VERSION ""

NS_ :

BS_:

BU_: ESM HIB HIP HIS SaGE CBC DASM DIAGNOST EBCM ECM EPS ESC ESL ETM HALF HCP IC OCM ORC PTS RF_HUB SCCM SGW

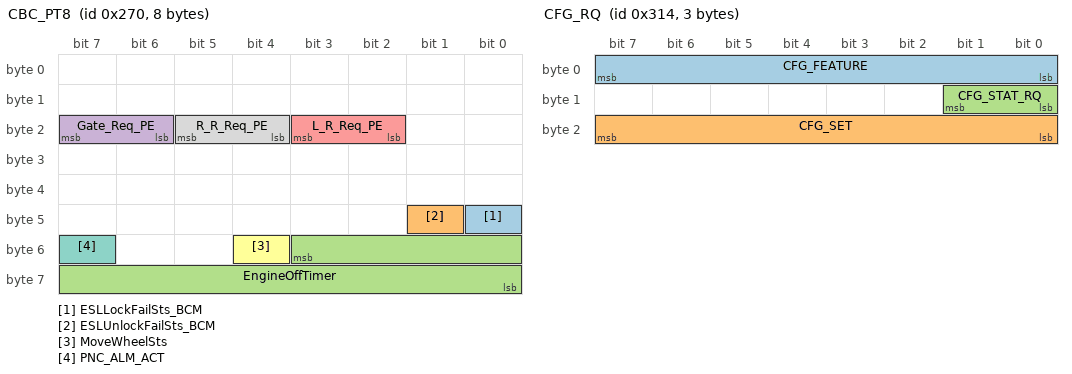
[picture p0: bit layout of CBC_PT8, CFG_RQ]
BO_ 624 CBC_PT8: 8 CBC
 SG_ ESLLockFailSts_BCM : 40|1@1+ (1,0) [0|0] ""  IC,SGW
 SG_ ESLUnlockFailSts_BCM : 41|1@1+ (1,0) [0|0] ""  IC,SGW
 SG_ EngineOffTimer : 51|12@0+ (1,0) [0|4080] "min"  ECM,ETM,SGW
 SG_ Gate_Req_PE : 22|2@1+ (1,0) [0|0] ""  RF_HUB,SGW
 SG_ L_R_Req_PE : 18|2@1+ (1,0) [0|0] ""  RF_HUB,SGW
 SG_ MoveWheelSts : 52|1@1+ (1,0) [0|0] ""  IC,SGW
 SG_ PNC_ALM_ACT : 55|1@1+ (1,0) [0|0] ""  SGW
 SG_ R_R_Req_PE : 20|2@1+ (1,0) [0|0] ""  RF_HUB,SGW

BO_ 456 CBC_VTA: 4 CBC
 SG_ VTA_STAT : 0|3@1+ (1,0) [0|0] ""  ETM,RF_HUB,SGW

BO_ 788 CFG_RQ: 3 CBC
 SG_ CFG_FEATURE : 0|8@1+ (1,0) [0|0] ""  DASM,ECM,ESC,HALF,IC,PTS,RF_HUB,SGW
 SG_ CFG_SET : 16|8@1+ (1,0) [0|255] ""  DASM,ECM,ESC,HALF,IC,PTS,RF_HUB,SGW
 SG_ CFG_STAT_RQ : 8|2@1+ (1,0) [0|0] ""  DASM,ECM,ESC,HALF,IC,PTS,RF_HUB,SGW

BO_ 856 COMPASS_A1: 4 CBC
 SG_ CMP_DIR : 0|4@1+ (1,0) [0|0] ""  IC,SGW

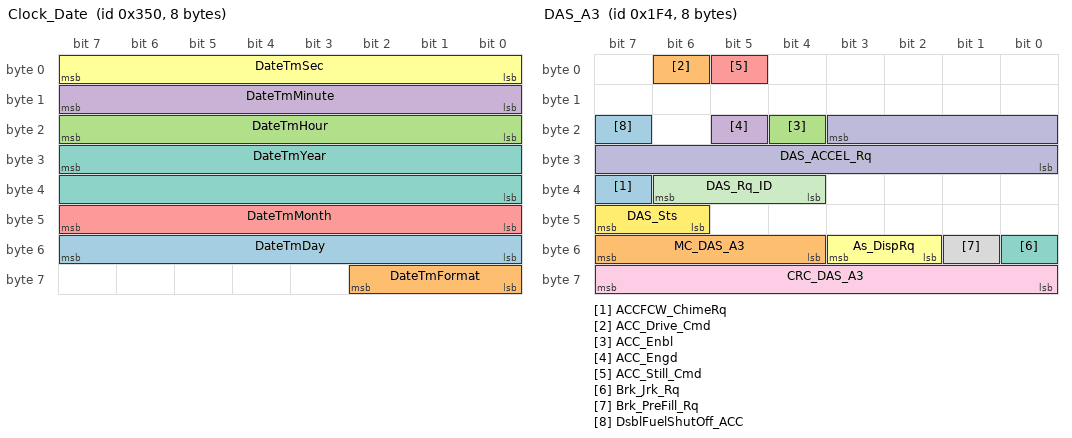
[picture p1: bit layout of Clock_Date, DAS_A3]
BO_ 848 Clock_Date: 8 CBC
 SG_ DateTmDay : 48|8@1+ (1,0) [1|31] "Days"  IC,RF_HUB,SGW
 SG_ DateTmFormat : 56|3@1+ (1,0) [0|0] ""  IC,SGW
 SG_ DateTmHour : 16|8@1+ (1,0) [0|23] "Hours"  IC,RF_HUB,SGW
 SG_ DateTmMinute : 8|8@1+ (1,0) [0|59] "min"  IC,RF_HUB,SGW
 SG_ DateTmMonth : 40|8@1+ (1,0) [1|12] "Months"  IC,RF_HUB,SGW
 SG_ DateTmSec : 0|8@1+ (1,0) [0|59] "sec"  IC,SGW
 SG_ DateTmYear : 31|16@0+ (1,0) [0|65534] "Years"  IC,RF_HUB,SGW

BO_ 500 DAS_A3: 8 DASM
 SG_ ACCFCW_ChimeRq : 39|1@1+ (1,0) [0|0] ""  IC,SGW
 SG_ ACC_Drive_Cmd : 6|1@1+ (1,0) [0|0] ""  SGW
 SG_ ACC_Enbl : 20|1@1+ (1,0) [0|0] ""  IC,SGW
 SG_ ACC_Engd : 21|1@1+ (1,0) [0|0] ""  IC,SGW
 SG_ ACC_Still_Cmd : 5|1@1+ (1,0) [0|0] ""  ORC,SGW
 SG_ As_DispRq : 50|2@1+ (1,0) [0|0] ""  HALF,IC,ORC,SGW
 SG_ Brk_Jrk_Rq : 48|1@1+ (1,0) [0|0] ""  SGW
 SG_ Brk_PreFill_Rq : 49|1@1+ (1,0) [0|0] ""  SGW
 SG_ CRC_DAS_A3 : 56|8@1+ (1,0) [0|0] ""  SGW
 SG_ DAS_ACCEL_Rq : 19|12@0+ (0.004885,-16) [-16|4] "m/s²"  ORC,SGW
 SG_ DAS_Rq_ID : 36|3@1+ (1,0) [0|0] ""  SGW
 SG_ DAS_Sts : 46|2@1+ (1,0) [0|0] ""  SGW
 SG_ DsblFuelShutOff_ACC : 23|1@1+ (1,0) [0|0] ""  SGW
 SG_ MC_DAS_A3 : 52|4@1+ (1,0) [0|15] ""  HIB,ECM,SGW

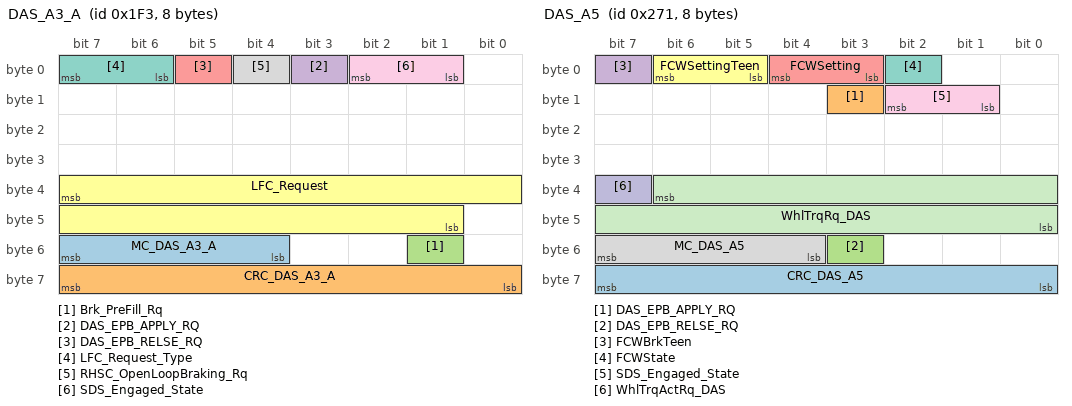
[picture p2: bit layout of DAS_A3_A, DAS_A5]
BO_ 499 DAS_A3_A: 8 HIB
 SG_ MC_DAS_A3_A : 52|4@1+ (1,0) [0|15] ""  EBCM,ESC
 SG_ CRC_DAS_A3_A : 56|8@1+ (1,0) [0|255] ""  EBCM,ESC
 SG_ Brk_PreFill_Rq : 49|1@1+ (1,0) [0|0] ""  SGW
 SG_ DAS_EPB_APPLY_RQ : 3|1@1+ (1,0) [0|0] "" Vector__XXX
 SG_ DAS_EPB_RELSE_RQ : 5|1@1+ (1,0) [0|0] "" Vector__XXX
 SG_ LFC_Request : 39|15@0+ (2,-65534) [-65534|0] ""  EBCM,ESC,SGW
 SG_ LFC_Request_Type : 6|2@1+ (1,0) [0|0] ""  EBCM,ESC,SGW
 SG_ RHSC_OpenLoopBraking_Rq : 4|1@1+ (1,0) [0|0] ""  EBCM,ESC,SGW
 SG_ SDS_Engaged_State : 1|2@1+ (1,0) [0|0] ""  EBCM,ESC

BO_ 501 DAS_A4: 8 DASM
 SG_ ACCFaulted : 50|1@1+ (1,0) [0|0] ""  ETM,IC,ORC,SGW
 SG_ ACCNA_DASMSts : 52|1@1+ (1,0) [0|0] ""  IC,SGW
 SG_ ACCOnOff : 36|3@1+ (1,0) [0|0] ""  IC,ORC,SGW
 SG_ ACC_HMI_SCRN_REQ : 31|1@1+ (1,0) [0|0] ""  IC,SGW
 SG_ ACConlyNA_DASMSts : 48|1@1+ (1,0) [0|0] ""  ETM,IC,SGW
 SG_ CIPV_Fused : 30|1@1+ (1,0) [0|0] ""  ORC,SGW
 SG_ CameraBlocked : 54|1@1+ (1,0) [0|0] ""  IC,SGW
 SG_ CameraFailure : 55|1@1+ (1,0) [0|0] ""  IC,SGW
 SG_ FCWBrakingOff : 47|1@1+ (1,0) [0|0] ""  IC,SGW
 SG_ FCW_BrkOn : 29|1@1+ (1,0) [0|0] ""  CBC,ORC,SGW
 SG_ FCW_Error : 26|2@1+ (1,0) [0|0] ""  ETM,IC,ORC,SGW
 SG_ FCWonlyNA_DASMSts : 51|1@1+ (1,0) [0|0] ""  IC,SGW
 SG_ HMI_Screens : 0|8@1+ (1,0) [0|254] "Text"  IC,SGW
 SG_ NCCNA_DASMSts : 53|1@1+ (1,0) [0|0] ""  IC,SGW
 SG_ NCConlyNA_DASMSts : 49|1@1+ (1,0) [0|0] ""  IC,SGW
 SG_ ObjIntrstDist : 56|8@1+ (1,0) [0|253] "m"  ORC,SGW
 SG_ RadarBlocked : 46|1@1+ (1,0) [0|0] ""  IC,ORC,SGW
 SG_ SetSpeed_KPH : 8|8@1+ (1,0) [0|250] "km/h"  ECM,IC,SGW
 SG_ SetSpeed_MPH : 16|8@1+ (1,0) [0|250] "mph"  IC,ORC,SGW
 SG_ Sm_ICON_Dspl : 40|6@1+ (1,0) [0|0] ""  IC,SGW

BO_ 625 DAS_A5: 8 DASM
 SG_ CRC_DAS_A5 : 56|8@1+ (1,0) [0|255] ""  SGW
 SG_ DAS_EPB_APPLY_RQ : 11|1@1+ (1,0) [0|0] ""  SGW
 SG_ DAS_EPB_RELSE_RQ : 51|1@1+ (1,0) [0|0] ""  HCP,SGW
 SG_ FCWBrkTeen : 7|1@1+ (1,0) [0|0] ""  CBC,ORC,SGW
 SG_ FCWSetting : 3|2@1+ (1,0) [0|0] ""  CBC,ORC,SGW
 SG_ FCWSettingTeen : 5|2@1+ (1,0) [0|0] ""  CBC,ORC,SGW
 SG_ FCWState : 2|1@1+ (1,0) [0|0] ""  CBC,IC,ORC,SGW
 SG_ MC_DAS_A5 : 52|4@1+ (1,0) [0|15] ""  SGW
 SG_ SDS_Engaged_State : 9|2@1+ (1,0) [0|0] ""  HCP,SGW
 SG_ WhlTrqActRq_DAS : 39|1@1+ (1,0) [0|0] ""  SGW
 SG_ WhlTrqRq_DAS : 38|15@0+ (1,-7767) [-7767|24999] "Nm"  SGW

BO_ 2015 DG_RQ_GLOBAL: 8 DIAGNOST
 SG_ DG_RQ_GLOBAL : 7|64@0+ (1,0) [0|0] ""  EBCM,ECM,ESC,ETM,HCP

BO_ 1089 DG_RQ_GLOBAL_UDS: 8 DIAGNOST
 SG_ DG_RQ_GLOBAL_UDS : 7|64@0+ (1,0) [0|0] ""  HIB,CBC,DASM,EBCM,ECM,EPS,ESC,ESL,ETM,HALF,HCP,IC,OCM,ORC,PTS,RF_HUB,SCCM

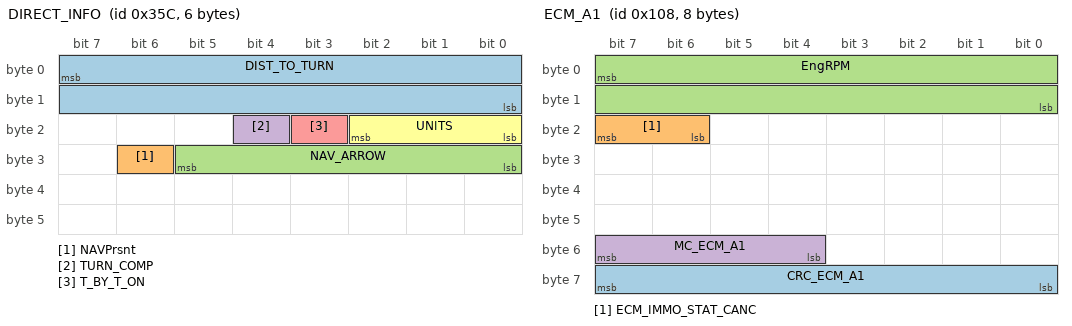
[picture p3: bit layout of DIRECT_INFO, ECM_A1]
BO_ 860 DIRECT_INFO: 6 CBC
 SG_ DIST_TO_TURN : 7|16@0+ (1,0) [0|65534] ""  IC,SGW
 SG_ NAVPrsnt : 30|1@1+ (1,0) [0|0] ""  IC,SGW
 SG_ NAV_ARROW : 24|6@1+ (1,0) [1|63] "Arrow"  IC,SGW
 SG_ TURN_COMP : 20|1@1+ (1,0) [0|0] ""  IC,SGW
 SG_ T_BY_T_ON : 19|1@1+ (1,0) [0|0] ""  IC,SGW
 SG_ UNITS : 16|3@1+ (1,0) [0|0] ""  IC,SGW

BO_ 1900 D_RQ_AHCP: 8 DIAGNOST
 SG_ D_RQ_AHCP : 7|64@0+ (1,0) [0|0] ""  HCP

BO_ 1898 D_RQ_APM: 8 DIAGNOST
 SG_ D_RQ_APM : 7|64@0+ (1,0) [0|0] ""  HCP

BO_ 2023 D_RQ_BPCM: 8 DIAGNOST
 SG_ D_RQ_BPCM : 7|64@0+ (1,0) [0|0] ""  HCP

BO_ 2020 D_RQ_BSMO: 8 DIAGNOST
 SG_ D_RQ_BSMO : 7|64@0+ (1,0) [0|0] ""  ESC

BO_ 1568 D_RQ_CBC: 8 DIAGNOST
 SG_ D_RQ_CBC : 7|64@0+ (1,0) [0|0] ""  CBC

BO_ 1875 D_RQ_DASM: 8 DIAGNOST
 SG_ D_RQ_DASM : 7|64@0+ (1,0) [0|0] ""  HIB,DASM

BO_ 1899 D_RQ_EAC: 8 DIAGNOST
 SG_ D_RQ_EAC : 7|64@0+ (1,0) [0|0] ""  HCP

BO_ 2019 D_RQ_EBCM: 8 DIAGNOST
 SG_ D_RQ_EBCM : 7|64@0+ (1,0) [0|0] ""  EBCM

BO_ 2016 D_RQ_ECM: 8 DIAGNOST
 SG_ D_RQ_ECM : 7|64@0+ (1,0) [0|0] ""  ECM

BO_ 1882 D_RQ_EPS: 8 DIAGNOST
 SG_ D_RQ_EPS : 7|64@0+ (1,0) [0|0] ""  EPS

BO_ 1864 D_RQ_ESL: 8 DIAGNOST
 SG_ D_RQ_ESL : 7|64@0+ (1,0) [0|0] ""  ESL

BO_ 1865 D_RQ_ESM: 8 DIAGNOST
 SG_ D_RQ_ESM : 7|64@0+ (1,0) [0|0] "" Vector__XXX

BO_ 2018 D_RQ_HCP: 8 DIAGNOST
 SG_ D_RQ_HCP : 7|64@0+ (1,0) [0|0] ""  HCP

BO_ 1892 D_RQ_HaLF: 8 DIAGNOST
 SG_ D_RQ_HaLF : 7|64@0+ (1,0) [0|0] ""  HALF

BO_ 1858 D_RQ_IC: 8 DIAGNOST
 SG_ D_RQ_IC : 7|64@0+ (1,0) [0|0] ""  IC

BO_ 1902 D_RQ_OBCM: 8 DIAGNOST
 SG_ D_RQ_OBCM : 7|64@0+ (1,0) [0|0] ""  HCP

BO_ 1886 D_RQ_OCM: 8 DIAGNOST
 SG_ D_RQ_OCM : 7|64@0+ (1,0) [0|0] ""  OCM

BO_ 1860 D_RQ_ORC: 8 DIAGNOST
 SG_ D_RQ_ORC : 7|64@0+ (1,0) [0|0] ""  ORC

BO_ 1890 D_RQ_PTS: 8 DIAGNOST
 SG_ D_RQ_PTS : 7|64@0+ (1,0) [0|0] ""  PTS

BO_ 1856 D_RQ_RF_HUB: 8 DIAGNOST
 SG_ D_RQ_RF_HUB : 7|64@0+ (1,0) [0|0] ""  RF_HUB

BO_ 1891 D_RQ_SCCM: 8 DIAGNOST
 SG_ D_RQ_SCCM : 7|64@0+ (1,0) [0|0] ""  SCCM

BO_ 1150 D_RQ_SGW: 8 DIAGNOST
 SG_ D_RQ_SGW : 7|64@0+ (1,0) [0|0] ""  SGW

BO_ 1260 D_RS_AHCP: 8 HCP
 SG_ D_RS_AHCP : 7|64@0+ (1,0) [0|0] ""  DIAGNOST,ETM,SGW

BO_ 1258 D_RS_APM: 8 HCP
 SG_ D_RS_APM : 7|64@0+ (1,0) [0|0] ""  DIAGNOST,ETM,SGW

BO_ 2031 D_RS_BPCM: 8 HCP
 SG_ D_RS_BPCM : 7|64@0+ (1,0) [0|0] ""  DIAGNOST,ETM,SGW

BO_ 2028 D_RS_BSMO: 8 ESC
 SG_ D_RS_BSMO : 7|64@0+ (1,0) [0|0] ""  DIAGNOST,ETM,SGW

BO_ 1284 D_RS_CBC: 8 CBC
 SG_ D_RS_CBC : 7|64@0+ (1,0) [0|0] ""  DIAGNOST,ETM,SGW

BO_ 1235 D_RS_DASM: 8 DASM
 SG_ D_RS_DASM : 7|64@0+ (1,0) [0|0] ""  DIAGNOST,ETM,SGW

BO_ 1259 D_RS_EAC: 8 HCP
 SG_ D_RS_EAC : 7|64@0+ (1,0) [0|0] ""  DIAGNOST,ETM,SGW

BO_ 2027 D_RS_EBCM: 8 EBCM
 SG_ D_RS_EBCM : 7|64@0+ (1,0) [0|0] ""  DIAGNOST,ETM,SGW

BO_ 2024 D_RS_ECM: 8 ECM
 SG_ D_RS_ECM : 7|64@0+ (1,0) [0|0] ""  DIAGNOST,ETM,SGW

BO_ 1242 D_RS_EPS: 8 EPS
 SG_ D_RS_EPS : 7|64@0+ (1,0) [0|0] ""  DIAGNOST,ETM,SGW

BO_ 1224 D_RS_ESL: 8 ESL
 SG_ D_RS_ESL : 7|64@0+ (1,0) [0|0] ""  DIAGNOST,SGW

BO_ 1225 D_RS_ESM: 8 ESM
 SG_ D_RS_ESM : 7|64@0+ (1,0) [0|0] ""  DIAGNOST,ETM,SGW

BO_ 2026 D_RS_HCP: 8 HCP
 SG_ D_RS_HCP : 7|64@0+ (1,0) [0|0] ""  DIAGNOST,ETM,SGW

BO_ 1252 D_RS_HaLF: 8 HALF
 SG_ D_RS_HaLF : 7|64@0+ (1,0) [0|0] ""  DIAGNOST,ETM,SGW

BO_ 1218 D_RS_IC: 8 IC
 SG_ D_RS_IC : 7|64@0+ (1,0) [0|0] ""  DIAGNOST,ETM,SGW

BO_ 1262 D_RS_OBCM: 8 HCP
 SG_ D_RS_OBCM : 7|64@0+ (1,0) [0|0] ""  DIAGNOST,ETM,SGW

BO_ 1246 D_RS_OCM: 8 OCM
 SG_ D_RS_OCM : 7|64@0+ (1,0) [0|0] ""  DIAGNOST,ETM,SGW

BO_ 1220 D_RS_ORC: 8 ORC
 SG_ D_RS_ORC : 7|64@0+ (1,0) [0|0] ""  DIAGNOST,ETM,SGW

BO_ 1250 D_RS_PTS: 8 PTS
 SG_ D_RS_PTS : 7|64@0+ (1,0) [0|0] ""  DIAGNOST,ETM,SGW

BO_ 1216 D_RS_RF_HUB: 8 RF_HUB
 SG_ D_RS_RF_HUB : 7|64@0+ (1,0) [0|0] ""  DIAGNOST,ETM,SGW

BO_ 1251 D_RS_SCCM: 8 SCCM
 SG_ D_RS_SCCM : 7|64@0+ (1,0) [0|0] ""  DIAGNOST,ETM,SGW

BO_ 1151 D_RS_SGW: 8 SGW
 SG_ D_RS_SGW : 7|64@0+ (1,0) [0|0] ""  DIAGNOST,ETM

BO_ 653 EBCM_C1: 8 EBCM
 SG_ BrakePedalApplied : 4|1@1+ (1,0) [0|0] ""  ECM,ESC,SGW
 SG_ BrakePedalAppliedV : 5|1@1+ (1,0) [0|0] ""  ECM,ESC,SGW
 SG_ BrakePedalTravelSensor : 8|8@1+ (0.4,0) [0|100] "%"  ECM,ESC,SGW
 SG_ BrakePedalTravelSensorV : 46|1@1+ (1,0) [0|0] ""  ECM,ESC,SGW
 SG_ BrakeSysStateSec : 19|3@1+ (1,0) [0|0] ""  ESC,SGW
 SG_ BrkPdl_Flt_2 : 31|1@1+ (1,0) [0|0] ""  SGW
 SG_ BrkPdl_Stat_2 : 22|2@1+ (1,0) [0|0] ""  SGW
 SG_ Brk_Stat_2 : 48|2@1+ (1,0) [0|0] ""  CBC,SGW
 SG_ CRC_EBCM_C1 : 56|8@1+ (1,0) [0|0] ""  ESC,SGW
 SG_ DAS_RqActv : 1|3@1+ (1,0) [0|0] ""  SGW
 SG_ DriverBrakingTrue_EBCM : 0|1@1+ (1,0) [0|0] ""  ESC,SGW
 SG_ EBCMSysEmsMlfAtv : 7|1@1+ (1,0) [0|0] ""  SGW
 SG_ EBCM_BrakeState : 16|3@1+ (1,0) [0|0] ""  ESC,SGW
 SG_ EstBrakeTorqueAppliedSec : 30|15@0+ (2,-65534) [-65534|0] "Nm"  SGW
 SG_ MC_EBCM_C1 : 52|4@1+ (1,0) [0|15] ""  ESC,SGW
 SG_ MIL_OnRq_EBCM : 6|1@1+ (1,0) [0|0] ""  ECM,SGW
 SG_ SDS_Engaged_State_EBCM : 50|2@1+ (1,0) [0|0] ""  SGW
 SG_ ThermalCapacitySec : 40|6@1+ (1.5873,0) [0|100] "%"  SGW

BO_ 264 ECM_A1: 8 ECM
 SG_ CRC_ECM_A1 : 56|8@1+ (1,0) [0|0] ""  HIB,DASM,ESC,HALF,SGW
 SG_ ECM_IMMO_STAT_CANC : 22|2@1+ (1,0) [0|0] ""  CBC,HCP,SGW
 SG_ EngRPM : 7|16@0+ (1,0) [0|65534] "rpm"  HIB,CBC,DASM,EBCM,EPS,ESC,ETM,HALF,IC,ORC,RF_HUB,SGW
 SG_ MC_ECM_A1 : 52|4@1+ (1,0) [0|15] ""  HIB,DASM,ESC,HALF,SGW

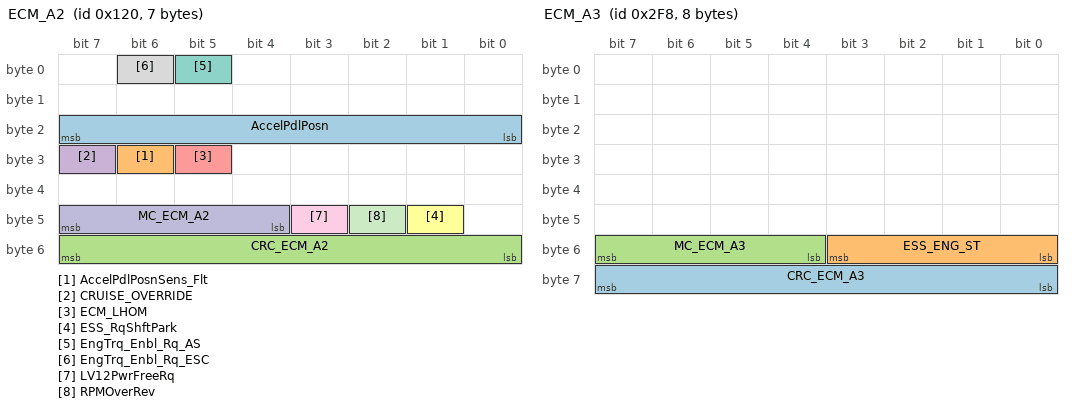
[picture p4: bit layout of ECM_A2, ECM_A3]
BO_ 288 ECM_A2: 7 ECM
 SG_ AccelPdlPosn : 16|8@1+ (0.4,0) [0|100] "%"  HIB,CBC,ESC,ETM,HALF,SGW
 SG_ AccelPdlPosnSens_Flt : 30|1@1+ (1,0) [0|0] ""  HIB,CBC,DASM,ESC,HALF,SGW
 SG_ CRC_ECM_A2 : 48|8@1+ (1,0) [0|0] ""  HIB,DASM,ESC,HALF,SGW
 SG_ CRUISE_OVERRIDE : 31|1@1+ (1,0) [0|0] ""  HIB,DASM,ESC,HCP,ORC,SGW
 SG_ ECM_LHOM : 29|1@1+ (1,0) [0|0] ""  HIB,DASM,SGW
 SG_ ESS_RqShftPark : 41|1@1+ (1,0) [0|0] ""  ORC,SGW
 SG_ EngTrq_Enbl_Rq_AS : 5|1@1+ (1,0) [0|0] ""  HIB,DASM,ESC,SGW
 SG_ EngTrq_Enbl_Rq_ESC : 6|1@1+ (1,0) [0|0] ""  HIB,DASM,ESC,SGW
 SG_ LV12PwrFreeRq : 43|1@1+ (1,0) [0|0] ""  HIB,DASM,ESC,SGW
 SG_ MC_ECM_A2 : 44|4@1+ (1,0) [0|15] ""  HIB,DASM,ESC,HALF,SGW
 SG_ RPMOverRev : 42|1@1+ (1,0) [0|0] ""  SGW

BO_ 760 ECM_A3: 8 ECM
 SG_ CRC_ECM_A3 : 56|8@1+ (1,0) [0|0] ""  ESC,PTS,SGW
 SG_ ESS_ENG_ST : 48|4@1+ (1,0) [0|0] ""  HIB,CBC,EPS,ESC,HALF,IC,ORC,PTS,SGW
 SG_ MC_ECM_A3 : 52|4@1+ (1,0) [0|15] ""  EPS,ESC,PTS,SGW

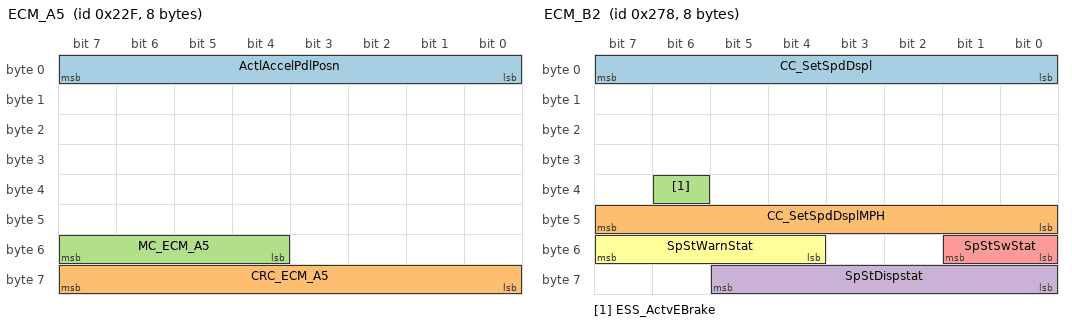
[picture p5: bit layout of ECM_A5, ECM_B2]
BO_ 559 ECM_A5: 8 ECM
 SG_ ActlAccelPdlPosn : 0|8@1+ (0.4,0) [0|100] "%"  HIB,DASM,ESC,ETM,HALF,ORC,SGW
 SG_ CRC_ECM_A5 : 56|8@1+ (1,0) [0|0] ""  HIB,DASM,ESC,SGW
 SG_ MC_ECM_A5 : 52|4@1+ (1,0) [0|15] ""  HIB,DASM,ESC,SGW

BO_ 864 ECM_APPL1: 8 ECM
 SG_ ECM_APPL1 : 7|64@0+ (1,0) [0|0] ""  DIAGNOST,SGW

BO_ 850 ECM_APPL2: 8 DIAGNOST
 SG_ ECM_APPL2 : 7|64@0+ (1,0) [0|0] ""  ECM

BO_ 880 ECM_APPL3: 8 ECM
 SG_ ECM_APPL3 : 7|64@0+ (1,0) [0|0] ""  DIAGNOST,SGW

BO_ 896 ECM_APPL4: 8 ECM
 SG_ ECM_APPL4 : 7|64@0+ (1,0) [0|0] ""  DIAGNOST,SGW

BO_ 912 ECM_APPL5: 8 ECM
 SG_ ECM_APPL5 : 7|64@0+ (1,0) [0|0] ""  DIAGNOST,SGW

BO_ 928 ECM_APPL6: 8 ECM
 SG_ ECM_APPL6 : 7|64@0+ (1,0) [0|0] ""  DIAGNOST,SGW

BO_ 936 ECM_APPL7: 8 ECM
 SG_ ECM_APPL7 : 7|64@0+ (1,0) [0|0] ""  DIAGNOST,SGW

BO_ 632 ECM_B2: 8 ECM
 SG_ CC_SetSpdDspl : 0|8@1+ (1,0) [0|250] "km/h"  IC,SGW
 SG_ CC_SetSpdDsplMPH : 40|8@1+ (1,0) [0|254] "mph"  IC,SGW
 SG_ ESS_ActvEBrake : 38|1@1+ (1,0) [0|0] ""  ESC,ORC,SGW
 SG_ SpStDispstat : 56|6@1+ (1,0) [0|0] ""  ETM,ORC,SGW
 SG_ SpStSwStat : 48|2@1+ (1,0) [0|0] ""  CBC,ETM,ORC,SGW
 SG_ SpStWarnStat : 52|4@1+ (1,0) [0|0] ""  ETM,ORC,SGW

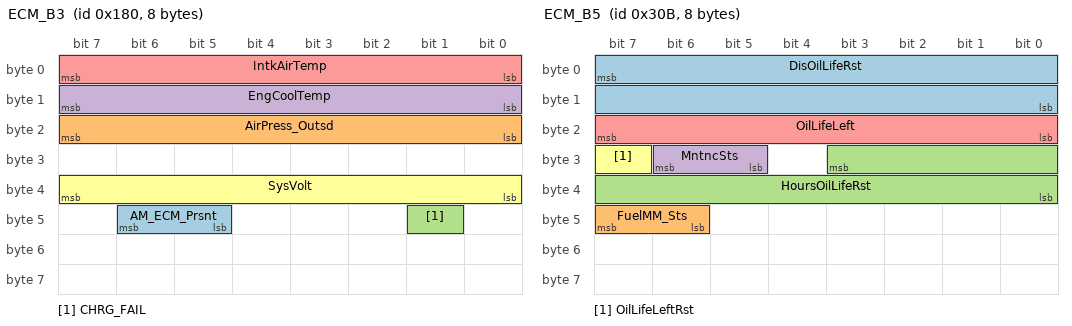
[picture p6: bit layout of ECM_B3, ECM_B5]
BO_ 384 ECM_B3: 8 ECM
 SG_ AM_ECM_Prsnt : 45|2@1+ (1,0) [0|0] ""  CBC,SGW
 SG_ AirPress_Outsd : 16|8@1+ (1,0) [0|254] "kPaA"  HIB,DASM,RF_HUB,SGW
 SG_ CHRG_FAIL : 41|1@1+ (1,0) [0|0] ""  ETM,IC,SGW
 SG_ EngCoolTemp : 8|8@1+ (1,-40) [-40|214] "°C"  CBC,ESC,ETM,IC,SGW
 SG_ IntkAirTemp : 0|8@1+ (1,-40) [-40|214] "°C"  ECM,SGW
 SG_ SysVolt : 32|8@1+ (0.0618,0) [0|15.6972] "Volts"  HCP,SGW

BO_ 779 ECM_B5: 8 ECM
 SG_ DisOilLifeRst : 7|16@0+ (1,0) [0|65534] "km"  CBC,IC,SGW
 SG_ FuelMM_Sts : 46|2@1+ (1,0) [0|0] ""  IC,SGW
 SG_ HoursOilLifeRst : 27|12@0+ (1,0) [0|4000] "Hours"  CBC,SGW
 SG_ MntncSts : 29|2@1+ (1,0) [0|0] ""  ETM,IC,SGW
 SG_ OilLifeLeft : 16|8@1+ (1,0) [0|100] "%"  ETM,IC,SGW
 SG_ OilLifeLeftRst : 31|1@1+ (1,0) [0|0] ""  ETM,IC,SGW

BO_ 703 ECM_B7: 8 ECM
 SG_ DrvAway_Alert : 7|1@1+ (1,0) [0|0] ""  IC,ORC,SGW
 SG_ DrvAway_Inhibit : 15|1@1+ (1,0) [0|0] ""  IC,SGW

BO_ 863 ECM_B8: 8 ECM
 SG_ RevOilLifeRst : 55|16@0+ (1000,0) [0|65534000] "Rev's"  CBC,SGW

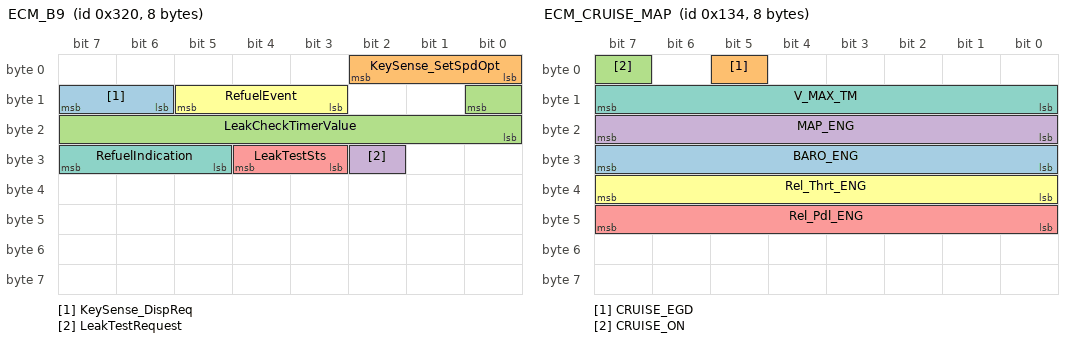
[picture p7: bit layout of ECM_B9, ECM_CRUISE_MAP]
BO_ 800 ECM_B9: 8 ECM
 SG_ KeySense_DispReq : 14|2@1+ (1,0) [0|0] ""  IC,SGW
 SG_ KeySense_SetSpdOpt : 0|3@1+ (1,0) [0|0] ""  HIB,CBC,DASM,IC,ORC,SGW
 SG_ LeakCheckTimerValue : 8|9@0+ (1,0) [0|510] "min"  CBC,SGW
 SG_ LeakTestRequest : 26|1@1+ (1,0) [0|0] ""  CBC,SGW
 SG_ LeakTestSts : 27|2@1+ (1,0) [0|0] ""  CBC,SGW
 SG_ RefuelEvent : 11|3@1+ (1,0) [0|0] ""  CBC,SGW
 SG_ RefuelIndication : 29|3@1+ (1,0) [0|0] ""  IC,SGW

BO_ 308 ECM_CRUISE_MAP: 8 ECM
 SG_ BARO_ENG : 24|8@1+ (1,0) [0|254] "kPaA"  ESC,ETM,SGW
 SG_ CRUISE_EGD : 5|1@1+ (1,0) [0|0] ""  CBC,ESC,HCP,IC,ORC,SGW
 SG_ CRUISE_ON : 7|1@1+ (1,0) [0|0] ""  ESC,IC,ORC,SGW
 SG_ MAP_ENG : 16|8@1+ (0.8,0) [0|203.2] "kPa"  ESC,ETM,SGW
 SG_ Rel_Pdl_ENG : 40|8@1+ (0.019607843,0) [0|4.98] "Volts"  ESC,ETM,SGW
 SG_ Rel_Thrt_ENG : 32|8@1+ (0.019607843,0) [0|4.98] "Volts"  ESC,ETM,SGW
 SG_ V_MAX_TM : 8|8@1+ (1,0) [0|250] "km/h(mph)"  HCP,SGW

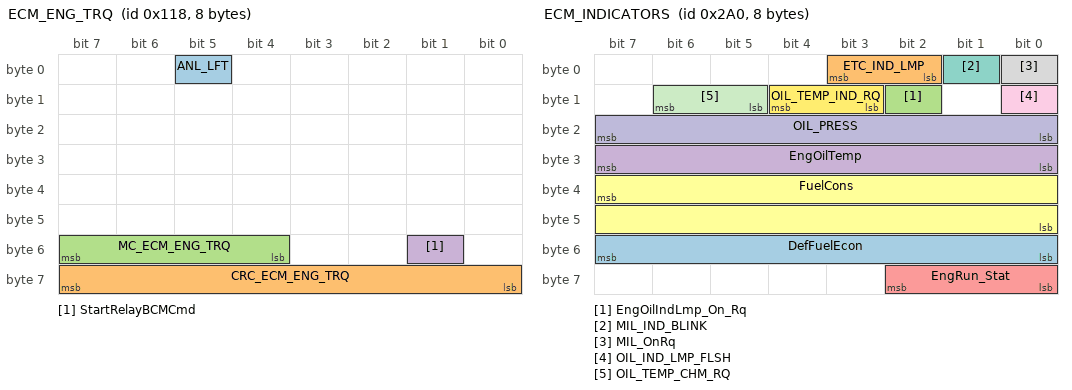
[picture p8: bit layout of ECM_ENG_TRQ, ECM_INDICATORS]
BO_ 280 ECM_ENG_TRQ: 8 ECM
 SG_ ANL_LFT : 5|1@1+ (1,0) [0|0] ""  CBC,SGW
 SG_ CRC_ECM_ENG_TRQ : 56|8@1+ (1,0) [0|0] ""  HIB,DASM,ESC,SGW
 SG_ MC_ECM_ENG_TRQ : 52|4@1+ (1,0) [0|15] ""  ESC,SGW
 SG_ StartRelayBCMCmd : 49|1@1+ (1,0) [0|0] ""  CBC,SGW

BO_ 290 ECM_GEAR: 6 ECM
 SG_ GrMax_Rq_ECM : 19|3@1+ (1,0) [0|0] ""  SGW
 SG_ NMOTS : 39|16@0+ (1,0) [0|65534] "rpm"  ESC,SGW

BO_ 672 ECM_INDICATORS: 8 ECM
 SG_ DefFuelEcon : 48|8@1+ (0.2,0) [0|50] "kmpl"  IC,SGW
 SG_ ETC_IND_LMP : 2|2@1+ (1,0) [0|0] ""  CBC,ETM,IC,SGW
 SG_ EngOilIndLmp_On_Rq : 10|1@1+ (1,0) [0|0] ""  CBC,ETM,IC,SGW
 SG_ EngOilTemp : 24|8@1+ (1,-40) [-40|160] "°C"  EPS,ETM,IC,SGW
 SG_ EngRun_Stat : 56|3@1+ (1,0) [0|0] ""  CBC,ESC,IC,PTS,RF_HUB,SGW
 SG_ FuelCons : 39|16@0+ (0.21668,0) [0|14200] "µl/100ms"  ETM,IC,SGW
 SG_ MIL_IND_BLINK : 1|1@1+ (1,0) [0|0] ""  CBC,IC,ORC,SGW
 SG_ MIL_OnRq : 0|1@1+ (1,0) [0|0] ""  CBC,ETM,IC,ORC,SGW
 SG_ OIL_IND_LMP_FLSH : 8|1@1+ (1,0) [0|0] ""  ETM,IC,SGW
 SG_ OIL_PRESS : 16|8@1+ (4,0) [0|1016] "kPaG"  ETM,IC,SGW
 SG_ OIL_TEMP_CHM_RQ : 13|2@1+ (1,0) [0|0] ""  IC,SGW
 SG_ OIL_TEMP_IND_RQ : 11|2@1+ (1,0) [0|0] ""  ETM,IC,SGW

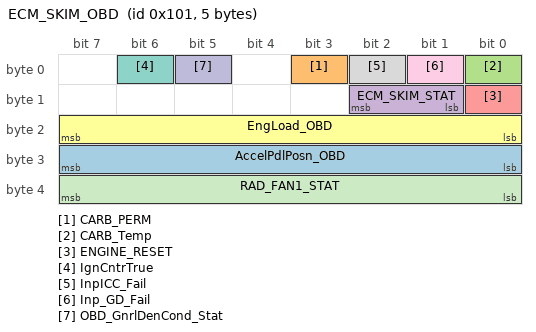
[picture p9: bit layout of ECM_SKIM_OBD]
BO_ 257 ECM_SKIM_OBD: 5 ECM
 SG_ AccelPdlPosn_OBD : 24|8@1+ (0.3922,0) [0|100] "%"  EBCM,ESC,ETM,SGW
 SG_ CARB_PERM : 3|1@1+ (1,0) [0|0] ""  SGW
 SG_ CARB_Temp : 0|1@1+ (1,0) [0|0] ""  SGW
 SG_ ECM_SKIM_STAT : 9|2@1+ (1,0) [0|0] ""  SGW
 SG_ ENGINE_RESET : 8|1@1+ (1,0) [0|0] ""  HCP,SGW
 SG_ EngLoad_OBD : 16|8@1+ (0.3922,0) [0|100] "%"  EBCM,ESC,ETM,SGW
 SG_ IgnCntrTrue : 6|1@1+ (1,0) [0|0] ""  SGW
 SG_ InpICC_Fail : 2|1@1+ (1,0) [0|0] ""  SGW
 SG_ Inp_GD_Fail : 1|1@1+ (1,0) [0|0] ""  SGW
 SG_ OBD_GnrlDenCond_Stat : 5|1@1+ (1,0) [0|0] ""  SGW
 SG_ RAD_FAN1_STAT : 32|8@1+ (1,0) [0|100] "%"  ETM,SGW

BO_TX_BU_ 2015 : DIAGNOST,SGW;
BO_TX_BU_ 1089 : DIAGNOST,SGW;
BO_TX_BU_ 1900 : DIAGNOST,ETM,SGW;
BO_TX_BU_ 1898 : DIAGNOST,ETM,SGW;
BO_TX_BU_ 2023 : DIAGNOST,ETM,SGW;
BO_TX_BU_ 2020 : DIAGNOST,ETM,SGW;
BO_TX_BU_ 1568 : DIAGNOST,ETM,SGW;
BO_TX_BU_ 1875 : DIAGNOST,ETM,SGW;
BO_TX_BU_ 1899 : DIAGNOST,ETM,SGW;
BO_TX_BU_ 2019 : DIAGNOST,ETM,SGW;
BO_TX_BU_ 2016 : DIAGNOST,ETM,SGW;
BO_TX_BU_ 1882 : DIAGNOST,ETM,SGW;
BO_TX_BU_ 1864 : DIAGNOST,SGW;
BO_TX_BU_ 1865 : DIAGNOST,ETM,SGW;
BO_TX_BU_ 2018 : DIAGNOST,ETM,SGW;
BO_TX_BU_ 1892 : DIAGNOST,ETM,SGW;
BO_TX_BU_ 1858 : DIAGNOST,ETM,SGW;
BO_TX_BU_ 1902 : DIAGNOST,ETM,SGW;
BO_TX_BU_ 1886 : DIAGNOST,ETM,SGW;
BO_TX_BU_ 1860 : DIAGNOST,ETM,SGW;
BO_TX_BU_ 1890 : DIAGNOST,ETM,SGW;
BO_TX_BU_ 1856 : DIAGNOST,ETM,SGW;
BO_TX_BU_ 1891 : DIAGNOST,ETM,SGW;
BO_TX_BU_ 1150 : DIAGNOST,ETM,SGW;
BO_TX_BU_ 850 : DIAGNOST,SGW;
CM_ SG_ 624 ESLLockFailSts_BCM "Display info on failed lock; Failed = [1]";
CM_ SG_ 624 ESLUnlockFailSts_BCM "Display info on failed unlock; Failed = [1]";
CM_ SG_ 624 EngineOffTimer "Engine off timer - engine off ignition NOT lock.";
CM_ SG_ 624 Gate_Req_PE "Gate passive entry requested; True = [1]";
CM_ SG_ 624 L_R_Req_PE "Left rear passive entry requested; True = [1]";
CM_ SG_ 624 MoveWheelSts "Display message to move steering wheel; Active = [1]";
CM_ SG_ 624 PNC_ALM_ACT "Panic alarm active; [1] = True";
CM_ SG_ 624 R_R_Req_PE "Right rear passive entry requested; True = [1]";
CM_ SG_ 456 VTA_STAT "VTA status";
CM_ SG_ 788 CFG_FEATURE "Configurable feature";
CM_ SG_ 788 CFG_SET "Specific setting or value (see reference)";
CM_ SG_ 788 CFG_STAT_RQ "Configurable feature status request";
CM_ SG_ 856 CMP_DIR "Compass direction (WK/LX)";
CM_ SG_ 848 DateTmDay "Day";
CM_ SG_ 848 DateTmFormat "Date and Time Format";
CM_ SG_ 848 DateTmHour "Time of day: HOURS";
CM_ SG_ 848 DateTmMinute "Time of day: MINUTES";
CM_ SG_ 848 DateTmMonth "Month";
CM_ SG_ 848 DateTmSec "Time of day: SECONDS";
CM_ SG_ 848 DateTmYear "Date year";
CM_ SG_ 500 ACCFCW_ChimeRq "ACC FCW chime request active; Active = [1]";
CM_ SG_ 500 ACC_Drive_Cmd "ACC drive off commanded; True = [1]";
CM_ SG_ 500 ACC_Enbl "ACC cruise control enabled; True = [1]";
CM_ SG_ 500 ACC_Engd "ACC engaged; True = [1]";
CM_ SG_ 500 ACC_Still_Cmd "ACC stop commanded; True = [1]";
CM_ SG_ 500 As_DispRq "Assistance system display request (priority)";
CM_ SG_ 500 Brk_Jrk_Rq "Brake jerk request; True = [1]";
CM_ SG_ 500 Brk_PreFill_Rq "Brakes pre-fill request; True = [1]";
CM_ SG_ 500 CRC_DAS_A3 "CRC-checksum byte 1 to 7 according to SAE J1850";
CM_ SG_ 500 DAS_ACCEL_Rq "DASM acceleration request";
CM_ SG_ 500 DAS_Rq_ID "DAS request ID";
CM_ SG_ 500 DAS_Sts "DASM fault status";
CM_ SG_ 500 DsblFuelShutOff_ACC "Disable fuel shutoff; True = [1]";
CM_ SG_ 500 MC_DAS_A3 "Message counter";
CM_ SG_ 499 Brk_PreFill_Rq "Brakes pre-fill request; True = [1]";
CM_ SG_ 499 DAS_EPB_APPLY_RQ "DAS request to apply EPB";
CM_ SG_ 499 DAS_EPB_RELSE_RQ "DAS request to release EPB";
CM_ SG_ 499 LFC_Request_Type "Longitudinal Force Control Request Type";
CM_ SG_ 499 RHSC_OpenLoopBraking_Rq "Longitudinal Force Control Open Loop Braking Request";
CM_ SG_ 499 SDS_Engaged_State "SDS Engaged Status";
CM_ SG_ 501 ACCFaulted "ACC faulted; True = [1]";
CM_ SG_ 501 ACCNA_DASMSts "ACC/FCW not avail: vehicle system error; True = [1]";
CM_ SG_ 501 ACCOnOff "ACC on off status";
CM_ SG_ 501 ACC_HMI_SCRN_REQ "ACC HMI Screen request. Display HMI screen when [1]";
CM_ SG_ 501 ACConlyNA_DASMSts "ACC only not available: vehicle system error; True = [1]";
CM_ SG_ 501 CIPV_Fused "Closest in-path vehicle is fused; True = [1]";
CM_ SG_ 501 CameraBlocked "ACC FCW limited functionality: camera blocked; True = [1]";
CM_ SG_ 501 CameraFailure "ACC/FCW limited functionality: camera failure; True = [1]";
CM_ SG_ 501 FCWBrakingOff "FCW autobraking disabled; True = [1]";
CM_ SG_ 501 FCW_BrkOn "FCW braking is on; true = [1]";
CM_ SG_ 501 FCW_Error "Forward collision warning error";
CM_ SG_ 501 FCWonlyNA_DASMSts "FCW only not available: vehicle system error; True = [1]";
CM_ SG_ 501 HMI_Screens "HMI screens";
CM_ SG_ 501 NCCNA_DASMSts "NCC/FCW not avail: vehicle system error; True = [1]";
CM_ SG_ 501 NCConlyNA_DASMSts "NCC only not available: vehicle system error; True = [1]";
CM_ SG_ 501 ObjIntrstDist "Object of interest distance";
CM_ SG_ 501 RadarBlocked "ACC FCW not available: clean radar snsr; True = [1]";
CM_ SG_ 501 SetSpeed_KPH "Desired set speed in kilometers per hour";
CM_ SG_ 501 SetSpeed_MPH "Desired set speed in miles per hour";
CM_ SG_ 501 Sm_ICON_Dspl "Small graphic display";
CM_ SG_ 625 CRC_DAS_A5 "CRC-checksum byte 1 to 7 according to SAE J1850";
CM_ SG_ 625 DAS_EPB_APPLY_RQ "DAS request to apply EPB";
CM_ SG_ 625 DAS_EPB_RELSE_RQ "DAS request to apply EPB";
CM_ SG_ 625 FCWBrkTeen "FCW braking is on for teen key; true = [1]";
CM_ SG_ 625 FCWSetting "Forward collision warning sensitivity setting";
CM_ SG_ 625 FCWSettingTeen "Forward collision warning sensitivity setting teen key";
CM_ SG_ 625 FCWState "FCW system operating state; On = [1]";
CM_ SG_ 625 MC_DAS_A5 "Message counter";
CM_ SG_ 625 SDS_Engaged_State "SDS Engaged Status";
CM_ SG_ 625 WhlTrqActRq_DAS "Wheel torque request active; True = [1]";
CM_ SG_ 625 WhlTrqRq_DAS "Requested wheel torque";
CM_ SG_ 2015 DG_RQ_GLOBAL "Diagnostic-Request";
CM_ SG_ 1089 DG_RQ_GLOBAL_UDS "Diagnostic-Request";
CM_ SG_ 860 DIST_TO_TURN "Numeric distance to next turn";
CM_ SG_ 860 NAVPrsnt "A navigation system module is present";
CM_ SG_ 860 NAV_ARROW "Navigation arrow type";
CM_ SG_ 860 TURN_COMP "Turn complete";
CM_ SG_ 860 T_BY_T_ON "Turn by turn on";
CM_ SG_ 860 UNITS "Unit of measure";
CM_ SG_ 1900 D_RQ_AHCP "Diagnostic-Request";
CM_ SG_ 1898 D_RQ_APM "Diagnostic-Request";
CM_ SG_ 2023 D_RQ_BPCM "Diagnostic-Request";
CM_ SG_ 2020 D_RQ_BSMO "Diagnostic-Request";
CM_ SG_ 1568 D_RQ_CBC "Diagnostic-Request";
CM_ SG_ 1875 D_RQ_DASM "Diagnostic-Request";
CM_ SG_ 1899 D_RQ_EAC "Diagnostic-Request";
CM_ SG_ 2019 D_RQ_EBCM "Diagnostic-Request";
CM_ SG_ 2016 D_RQ_ECM "Diagnostic-Request";
CM_ SG_ 1882 D_RQ_EPS "Diagnostic-Request";
CM_ SG_ 1864 D_RQ_ESL "Diagnostic-Request";
CM_ SG_ 1865 D_RQ_ESM "Diagnostic-Request";
CM_ SG_ 2018 D_RQ_HCP "Diagnostic-Request";
CM_ SG_ 1892 D_RQ_HaLF "Diagnostic-Request";
CM_ SG_ 1858 D_RQ_IC "Diagnostic-Request";
CM_ SG_ 1902 D_RQ_OBCM "Diagnostic-Request";
CM_ SG_ 1886 D_RQ_OCM "Diagnostic-Request";
CM_ SG_ 1860 D_RQ_ORC "Diagnostic-Request";
CM_ SG_ 1890 D_RQ_PTS "Diagnostic-Request";
CM_ SG_ 1856 D_RQ_RF_HUB "Diagnostic-Request";
CM_ SG_ 1891 D_RQ_SCCM "Diagnostic-Request";
CM_ SG_ 1150 D_RQ_SGW "Diagnostic-Request";
CM_ SG_ 1260 D_RS_AHCP "Diagnostic-Response";
CM_ SG_ 1258 D_RS_APM "Diagnostic-Response";
CM_ SG_ 2031 D_RS_BPCM "Diagnostic-Response";
CM_ SG_ 2028 D_RS_BSMO "Diagnostic-Response";
CM_ SG_ 1284 D_RS_CBC "Diagnostic-Response";
CM_ SG_ 1235 D_RS_DASM "Diagnostic-Response";
CM_ SG_ 1259 D_RS_EAC "Diagnostic-Response";
CM_ SG_ 2027 D_RS_EBCM "Diagnostic-Response";
CM_ SG_ 2024 D_RS_ECM "Diagnostic-Response";
CM_ SG_ 1242 D_RS_EPS "Diagnostic-Response";
CM_ SG_ 1224 D_RS_ESL "Diagnostic-Response";
CM_ SG_ 1225 D_RS_ESM "Diagnostic-Response";
CM_ SG_ 2026 D_RS_HCP "Diagnostic-Response";
CM_ SG_ 1252 D_RS_HaLF "Diagnostic-Response";
CM_ SG_ 1218 D_RS_IC "Diagnostic-Response";
CM_ SG_ 1262 D_RS_OBCM "Diagnostic-Response";
CM_ SG_ 1246 D_RS_OCM "Diagnostic-Response";
CM_ SG_ 1220 D_RS_ORC "Diagnostic-Response";
CM_ SG_ 1250 D_RS_PTS "Diagnostic-Response";
CM_ SG_ 1216 D_RS_RF_HUB "Diagnostic-Response";
CM_ SG_ 1251 D_RS_SCCM "Diagnostic-Response";
CM_ SG_ 1151 D_RS_SGW "Diagnostic-Response";
CM_ SG_ 653 BrakePedalApplied "driver operates the brake pedal";
CM_ SG_ 653 BrakePedalAppliedV "Validity bit";
CM_ SG_ 653 BrakePedalTravelSensor "Brake pedal travel sensor 0-100% (0 = upstop)";
CM_ SG_ 653 BrakePedalTravelSensorV "Brake pedal travel sensor valid (1 = valid data)";
CM_ SG_ 653 BrakeSysStateSec "EBCM Brake State from Secondary actuator";
CM_ SG_ 653 BrkPdl_Flt_2 "Brake pedal fault is active; True = [1]";
CM_ SG_ 653 BrkPdl_Stat_2 "Brake pedal state";
CM_ SG_ 653 Brk_Stat_2 "Brake state";
CM_ SG_ 653 CRC_EBCM_C1 "CRC-checksum byte 1 to 7 according to SAE J1850";
CM_ SG_ 653 DAS_RqActv "DAS request active";
CM_ SG_ 653 DriverBrakingTrue_EBCM "Driver operates the brake pedal; Pressed = [1]";
CM_ SG_ 653 EBCMSysEmsMlfAtv "EBCM emissions related malfunction active";
CM_ SG_ 653 EBCM_BrakeState "EBCM Brake State";
CM_ SG_ 653 MC_EBCM_C1 "Message counter";
CM_ SG_ 653 MIL_OnRq_EBCM "MIL on request from the EBCM";
CM_ SG_ 653 SDS_Engaged_State_EBCM "SDS Engaged Status";
CM_ SG_ 264 CRC_ECM_A1 "CRC-checksum byte 1 to 7 according to SAE J1850";
CM_ SG_ 264 ECM_IMMO_STAT_CANC "ECM immobilizer status";
CM_ SG_ 264 EngRPM "Engine revolutions per minute";
CM_ SG_ 264 MC_ECM_A1 "Message counter";
CM_ SG_ 288 AccelPdlPosn "Throttle Pedal Position (Calculated)";
CM_ SG_ 288 AccelPdlPosnSens_Flt "Accelerator pedal position sensor fault";
CM_ SG_ 288 CRC_ECM_A2 "CRC-checksum byte 1 to 6 according to SAE J1850";
CM_ SG_ 288 CRUISE_OVERRIDE "Driver is over-riding cruise set speed";
CM_ SG_ 288 ECM_LHOM "Engine in limp home mode";
CM_ SG_ 288 ESS_RqShftPark "ESS Request shift to Park.  1 = True, 0 = False";
CM_ SG_ 288 EngTrq_Enbl_Rq_AS "Allow LCM torque requests";
CM_ SG_ 288 EngTrq_Enbl_Rq_ESC "Allow ESC torque request";
CM_ SG_ 288 LV12PwrFreeRq "Level 1 or 2 power free request - engine controller has depowered the throttle body";
CM_ SG_ 288 MC_ECM_A2 "Message counter";
CM_ SG_ 288 RPMOverRev "RPM Overrev condition has occurred";
CM_ SG_ 760 CRC_ECM_A3 "CRC-checksum byte 1 to 7 according to SAE J1850";
CM_ SG_ 760 ESS_ENG_ST "ESS Engine State";
CM_ SG_ 760 MC_ECM_A3 "Message counter";
CM_ SG_ 559 ActlAccelPdlPosn "Throttle Pedal Position (actual)";
CM_ SG_ 559 CRC_ECM_A5 "CRC-checksum byte 1 to 7 according to SAE J1850";
CM_ SG_ 559 MC_ECM_A5 "Message counter";
CM_ SG_ 864 ECM_APPL1 "Application";
CM_ SG_ 850 ECM_APPL2 "Application";
CM_ SG_ 880 ECM_APPL3 "CCP synchronous - TDC event DAQ";
CM_ SG_ 896 ECM_APPL4 "CCP 5ms DAQ  (from ENGINE to external tool)";
CM_ SG_ 912 ECM_APPL5 "CCP 10ms DAQ  (from ENGINE to external tool)";
CM_ SG_ 928 ECM_APPL6 "CCP 80ms DAQ  (from ENGINE to external tool)";
CM_ SG_ 936 ECM_APPL7 "Application";
CM_ SG_ 632 CC_SetSpdDspl "Cruise control set speed for display (kmph only)";
CM_ SG_ 632 CC_SetSpdDsplMPH "Cruise control set speed for display in miles per hour";
CM_ SG_ 632 ESS_ActvEBrake "ESS active E-brake. 1 = Active, 0 = Inactive";
CM_ SG_ 632 SpStDispstat "Stop start display status";
CM_ SG_ 632 SpStSwStat "Stop start switch status";
CM_ SG_ 632 SpStWarnStat "Stop start warning status";
CM_ SG_ 384 AM_ECM_Prsnt "Aftermarket ECM present";
CM_ SG_ 384 AirPress_Outsd "Ambient air pressure (barometric pressure)";
CM_ SG_ 384 CHRG_FAIL "Charging system Failure (battery indicator request)";
CM_ SG_ 384 EngCoolTemp "Engine coolant temperature";
CM_ SG_ 384 IntkAirTemp "Engine Intake Air Temperature";
CM_ SG_ 384 SysVolt "Engine system voltage";
CM_ SG_ 779 DisOilLifeRst "Distance since last oil life reset";
CM_ SG_ 779 FuelMM_Sts "Fuel maintenance mode status";
CM_ SG_ 779 HoursOilLifeRst "Hours since last oil life reset";
CM_ SG_ 779 MntncSts "Maintenance reminder status";
CM_ SG_ 779 OilLifeLeft "Oil life left";
CM_ SG_ 779 OilLifeLeftRst "Oil life remaining has been reset";
CM_ SG_ 703 DrvAway_Alert "Drive Away Alert; True = [1]";
CM_ SG_ 703 DrvAway_Inhibit "Drive Away Inhibit; True = [1]";
CM_ SG_ 863 RevOilLifeRst "Engine revolutions since last oil life reset";
CM_ SG_ 800 KeySense_DispReq "Key sense cluster EVIC request";
CM_ SG_ 800 KeySense_SetSpdOpt "Key sense max speed option for ECM speed limiting";
CM_ SG_ 800 LeakCheckTimerValue "Requested leak test timer value";
CM_ SG_ 800 LeakTestRequest "Leak test is requested after powerdown; No request = [0], Leak test requested = [1]";
CM_ SG_ 800 LeakTestSts "Status of leak test";
CM_ SG_ 800 RefuelEvent "Status of refuel event";
CM_ SG_ 800 RefuelIndication "Indication to the driver about the status of the refuel system";
CM_ SG_ 308 BARO_ENG "Ambient air pressure (barometric pressure)";
CM_ SG_ 308 CRUISE_EGD "Cruise system is controlling speed";
CM_ SG_ 308 CRUISE_ON "Cruise control system 'on'";
CM_ SG_ 308 MAP_ENG "Intake manifold pressure, extended rangeEDR ONLY - Intake manifold pressure";
CM_ SG_ 308 Rel_Pdl_ENG "Relative pedal value";
CM_ SG_ 308 Rel_Thrt_ENG "Relative throttle value";
CM_ SG_ 308 V_MAX_TM "Max. or cruise control set speed";
CM_ SG_ 280 ANL_LFT "Starter motor running (Cranking)";
CM_ SG_ 280 CRC_ECM_ENG_TRQ "CRC-checksum byte 1 to 7 according to SAE J1850";
CM_ SG_ 280 MC_ECM_ENG_TRQ "Message counter";
CM_ SG_ 280 StartRelayBCMCmd "Engine restart request for StopStart function";
CM_ SG_ 290 GrMax_Rq_ECM "Target gear upper limit (ECM requested limit)";
CM_ SG_ 290 NMOTS "Target idle speed";
CM_ SG_ 672 DefFuelEcon "Default fuel economy";
CM_ SG_ 672 ETC_IND_LMP "ETC faulty, indicator lamp request";
CM_ SG_ 672 EngOilIndLmp_On_Rq "Request oil level/oil pressure indicator lamp";
CM_ SG_ 672 EngOilTemp "Oil temperature";
CM_ SG_ 672 EngRun_Stat "Engine running state";
CM_ SG_ 672 FuelCons "Fuel consumption";
CM_ SG_ 672 MIL_IND_BLINK "Request MIL blink (OBD II)";
CM_ SG_ 672 MIL_OnRq "MIL on request from the engine";
CM_ SG_ 672 OIL_IND_LMP_FLSH "Oil indicator lamp flash (for in plant use)";
CM_ SG_ 672 OIL_PRESS "Oil pressure";
CM_ SG_ 672 OIL_TEMP_CHM_RQ "Engine oil overtemp. chime request";
CM_ SG_ 672 OIL_TEMP_IND_RQ "Engine oil overtemp. indicator request";
CM_ SG_ 257 AccelPdlPosn_OBD "Pedal value for OBD (ISO 15031-5.4 PID 49)";
CM_ SG_ 257 CARB_PERM "CARB permanent fault code drive cycle";
CM_ SG_ 257 CARB_Temp "CARB warmup criteria is true [1]";
CM_ SG_ 257 ECM_SKIM_STAT "ECM Skim Status";
CM_ SG_ 257 ENGINE_RESET "ECM Reset Notification";
CM_ SG_ 257 EngLoad_OBD "Load value for OBD (ISO 15031-5.4 PID 4)";
CM_ SG_ 257 IgnCntrTrue "Ignition cycle counter is true [1]";
CM_ SG_ 257 InpICC_Fail "Inputs to the Ign Cycle Cntr are in a Pend or MIL cond.";
CM_ SG_ 257 Inp_GD_Fail "Inputs to the general denominator are in a pend or MIL fault.";
CM_ SG_ 257 OBD_GnrlDenCond_Stat "General denominator conditions are met [1].";
CM_ SG_ 257 RAD_FAN1_STAT "Low speed or single radiator fan requested duty cycle";
BA_DEF_ BO_  "App-Botschaft" ENUM  "nein","ja";
BA_DEF_ BO_  "CanMsgMinLen" INT 0 8;
BA_DEF_ BO_  "DiagRequest" ENUM  "nein","ja";
BA_DEF_ BO_  "DiagResponse" ENUM  "nein","ja";
BA_DEF_ BO_  "DiagState" ENUM  "nein","ja";
BA_DEF_ BO_  "GenMsgCycleTime" INT 0 65535;
BA_DEF_ BO_  "GenMsgCycleTimeActive" INT 0 65535;
BA_DEF_ BO_  "GenMsgDelayTime" INT 0 65535;
BA_DEF_ BO_  "GenMsgNrOfRepetitions" INT 0 65535;
BA_DEF_ BO_  "GenMsgSendType" ENUM  "cyclicX","spontanX","cyclicIfActiveX","spontanWithDelay","cyclicAndSpontanX","cyclicAndSpontanWithDelay","spontanWithRepitition","cyclicIfActiveAndSpontanWD","cyclicIfActiveFast","cyclicWithRepeatOnDemand","none";
BA_DEF_ BO_  "GenMsgStartDelayTime" INT 0 65535;
BA_DEF_ BO_  "GenMsgStartValue" STRING ;
BA_DEF_ BO_  "NWM-Botschaft" ENUM  "nein","ja";
BA_DEF_ BO_  "TpTxIndex" INT 0 99;
BA_DEF_ SG_  "FlexKomComment" STRING ;
BA_DEF_ SG_  "FlexKomIsMotorola" ENUM  "nein","ja";
BA_DEF_ SG_  "FlexKomSID" INT 0 2147483647;
BA_DEF_ SG_  "FlexKomSigLaenge" INT 0 64;
BA_DEF_ SG_  "FlexKomSigName" STRING ;
BA_DEF_ SG_  "FlexKomSigStartPos" INT 0 63;
BA_DEF_ SG_  "FlexKomSigStartValue" STRING ;
BA_DEF_ SG_  "GenSigCycleTime" INT 0 65535;
BA_DEF_ SG_  "GenSigCycleTimeActive" INT 0 65535;
BA_DEF_ SG_  "GenSigSendType" ENUM  "cyclicX","spontanX","cyclicIfActiveX","spontanWithDelay","cyclicAndSpontanX","cyclicAndSpontanWithDelay","spontanWithRepitition","cyclicIfActiveAndSpontanWD","cyclicIfActiveFast","cyclicWithRepeatOnDemand","none";
BA_DEF_ SG_  "GenSigSNA" STRING ;
BA_DEF_ SG_  "GenSigStartValue" HEX 0 2147483648;
BA_DEF_ SG_  "GenSigTimeout_CBC" INT 0 65535;
BA_DEF_ SG_  "GenSigTimeout_EPS" INT 0 65535;
BA_DEF_ SG_  "GenSigTimeout_ESC" INT 0 65535;
BA_DEF_ SG_  "GenSigTimeout_ESL" INT 0 65535;
BA_DEF_ SG_  "GenSigTimeout_RHSC2" INT 0 65535;
BA_DEF_ SG_  "GenSigTimeout_ETM" INT 0 65535;
BA_DEF_ SG_  "GenSigTimeout_HaLF" INT 0 65535;
BA_DEF_ SG_  "GenSigTimeout_IC" INT 0 65535;
BA_DEF_ SG_  "GenSigTimeout_OCM" INT 0 65535;
BA_DEF_ SG_  "GenSigTimeout_ORC" INT 0 65535;
BA_DEF_ SG_  "GenSigTimeout_PTS" INT 0 65535;
BA_DEF_ SG_  "GenSigTimeout_RF_HUB" INT 0 65535;
BA_DEF_ SG_  "GenSigTimeout_SCCM" INT 0 65535;
BA_DEF_ SG_  "RID" STRING ;
BA_DEF_DEF_  "App-Botschaft" "nein";
BA_DEF_DEF_  "CanMsgMinLen" 0;
BA_DEF_DEF_  "DiagRequest" "nein";
BA_DEF_DEF_  "DiagResponse" "nein";
BA_DEF_DEF_  "DiagState" "nein";
BA_DEF_DEF_  "GenMsgCycleTime" 0;
BA_DEF_DEF_  "GenMsgCycleTimeActive" 0;
BA_DEF_DEF_  "GenMsgDelayTime" 0;
BA_DEF_DEF_  "GenMsgNrOfRepetitions" 0;
BA_DEF_DEF_  "GenMsgSendType" "cyclicX";
BA_DEF_DEF_  "GenMsgStartDelayTime" 0;
BA_DEF_DEF_  "GenMsgStartValue" "";
BA_DEF_DEF_  "NWM-Botschaft" "nein";
BA_DEF_DEF_  "TpTxIndex" 0;
BA_DEF_DEF_  "FlexKomComment" "";
BA_DEF_DEF_  "FlexKomIsMotorola" "nein";
BA_DEF_DEF_  "FlexKomSID" 0;
BA_DEF_DEF_  "FlexKomSigLaenge" 0;
BA_DEF_DEF_  "FlexKomSigName" "";
BA_DEF_DEF_  "FlexKomSigStartPos" 0;
BA_DEF_DEF_  "FlexKomSigStartValue" "";
BA_DEF_DEF_  "GenSigCycleTime" 0;
BA_DEF_DEF_  "GenSigCycleTimeActive" 0;
BA_DEF_DEF_  "GenSigSendType" "cyclicX";
BA_DEF_DEF_  "GenSigSNA" "";
BA_DEF_DEF_  "GenSigStartValue" 0;
BA_DEF_DEF_  "GenSigTimeout_CBC" 0;
BA_DEF_DEF_  "GenSigTimeout_EPS" 0;
BA_DEF_DEF_  "GenSigTimeout_ESC" 0;
BA_DEF_DEF_  "GenSigTimeout_ESL" 0;
BA_DEF_DEF_  "GenSigTimeout_RHSC2" 0;
BA_DEF_DEF_  "GenSigTimeout_ETM" 0;
BA_DEF_DEF_  "GenSigTimeout_HaLF" 0;
BA_DEF_DEF_  "GenSigTimeout_IC" 0;
BA_DEF_DEF_  "GenSigTimeout_OCM" 0;
BA_DEF_DEF_  "GenSigTimeout_ORC" 0;
BA_DEF_DEF_  "GenSigTimeout_PTS" 0;
BA_DEF_DEF_  "GenSigTimeout_RF_HUB" 0;
BA_DEF_DEF_  "GenSigTimeout_SCCM" 0;
BA_DEF_DEF_  "RID" "";
BA_ "GenMsgCycleTime" BO_ 624 1000;
BA_ "GenMsgDelayTime" BO_ 624 20;
BA_ "GenMsgNrOfRepetitions" BO_ 624 2;
BA_ "GenMsgSendType" BO_ 624 5;
BA_ "GenMsgStartDelayTime" BO_ 624 40;
BA_ "GenMsgStartValue" BO_ 624 "0000000000000FFFh";
BA_ "GenMsgCycleTime" BO_ 456 500;
BA_ "GenMsgDelayTime" BO_ 456 20;
BA_ "GenMsgNrOfRepetitions" BO_ 456 2;
BA_ "GenMsgSendType" BO_ 456 5;
BA_ "GenMsgStartDelayTime" BO_ 456 30;
BA_ "GenMsgStartValue" BO_ 456 "00000000h";
BA_ "GenMsgCycleTimeActive" BO_ 788 50;
BA_ "GenMsgDelayTime" BO_ 788 20;
BA_ "GenMsgNrOfRepetitions" BO_ 788 2;
BA_ "GenMsgSendType" BO_ 788 2;
BA_ "GenMsgStartValue" BO_ 788 "000000h";
BA_ "GenMsgCycleTime" BO_ 856 1000;
BA_ "GenMsgDelayTime" BO_ 856 20;
BA_ "GenMsgNrOfRepetitions" BO_ 856 2;
BA_ "GenMsgStartDelayTime" BO_ 856 50;
BA_ "GenMsgStartValue" BO_ 856 "FF000000h";
BA_ "GenMsgCycleTime" BO_ 848 1000;
BA_ "GenMsgDelayTime" BO_ 848 20;
BA_ "GenMsgNrOfRepetitions" BO_ 848 2;
BA_ "GenMsgStartValue" BO_ 848 "FFFFFFFFFFFFFF3Fh";
BA_ "GenMsgCycleTime" BO_ 500 20;
BA_ "GenMsgDelayTime" BO_ 500 20;
BA_ "GenMsgNrOfRepetitions" BO_ 500 2;
BA_ "GenMsgStartValue" BO_ 500 "1FFF0CCB000000FFh";
BA_ "GenMsgCycleTime" BO_ 499 10;
BA_ "GenMsgNrOfRepetitions" BO_ 499 2;
BA_ "GenMsgStartValue" BO_ 499 "1FFF0CCB000000FFh";
BA_ "GenMsgCycleTime" BO_ 501 60;
BA_ "GenMsgDelayTime" BO_ 501 20;
BA_ "GenMsgNrOfRepetitions" BO_ 501 2;
BA_ "GenMsgStartValue" BO_ 501 "00FFFF00000000FFh";
BA_ "GenMsgCycleTime" BO_ 625 20;
BA_ "GenMsgDelayTime" BO_ 625 20;
BA_ "GenMsgNrOfRepetitions" BO_ 625 2;
BA_ "GenMsgStartValue" BO_ 625 "000000FF000000FFh";
BA_ "DiagState" BO_ 2015 1;
BA_ "GenMsgDelayTime" BO_ 2015 20;
BA_ "GenMsgNrOfRepetitions" BO_ 2015 2;
BA_ "GenMsgStartValue" BO_ 2015 "0000000000000000h";
BA_ "DiagState" BO_ 1089 1;
BA_ "GenMsgDelayTime" BO_ 1089 20;
BA_ "GenMsgNrOfRepetitions" BO_ 1089 2;
BA_ "GenMsgStartValue" BO_ 1089 "0000000000000000h";
BA_ "GenMsgCycleTime" BO_ 860 1000;
BA_ "GenMsgDelayTime" BO_ 860 20;
BA_ "GenMsgNrOfRepetitions" BO_ 860 2;
BA_ "GenMsgSendType" BO_ 860 5;
BA_ "GenMsgStartValue" BO_ 860 "000000000FFFh";
BA_ "DiagRequest" BO_ 1900 1;
BA_ "GenMsgDelayTime" BO_ 1900 20;
BA_ "GenMsgNrOfRepetitions" BO_ 1900 2;
BA_ "GenMsgSendType" BO_ 1900 1;
BA_ "GenMsgStartValue" BO_ 1900 "0000000000000000h";
BA_ "DiagRequest" BO_ 1898 1;
BA_ "GenMsgDelayTime" BO_ 1898 20;
BA_ "GenMsgNrOfRepetitions" BO_ 1898 2;
BA_ "GenMsgSendType" BO_ 1898 1;
BA_ "GenMsgStartValue" BO_ 1898 "0000000000000000h";
BA_ "DiagRequest" BO_ 2023 1;
BA_ "GenMsgDelayTime" BO_ 2023 20;
BA_ "GenMsgNrOfRepetitions" BO_ 2023 2;
BA_ "GenMsgSendType" BO_ 2023 1;
BA_ "GenMsgStartValue" BO_ 2023 "0000000000000000h";
BA_ "DiagRequest" BO_ 2020 1;
BA_ "GenMsgDelayTime" BO_ 2020 20;
BA_ "GenMsgNrOfRepetitions" BO_ 2020 2;
BA_ "GenMsgSendType" BO_ 2020 1;
BA_ "GenMsgStartValue" BO_ 2020 "0000000000000000h";
BA_ "DiagRequest" BO_ 1568 1;
BA_ "GenMsgDelayTime" BO_ 1568 20;
BA_ "GenMsgNrOfRepetitions" BO_ 1568 2;
BA_ "GenMsgSendType" BO_ 1568 1;
BA_ "GenMsgStartValue" BO_ 1568 "0000000000000000h";
BA_ "DiagRequest" BO_ 1875 1;
BA_ "GenMsgDelayTime" BO_ 1875 20;
BA_ "GenMsgNrOfRepetitions" BO_ 1875 2;
BA_ "GenMsgSendType" BO_ 1875 1;
BA_ "GenMsgStartValue" BO_ 1875 "0000000000000000h";
BA_ "DiagRequest" BO_ 1899 1;
BA_ "GenMsgDelayTime" BO_ 1899 20;
BA_ "GenMsgNrOfRepetitions" BO_ 1899 2;
BA_ "GenMsgSendType" BO_ 1899 1;
BA_ "GenMsgStartValue" BO_ 1899 "0000000000000000h";
BA_ "DiagRequest" BO_ 2019 1;
BA_ "GenMsgDelayTime" BO_ 2019 20;
BA_ "GenMsgNrOfRepetitions" BO_ 2019 2;
BA_ "GenMsgSendType" BO_ 2019 1;
BA_ "GenMsgStartValue" BO_ 2019 "0000000000000000h";
BA_ "DiagRequest" BO_ 2016 1;
BA_ "GenMsgDelayTime" BO_ 2016 20;
BA_ "GenMsgNrOfRepetitions" BO_ 2016 2;
BA_ "GenMsgSendType" BO_ 2016 1;
BA_ "GenMsgStartValue" BO_ 2016 "0000000000000000h";
BA_ "DiagRequest" BO_ 1882 1;
BA_ "GenMsgDelayTime" BO_ 1882 20;
BA_ "GenMsgNrOfRepetitions" BO_ 1882 2;
BA_ "GenMsgSendType" BO_ 1882 1;
BA_ "GenMsgStartValue" BO_ 1882 "0000000000000000h";
BA_ "DiagRequest" BO_ 1864 1;
BA_ "GenMsgDelayTime" BO_ 1864 20;
BA_ "GenMsgNrOfRepetitions" BO_ 1864 2;
BA_ "GenMsgSendType" BO_ 1864 1;
BA_ "GenMsgStartValue" BO_ 1864 "0000000000000000h";
BA_ "DiagRequest" BO_ 1865 1;
BA_ "GenMsgDelayTime" BO_ 1865 20;
BA_ "GenMsgNrOfRepetitions" BO_ 1865 2;
BA_ "GenMsgSendType" BO_ 1865 1;
BA_ "GenMsgStartValue" BO_ 1865 "0000000000000000h";
BA_ "DiagRequest" BO_ 2018 1;
BA_ "GenMsgDelayTime" BO_ 2018 20;
BA_ "GenMsgNrOfRepetitions" BO_ 2018 2;
BA_ "GenMsgSendType" BO_ 2018 1;
BA_ "GenMsgStartValue" BO_ 2018 "0000000000000000h";
BA_ "DiagRequest" BO_ 1892 1;
BA_ "GenMsgDelayTime" BO_ 1892 20;
BA_ "GenMsgNrOfRepetitions" BO_ 1892 2;
BA_ "GenMsgSendType" BO_ 1892 1;
BA_ "GenMsgStartValue" BO_ 1892 "0000000000000000h";
BA_ "DiagRequest" BO_ 1858 1;
BA_ "GenMsgDelayTime" BO_ 1858 20;
BA_ "GenMsgNrOfRepetitions" BO_ 1858 2;
BA_ "GenMsgSendType" BO_ 1858 1;
BA_ "GenMsgStartValue" BO_ 1858 "0000000000000000h";
BA_ "DiagRequest" BO_ 1902 1;
BA_ "GenMsgDelayTime" BO_ 1902 20;
BA_ "GenMsgNrOfRepetitions" BO_ 1902 2;
BA_ "GenMsgSendType" BO_ 1902 1;
BA_ "GenMsgStartValue" BO_ 1902 "0000000000000000h";
BA_ "DiagRequest" BO_ 1886 1;
BA_ "GenMsgDelayTime" BO_ 1886 20;
BA_ "GenMsgNrOfRepetitions" BO_ 1886 2;
BA_ "GenMsgSendType" BO_ 1886 1;
BA_ "GenMsgStartValue" BO_ 1886 "0000000000000000h";
BA_ "DiagRequest" BO_ 1860 1;
BA_ "GenMsgDelayTime" BO_ 1860 20;
BA_ "GenMsgNrOfRepetitions" BO_ 1860 2;
BA_ "GenMsgSendType" BO_ 1860 1;
BA_ "GenMsgStartValue" BO_ 1860 "0000000000000000h";
BA_ "DiagRequest" BO_ 1890 1;
BA_ "GenMsgDelayTime" BO_ 1890 20;
BA_ "GenMsgNrOfRepetitions" BO_ 1890 2;
BA_ "GenMsgSendType" BO_ 1890 1;
BA_ "GenMsgStartValue" BO_ 1890 "0000000000000000h";
BA_ "DiagRequest" BO_ 1856 1;
BA_ "GenMsgDelayTime" BO_ 1856 20;
BA_ "GenMsgNrOfRepetitions" BO_ 1856 2;
BA_ "GenMsgSendType" BO_ 1856 1;
BA_ "GenMsgStartValue" BO_ 1856 "0000000000000000h";
BA_ "DiagRequest" BO_ 1891 1;
BA_ "GenMsgDelayTime" BO_ 1891 20;
BA_ "GenMsgNrOfRepetitions" BO_ 1891 2;
BA_ "GenMsgSendType" BO_ 1891 1;
BA_ "GenMsgStartValue" BO_ 1891 "0000000000000000h";
BA_ "DiagRequest" BO_ 1150 1;
BA_ "GenMsgDelayTime" BO_ 1150 20;
BA_ "GenMsgNrOfRepetitions" BO_ 1150 2;
BA_ "GenMsgSendType" BO_ 1150 1;
BA_ "GenMsgStartValue" BO_ 1150 "0000000000000000h";
BA_ "DiagResponse" BO_ 1260 1;
BA_ "GenMsgDelayTime" BO_ 1260 20;
BA_ "GenMsgNrOfRepetitions" BO_ 1260 2;
BA_ "GenMsgSendType" BO_ 1260 1;
BA_ "GenMsgStartValue" BO_ 1260 "0000000000000000h";
BA_ "DiagResponse" BO_ 1258 1;
BA_ "GenMsgDelayTime" BO_ 1258 20;
BA_ "GenMsgNrOfRepetitions" BO_ 1258 2;
BA_ "GenMsgSendType" BO_ 1258 1;
BA_ "GenMsgStartValue" BO_ 1258 "0000000000000000h";
BA_ "DiagResponse" BO_ 2031 1;
BA_ "GenMsgDelayTime" BO_ 2031 20;
BA_ "GenMsgNrOfRepetitions" BO_ 2031 2;
BA_ "GenMsgSendType" BO_ 2031 1;
BA_ "GenMsgStartValue" BO_ 2031 "0000000000000000h";
BA_ "DiagResponse" BO_ 2028 1;
BA_ "GenMsgDelayTime" BO_ 2028 20;
BA_ "GenMsgNrOfRepetitions" BO_ 2028 2;
BA_ "GenMsgSendType" BO_ 2028 1;
BA_ "GenMsgStartValue" BO_ 2028 "0000000000000000h";
BA_ "DiagResponse" BO_ 1284 1;
BA_ "GenMsgDelayTime" BO_ 1284 20;
BA_ "GenMsgNrOfRepetitions" BO_ 1284 2;
BA_ "GenMsgSendType" BO_ 1284 1;
BA_ "GenMsgStartValue" BO_ 1284 "0000000000000000h";
BA_ "DiagResponse" BO_ 1235 1;
BA_ "GenMsgDelayTime" BO_ 1235 20;
BA_ "GenMsgNrOfRepetitions" BO_ 1235 2;
BA_ "GenMsgSendType" BO_ 1235 1;
BA_ "GenMsgStartValue" BO_ 1235 "0000000000000000h";
BA_ "DiagResponse" BO_ 1259 1;
BA_ "GenMsgDelayTime" BO_ 1259 20;
BA_ "GenMsgNrOfRepetitions" BO_ 1259 2;
BA_ "GenMsgSendType" BO_ 1259 1;
BA_ "GenMsgStartValue" BO_ 1259 "0000000000000000h";
BA_ "DiagResponse" BO_ 2027 1;
BA_ "GenMsgDelayTime" BO_ 2027 20;
BA_ "GenMsgNrOfRepetitions" BO_ 2027 2;
BA_ "GenMsgSendType" BO_ 2027 1;
BA_ "GenMsgStartValue" BO_ 2027 "0000000000000000h";
BA_ "DiagResponse" BO_ 2024 1;
BA_ "GenMsgDelayTime" BO_ 2024 20;
BA_ "GenMsgNrOfRepetitions" BO_ 2024 2;
BA_ "GenMsgSendType" BO_ 2024 1;
BA_ "GenMsgStartValue" BO_ 2024 "0000000000000000h";
BA_ "DiagResponse" BO_ 1242 1;
BA_ "GenMsgDelayTime" BO_ 1242 20;
BA_ "GenMsgNrOfRepetitions" BO_ 1242 2;
BA_ "GenMsgSendType" BO_ 1242 1;
BA_ "GenMsgStartValue" BO_ 1242 "0000000000000000h";
BA_ "DiagResponse" BO_ 1224 1;
BA_ "GenMsgDelayTime" BO_ 1224 20;
BA_ "GenMsgNrOfRepetitions" BO_ 1224 2;
BA_ "GenMsgSendType" BO_ 1224 1;
BA_ "GenMsgStartValue" BO_ 1224 "0000000000000000h";
BA_ "DiagResponse" BO_ 1225 1;
BA_ "GenMsgDelayTime" BO_ 1225 20;
BA_ "GenMsgNrOfRepetitions" BO_ 1225 2;
BA_ "GenMsgSendType" BO_ 1225 1;
BA_ "GenMsgStartValue" BO_ 1225 "0000000000000000h";
BA_ "DiagResponse" BO_ 2026 1;
BA_ "GenMsgDelayTime" BO_ 2026 20;
BA_ "GenMsgNrOfRepetitions" BO_ 2026 2;
BA_ "GenMsgSendType" BO_ 2026 1;
BA_ "GenMsgStartValue" BO_ 2026 "0000000000000000h";
BA_ "DiagResponse" BO_ 1252 1;
BA_ "GenMsgDelayTime" BO_ 1252 20;
BA_ "GenMsgNrOfRepetitions" BO_ 1252 2;
BA_ "GenMsgSendType" BO_ 1252 1;
BA_ "GenMsgStartValue" BO_ 1252 "0000000000000000h";
BA_ "DiagResponse" BO_ 1218 1;
BA_ "GenMsgDelayTime" BO_ 1218 20;
BA_ "GenMsgNrOfRepetitions" BO_ 1218 2;
BA_ "GenMsgSendType" BO_ 1218 1;
BA_ "GenMsgStartValue" BO_ 1218 "0000000000000000h";
BA_ "DiagResponse" BO_ 1262 1;
BA_ "GenMsgDelayTime" BO_ 1262 20;
BA_ "GenMsgNrOfRepetitions" BO_ 1262 2;
BA_ "GenMsgSendType" BO_ 1262 1;
BA_ "GenMsgStartValue" BO_ 1262 "0000000000000000h";
BA_ "DiagResponse" BO_ 1246 1;
BA_ "GenMsgDelayTime" BO_ 1246 20;
BA_ "GenMsgNrOfRepetitions" BO_ 1246 2;
BA_ "GenMsgSendType" BO_ 1246 1;
BA_ "GenMsgStartValue" BO_ 1246 "0000000000000000h";
BA_ "DiagResponse" BO_ 1220 1;
BA_ "GenMsgDelayTime" BO_ 1220 20;
BA_ "GenMsgNrOfRepetitions" BO_ 1220 2;
BA_ "GenMsgSendType" BO_ 1220 1;
BA_ "GenMsgStartValue" BO_ 1220 "0000000000000000h";
BA_ "DiagResponse" BO_ 1250 1;
BA_ "GenMsgDelayTime" BO_ 1250 20;
BA_ "GenMsgNrOfRepetitions" BO_ 1250 2;
BA_ "GenMsgSendType" BO_ 1250 1;
BA_ "GenMsgStartValue" BO_ 1250 "0000000000000000h";
BA_ "DiagResponse" BO_ 1216 1;
BA_ "GenMsgDelayTime" BO_ 1216 20;
BA_ "GenMsgNrOfRepetitions" BO_ 1216 2;
BA_ "GenMsgSendType" BO_ 1216 1;
BA_ "GenMsgStartValue" BO_ 1216 "0000000000000000h";
BA_ "DiagResponse" BO_ 1251 1;
BA_ "GenMsgDelayTime" BO_ 1251 20;
BA_ "GenMsgNrOfRepetitions" BO_ 1251 2;
BA_ "GenMsgSendType" BO_ 1251 1;
BA_ "GenMsgStartValue" BO_ 1251 "0000000000000000h";
BA_ "DiagResponse" BO_ 1151 1;
BA_ "GenMsgDelayTime" BO_ 1151 20;
BA_ "GenMsgNrOfRepetitions" BO_ 1151 2;
BA_ "GenMsgSendType" BO_ 1151 1;
BA_ "GenMsgStartValue" BO_ 1151 "0000000000000000h";
BA_ "GenMsgCycleTime" BO_ 653 20;
BA_ "GenMsgDelayTime" BO_ 653 20;
BA_ "GenMsgNrOfRepetitions" BO_ 653 2;
BA_ "GenMsgStartValue" BO_ 653 "0000F003FFFE00FFh";
BA_ "GenMsgCycleTime" BO_ 264 10;
BA_ "GenMsgDelayTime" BO_ 264 20;
BA_ "GenMsgNrOfRepetitions" BO_ 264 2;
BA_ "GenMsgStartValue" BO_ 264 "FFFF1FFF1FFF00FFh";
BA_ "GenMsgCycleTime" BO_ 288 20;
BA_ "GenMsgDelayTime" BO_ 288 20;
BA_ "GenMsgNrOfRepetitions" BO_ 288 2;
BA_ "GenMsgStartValue" BO_ 288 "1FFFFF1FFF00FFh";
BA_ "GenMsgCycleTime" BO_ 760 10;
BA_ "GenMsgDelayTime" BO_ 760 20;
BA_ "GenMsgNrOfRepetitions" BO_ 760 2;
BA_ "GenMsgStartValue" BO_ 760 "5FFF1FFF00FF0FFFh";
BA_ "GenMsgCycleTime" BO_ 559 20;
BA_ "GenMsgDelayTime" BO_ 559 20;
BA_ "GenMsgNrOfRepetitions" BO_ 559 2;
BA_ "GenMsgStartValue" BO_ 559 "FFFFFFFF00000CFFh";
BA_ "GenMsgDelayTime" BO_ 864 20;
BA_ "GenMsgNrOfRepetitions" BO_ 864 2;
BA_ "GenMsgSendType" BO_ 864 1;
BA_ "GenMsgStartValue" BO_ 864 "0000000000000000h";
BA_ "GenMsgDelayTime" BO_ 850 20;
BA_ "GenMsgNrOfRepetitions" BO_ 850 2;
BA_ "GenMsgSendType" BO_ 850 1;
BA_ "GenMsgStartValue" BO_ 850 "0000000000000000h";
BA_ "GenMsgDelayTime" BO_ 880 20;
BA_ "GenMsgNrOfRepetitions" BO_ 880 2;
BA_ "GenMsgSendType" BO_ 880 1;
BA_ "GenMsgStartValue" BO_ 880 "0000000000000000h";
BA_ "GenMsgDelayTime" BO_ 896 20;
BA_ "GenMsgNrOfRepetitions" BO_ 896 2;
BA_ "GenMsgSendType" BO_ 896 1;
BA_ "GenMsgStartValue" BO_ 896 "0000000000000000h";
BA_ "GenMsgDelayTime" BO_ 912 20;
BA_ "GenMsgNrOfRepetitions" BO_ 912 2;
BA_ "GenMsgSendType" BO_ 912 1;
BA_ "GenMsgStartValue" BO_ 912 "0000000000000000h";
BA_ "GenMsgDelayTime" BO_ 928 20;
BA_ "GenMsgNrOfRepetitions" BO_ 928 2;
BA_ "GenMsgSendType" BO_ 928 1;
BA_ "GenMsgStartValue" BO_ 928 "0000000000000000h";
BA_ "GenMsgDelayTime" BO_ 936 20;
BA_ "GenMsgNrOfRepetitions" BO_ 936 2;
BA_ "GenMsgSendType" BO_ 936 1;
BA_ "GenMsgStartValue" BO_ 936 "0000000000000000h";
BA_ "GenMsgCycleTime" BO_ 632 100;
BA_ "GenMsgDelayTime" BO_ 632 20;
BA_ "GenMsgNrOfRepetitions" BO_ 632 2;
BA_ "GenMsgStartValue" BO_ 632 "FF00FFFF00FF0000h";
BA_ "GenMsgCycleTime" BO_ 384 100;
BA_ "GenMsgDelayTime" BO_ 384 20;
BA_ "GenMsgNrOfRepetitions" BO_ 384 2;
BA_ "GenMsgStartValue" BO_ 384 "00FFFF000001FFFFh";
BA_ "GenMsgCycleTime" BO_ 779 1000;
BA_ "GenMsgDelayTime" BO_ 779 20;
BA_ "GenMsgNrOfRepetitions" BO_ 779 2;
BA_ "GenMsgStartValue" BO_ 779 "FFFFFF0FFF00FF00h";
BA_ "GenMsgCycleTime" BO_ 703 100;
BA_ "GenMsgDelayTime" BO_ 703 20;
BA_ "GenMsgNrOfRepetitions" BO_ 703 2;
BA_ "GenMsgStartValue" BO_ 703 "7F00000000000000h";
BA_ "GenMsgCycleTime" BO_ 863 100;
BA_ "GenMsgDelayTime" BO_ 863 20;
BA_ "GenMsgNrOfRepetitions" BO_ 863 2;
BA_ "GenMsgStartValue" BO_ 863 "000000000000FFFFh";
BA_ "GenMsgCycleTime" BO_ 800 100;
BA_ "GenMsgDelayTime" BO_ 800 20;
BA_ "GenMsgNrOfRepetitions" BO_ 800 2;
BA_ "GenMsgStartValue" BO_ 800 "00000000F0000000h";
BA_ "GenMsgCycleTime" BO_ 308 20;
BA_ "GenMsgDelayTime" BO_ 308 20;
BA_ "GenMsgNrOfRepetitions" BO_ 308 2;
BA_ "GenMsgStartValue" BO_ 308 "08FFFF00FFFF00FFh";
BA_ "GenMsgCycleTime" BO_ 280 10;
BA_ "GenMsgDelayTime" BO_ 280 20;
BA_ "GenMsgNrOfRepetitions" BO_ 280 2;
BA_ "GenMsgStartValue" BO_ 280 "9FFF1FFF1FFF00FFh";
BA_ "GenMsgCycleTime" BO_ 290 20;
BA_ "GenMsgDelayTime" BO_ 290 20;
BA_ "GenMsgNrOfRepetitions" BO_ 290 2;
BA_ "GenMsgStartValue" BO_ 290 "00FF000FFFFFh";
BA_ "GenMsgCycleTime" BO_ 672 100;
BA_ "GenMsgDelayTime" BO_ 672 20;
BA_ "GenMsgNrOfRepetitions" BO_ 672 2;
BA_ "GenMsgStartValue" BO_ 672 "6000FFFFFFFFFF07h";
BA_ "GenMsgCycleTime" BO_ 257 100;
BA_ "GenMsgDelayTime" BO_ 257 20;
BA_ "GenMsgNrOfRepetitions" BO_ 257 2;
BA_ "GenMsgStartValue" BO_ 257 "0000000000h";
BA_ "FlexKomComment" SG_ 624 ESLLockFailSts_BCM "Display info on failed lock; Failed = [1]";
BA_ "FlexKomIsMotorola" SG_ 624 ESLLockFailSts_BCM 1;
BA_ "FlexKomSID" SG_ 624 ESLLockFailSts_BCM 2369;
BA_ "FlexKomSigLaenge" SG_ 624 ESLLockFailSts_BCM 1;
BA_ "FlexKomSigName" SG_ 624 ESLLockFailSts_BCM "ESLLockFailSts_BCM";
BA_ "FlexKomSigStartPos" SG_ 624 ESLLockFailSts_BCM 40;
BA_ "FlexKomSigStartValue" SG_ 624 ESLLockFailSts_BCM "00h";
BA_ "GenSigCycleTime" SG_ 624 ESLLockFailSts_BCM 1000;
BA_ "GenSigSendType" SG_ 624 ESLLockFailSts_BCM 5;
BA_ "GenSigSNA" SG_ 624 ESLLockFailSts_BCM "0h";
BA_ "GenSigTimeout_IC" SG_ 624 ESLLockFailSts_BCM 10500;
BA_ "FlexKomComment" SG_ 624 ESLUnlockFailSts_BCM "Display info on failed unlock; Failed = [1]";
BA_ "FlexKomIsMotorola" SG_ 624 ESLUnlockFailSts_BCM 1;
BA_ "FlexKomSID" SG_ 624 ESLUnlockFailSts_BCM 2370;
BA_ "FlexKomSigLaenge" SG_ 624 ESLUnlockFailSts_BCM 1;
BA_ "FlexKomSigName" SG_ 624 ESLUnlockFailSts_BCM "ESLUnlockFailSts_BCM";
BA_ "FlexKomSigStartPos" SG_ 624 ESLUnlockFailSts_BCM 41;
BA_ "FlexKomSigStartValue" SG_ 624 ESLUnlockFailSts_BCM "00h";
BA_ "GenSigCycleTime" SG_ 624 ESLUnlockFailSts_BCM 1000;
BA_ "GenSigSendType" SG_ 624 ESLUnlockFailSts_BCM 5;
BA_ "GenSigSNA" SG_ 624 ESLUnlockFailSts_BCM "0h";
BA_ "GenSigTimeout_IC" SG_ 624 ESLUnlockFailSts_BCM 10500;
BA_ "FlexKomComment" SG_ 624 EngineOffTimer "Engine off timer - engine off ignition NOT lock.";
BA_ "FlexKomIsMotorola" SG_ 624 EngineOffTimer 1;
BA_ "FlexKomSID" SG_ 624 EngineOffTimer 1906;
BA_ "FlexKomSigLaenge" SG_ 624 EngineOffTimer 16;
BA_ "FlexKomSigName" SG_ 624 EngineOffTimer "EngineOffTimer";
BA_ "FlexKomSigStartPos" SG_ 624 EngineOffTimer 55;
BA_ "FlexKomSigStartValue" SG_ 624 EngineOffTimer "0FFFh";
BA_ "GenSigCycleTime" SG_ 624 EngineOffTimer 1000;
BA_ "GenSigSNA" SG_ 624 EngineOffTimer "FFFh";
BA_ "GenSigStartValue" SG_ 624 EngineOffTimer 4095;
BA_ "FlexKomComment" SG_ 624 Gate_Req_PE "Gate passive entry requested; True = [1]";
BA_ "FlexKomIsMotorola" SG_ 624 Gate_Req_PE 1;
BA_ "FlexKomSID" SG_ 624 Gate_Req_PE 2417;
BA_ "FlexKomSigLaenge" SG_ 624 Gate_Req_PE 2;
BA_ "FlexKomSigName" SG_ 624 Gate_Req_PE "Gate_Req_PE";
BA_ "FlexKomSigStartPos" SG_ 624 Gate_Req_PE 23;
BA_ "FlexKomSigStartValue" SG_ 624 Gate_Req_PE "00h";
BA_ "GenSigCycleTime" SG_ 624 Gate_Req_PE 1000;
BA_ "GenSigSendType" SG_ 624 Gate_Req_PE 5;
BA_ "GenSigSNA" SG_ 624 Gate_Req_PE "0h";
BA_ "RID" SG_ 624 Gate_Req_PE "2906";
BA_ "FlexKomComment" SG_ 624 L_R_Req_PE "Left rear passive entry requested; True = [1]";
BA_ "FlexKomIsMotorola" SG_ 624 L_R_Req_PE 1;
BA_ "FlexKomSID" SG_ 624 L_R_Req_PE 2415;
BA_ "FlexKomSigLaenge" SG_ 624 L_R_Req_PE 2;
BA_ "FlexKomSigName" SG_ 624 L_R_Req_PE "L_R_Req_PE";
BA_ "FlexKomSigStartPos" SG_ 624 L_R_Req_PE 19;
BA_ "FlexKomSigStartValue" SG_ 624 L_R_Req_PE "00h";
BA_ "GenSigCycleTime" SG_ 624 L_R_Req_PE 1000;
BA_ "GenSigSendType" SG_ 624 L_R_Req_PE 5;
BA_ "GenSigSNA" SG_ 624 L_R_Req_PE "0h";
BA_ "RID" SG_ 624 L_R_Req_PE "2905";
BA_ "FlexKomComment" SG_ 624 MoveWheelSts "Display message to move steering wheel; Active = [";
BA_ "FlexKomIsMotorola" SG_ 624 MoveWheelSts 1;
BA_ "FlexKomSID" SG_ 624 MoveWheelSts 2371;
BA_ "FlexKomSigLaenge" SG_ 624 MoveWheelSts 1;
BA_ "FlexKomSigName" SG_ 624 MoveWheelSts "MoveWheelSts";
BA_ "FlexKomSigStartPos" SG_ 624 MoveWheelSts 52;
BA_ "FlexKomSigStartValue" SG_ 624 MoveWheelSts "00h";
BA_ "GenSigCycleTime" SG_ 624 MoveWheelSts 1000;
BA_ "GenSigSendType" SG_ 624 MoveWheelSts 5;
BA_ "GenSigSNA" SG_ 624 MoveWheelSts "0h";
BA_ "GenSigTimeout_IC" SG_ 624 MoveWheelSts 10500;
BA_ "FlexKomComment" SG_ 624 PNC_ALM_ACT "Panic alarm active; [1] = True";
BA_ "FlexKomIsMotorola" SG_ 624 PNC_ALM_ACT 1;
BA_ "FlexKomSID" SG_ 624 PNC_ALM_ACT 756;
BA_ "FlexKomSigLaenge" SG_ 624 PNC_ALM_ACT 1;
BA_ "FlexKomSigName" SG_ 624 PNC_ALM_ACT "PNC_ALM_ACT";
BA_ "FlexKomSigStartPos" SG_ 624 PNC_ALM_ACT 55;
BA_ "FlexKomSigStartValue" SG_ 624 PNC_ALM_ACT "00h";
BA_ "GenSigCycleTime" SG_ 624 PNC_ALM_ACT 1000;
BA_ "GenSigSendType" SG_ 624 PNC_ALM_ACT 5;
BA_ "GenSigSNA" SG_ 624 PNC_ALM_ACT "0h";
BA_ "FlexKomComment" SG_ 624 R_R_Req_PE "Right rear passive entry requested; True = [1]";
BA_ "FlexKomIsMotorola" SG_ 624 R_R_Req_PE 1;
BA_ "FlexKomSID" SG_ 624 R_R_Req_PE 2416;
BA_ "FlexKomSigLaenge" SG_ 624 R_R_Req_PE 2;
BA_ "FlexKomSigName" SG_ 624 R_R_Req_PE "R_R_Req_PE";
BA_ "FlexKomSigStartPos" SG_ 624 R_R_Req_PE 21;
BA_ "FlexKomSigStartValue" SG_ 624 R_R_Req_PE "00h";
BA_ "GenSigCycleTime" SG_ 624 R_R_Req_PE 1000;
BA_ "GenSigSendType" SG_ 624 R_R_Req_PE 5;
BA_ "GenSigSNA" SG_ 624 R_R_Req_PE "0h";
BA_ "RID" SG_ 624 R_R_Req_PE "2907";
BA_ "FlexKomComment" SG_ 456 VTA_STAT "Vehicle theft alarm packet";
BA_ "FlexKomIsMotorola" SG_ 456 VTA_STAT 1;
BA_ "FlexKomSID" SG_ 456 VTA_STAT 1207;
BA_ "FlexKomSigLaenge" SG_ 456 VTA_STAT 32;
BA_ "FlexKomSigName" SG_ 456 VTA_STAT "VTA_PKT";
BA_ "FlexKomSigStartPos" SG_ 456 VTA_STAT 7;
BA_ "FlexKomSigStartValue" SG_ 456 VTA_STAT "00000000h";
BA_ "GenSigCycleTime" SG_ 456 VTA_STAT 500;
BA_ "GenSigSendType" SG_ 456 VTA_STAT 5;
BA_ "GenSigSNA" SG_ 456 VTA_STAT "7h";
BA_ "FlexKomComment" SG_ 788 CFG_FEATURE "Configurable display request - from CAN C";
BA_ "FlexKomIsMotorola" SG_ 788 CFG_FEATURE 1;
BA_ "FlexKomSID" SG_ 788 CFG_FEATURE 1679;
BA_ "FlexKomSigLaenge" SG_ 788 CFG_FEATURE 24;
BA_ "FlexKomSigName" SG_ 788 CFG_FEATURE "CFG_RQ_C";
BA_ "FlexKomSigStartPos" SG_ 788 CFG_FEATURE 7;
BA_ "FlexKomSigStartValue" SG_ 788 CFG_FEATURE "000000h";
BA_ "GenSigCycleTimeActive" SG_ 788 CFG_FEATURE 50;
BA_ "GenSigSendType" SG_ 788 CFG_FEATURE 2;
BA_ "GenSigSNA" SG_ 788 CFG_FEATURE "0h";
BA_ "RID" SG_ 788 CFG_FEATURE "1144";
BA_ "FlexKomComment" SG_ 788 CFG_SET "Configurable display request";
BA_ "FlexKomIsMotorola" SG_ 788 CFG_SET 1;
BA_ "FlexKomSID" SG_ 788 CFG_SET 442;
BA_ "FlexKomSigLaenge" SG_ 788 CFG_SET 24;
BA_ "FlexKomSigName" SG_ 788 CFG_SET "CFG_RQ";
BA_ "FlexKomSigStartPos" SG_ 788 CFG_SET 7;
BA_ "FlexKomSigStartValue" SG_ 788 CFG_SET "000000h";
BA_ "GenSigCycleTimeActive" SG_ 788 CFG_SET 50;
BA_ "GenSigSendType" SG_ 788 CFG_SET 2;
BA_ "GenSigSNA" SG_ 788 CFG_SET "0h";
BA_ "RID" SG_ 788 CFG_SET "1173";
BA_ "FlexKomComment" SG_ 788 CFG_STAT_RQ "Configurable display request";
BA_ "FlexKomIsMotorola" SG_ 788 CFG_STAT_RQ 1;
BA_ "FlexKomSID" SG_ 788 CFG_STAT_RQ 442;
BA_ "FlexKomSigLaenge" SG_ 788 CFG_STAT_RQ 24;
BA_ "FlexKomSigName" SG_ 788 CFG_STAT_RQ "CFG_RQ";
BA_ "FlexKomSigStartPos" SG_ 788 CFG_STAT_RQ 7;
BA_ "FlexKomSigStartValue" SG_ 788 CFG_STAT_RQ "000000h";
BA_ "GenSigCycleTimeActive" SG_ 788 CFG_STAT_RQ 50;
BA_ "GenSigSendType" SG_ 788 CFG_STAT_RQ 2;
BA_ "GenSigSNA" SG_ 788 CFG_STAT_RQ "0h";
BA_ "RID" SG_ 788 CFG_STAT_RQ "1228";
BA_ "FlexKomComment" SG_ 856 CMP_DIR "Compass direction (WK/LX)";
BA_ "FlexKomIsMotorola" SG_ 856 CMP_DIR 1;
BA_ "FlexKomSID" SG_ 856 CMP_DIR 817;
BA_ "FlexKomSigLaenge" SG_ 856 CMP_DIR 4;
BA_ "FlexKomSigName" SG_ 856 CMP_DIR "CMP_DIR";
BA_ "FlexKomSigStartPos" SG_ 856 CMP_DIR 3;
BA_ "FlexKomSigStartValue" SG_ 856 CMP_DIR "0Fh";
BA_ "GenSigCycleTime" SG_ 856 CMP_DIR 1000;
BA_ "GenSigSNA" SG_ 856 CMP_DIR "Fh";
BA_ "GenSigStartValue" SG_ 856 CMP_DIR 15;
BA_ "GenSigTimeout_IC" SG_ 856 CMP_DIR 10500;
BA_ "RID" SG_ 856 CMP_DIR "289";
BA_ "FlexKomComment" SG_ 848 DateTmDay "DATE";
BA_ "FlexKomIsMotorola" SG_ 848 DateTmDay 1;
BA_ "FlexKomSID" SG_ 848 DateTmDay 645;
BA_ "FlexKomSigLaenge" SG_ 848 DateTmDay 32;
BA_ "FlexKomSigName" SG_ 848 DateTmDay "DATE";
BA_ "FlexKomSigStartPos" SG_ 848 DateTmDay 31;
BA_ "FlexKomSigStartValue" SG_ 848 DateTmDay "FFFFFFFFh";
BA_ "GenSigCycleTime" SG_ 848 DateTmDay 1000;
BA_ "GenSigSNA" SG_ 848 DateTmDay "FFh";
BA_ "GenSigStartValue" SG_ 848 DateTmDay 255;
BA_ "GenSigTimeout_IC" SG_ 848 DateTmDay 10500;
BA_ "GenSigTimeout_RF_HUB" SG_ 848 DateTmDay 10500;
BA_ "RID" SG_ 848 DateTmDay "1029";
BA_ "FlexKomComment" SG_ 848 DateTmFormat "Date and Time Format";
BA_ "FlexKomIsMotorola" SG_ 848 DateTmFormat 1;
BA_ "FlexKomSID" SG_ 848 DateTmFormat 971;
BA_ "FlexKomSigLaenge" SG_ 848 DateTmFormat 3;
BA_ "FlexKomSigName" SG_ 848 DateTmFormat "DateTmFormat";
BA_ "FlexKomSigStartPos" SG_ 848 DateTmFormat 58;
BA_ "FlexKomSigStartValue" SG_ 848 DateTmFormat "07h";
BA_ "GenSigCycleTime" SG_ 848 DateTmFormat 1000;
BA_ "GenSigSNA" SG_ 848 DateTmFormat "7h";
BA_ "GenSigStartValue" SG_ 848 DateTmFormat 7;
BA_ "GenSigTimeout_IC" SG_ 848 DateTmFormat 10500;
BA_ "RID" SG_ 848 DateTmFormat "1111";
BA_ "FlexKomComment" SG_ 848 DateTmHour "Time of day clock";
BA_ "FlexKomIsMotorola" SG_ 848 DateTmHour 1;
BA_ "FlexKomSID" SG_ 848 DateTmHour 398;
BA_ "FlexKomSigLaenge" SG_ 848 DateTmHour 24;
BA_ "FlexKomSigName" SG_ 848 DateTmHour "Clock";
BA_ "FlexKomSigStartPos" SG_ 848 DateTmHour 7;
BA_ "FlexKomSigStartValue" SG_ 848 DateTmHour "FFFFFFh";
BA_ "GenSigCycleTime" SG_ 848 DateTmHour 1000;
BA_ "GenSigSNA" SG_ 848 DateTmHour "FFh";
BA_ "GenSigStartValue" SG_ 848 DateTmHour 255;
BA_ "GenSigTimeout_IC" SG_ 848 DateTmHour 10500;
BA_ "GenSigTimeout_RF_HUB" SG_ 848 DateTmHour 10500;
BA_ "RID" SG_ 848 DateTmHour "1116";
BA_ "FlexKomComment" SG_ 848 DateTmMinute "Time of day clock";
BA_ "FlexKomIsMotorola" SG_ 848 DateTmMinute 1;
BA_ "FlexKomSID" SG_ 848 DateTmMinute 398;
BA_ "FlexKomSigLaenge" SG_ 848 DateTmMinute 24;
BA_ "FlexKomSigName" SG_ 848 DateTmMinute "Clock";
BA_ "FlexKomSigStartPos" SG_ 848 DateTmMinute 7;
BA_ "FlexKomSigStartValue" SG_ 848 DateTmMinute "FFFFFFh";
BA_ "GenSigCycleTime" SG_ 848 DateTmMinute 1000;
BA_ "GenSigSNA" SG_ 848 DateTmMinute "FFh";
BA_ "GenSigStartValue" SG_ 848 DateTmMinute 255;
BA_ "GenSigTimeout_IC" SG_ 848 DateTmMinute 10500;
BA_ "GenSigTimeout_RF_HUB" SG_ 848 DateTmMinute 10500;
BA_ "RID" SG_ 848 DateTmMinute "1174";
BA_ "FlexKomComment" SG_ 848 DateTmMonth "DATE";
BA_ "FlexKomIsMotorola" SG_ 848 DateTmMonth 1;
BA_ "FlexKomSID" SG_ 848 DateTmMonth 645;
BA_ "FlexKomSigLaenge" SG_ 848 DateTmMonth 32;
BA_ "FlexKomSigName" SG_ 848 DateTmMonth "DATE";
BA_ "FlexKomSigStartPos" SG_ 848 DateTmMonth 31;
BA_ "FlexKomSigStartValue" SG_ 848 DateTmMonth "FFFFFFFFh";
BA_ "GenSigCycleTime" SG_ 848 DateTmMonth 1000;
BA_ "GenSigSNA" SG_ 848 DateTmMonth "FFh";
BA_ "GenSigStartValue" SG_ 848 DateTmMonth 255;
BA_ "GenSigTimeout_IC" SG_ 848 DateTmMonth 10500;
BA_ "GenSigTimeout_RF_HUB" SG_ 848 DateTmMonth 10500;
BA_ "RID" SG_ 848 DateTmMonth "1112";
BA_ "FlexKomComment" SG_ 848 DateTmSec "Time of day clock";
BA_ "FlexKomIsMotorola" SG_ 848 DateTmSec 1;
BA_ "FlexKomSID" SG_ 848 DateTmSec 398;
BA_ "FlexKomSigLaenge" SG_ 848 DateTmSec 24;
BA_ "FlexKomSigName" SG_ 848 DateTmSec "Clock";
BA_ "FlexKomSigStartPos" SG_ 848 DateTmSec 7;
BA_ "FlexKomSigStartValue" SG_ 848 DateTmSec "FFFFFFh";
BA_ "GenSigCycleTime" SG_ 848 DateTmSec 1000;
BA_ "GenSigSNA" SG_ 848 DateTmSec "FFh";
BA_ "GenSigStartValue" SG_ 848 DateTmSec 255;
BA_ "GenSigTimeout_IC" SG_ 848 DateTmSec 10500;
BA_ "GenSigTimeout_RF_HUB" SG_ 848 DateTmSec 10500;
BA_ "RID" SG_ 848 DateTmSec "1071";
BA_ "FlexKomComment" SG_ 848 DateTmYear "DATE";
BA_ "FlexKomIsMotorola" SG_ 848 DateTmYear 1;
BA_ "FlexKomSID" SG_ 848 DateTmYear 645;
BA_ "FlexKomSigLaenge" SG_ 848 DateTmYear 32;
BA_ "FlexKomSigName" SG_ 848 DateTmYear "DATE";
BA_ "FlexKomSigStartPos" SG_ 848 DateTmYear 31;
BA_ "FlexKomSigStartValue" SG_ 848 DateTmYear "FFFFFFFFh";
BA_ "GenSigCycleTime" SG_ 848 DateTmYear 1000;
BA_ "GenSigSNA" SG_ 848 DateTmYear "FFFFh";
BA_ "GenSigStartValue" SG_ 848 DateTmYear 65535;
BA_ "GenSigTimeout_IC" SG_ 848 DateTmYear 10500;
BA_ "GenSigTimeout_RF_HUB" SG_ 848 DateTmYear 10500;
BA_ "RID" SG_ 848 DateTmYear "1218";
BA_ "FlexKomComment" SG_ 500 ACCFCW_ChimeRq "DAS_A3_PKT";
BA_ "FlexKomIsMotorola" SG_ 500 ACCFCW_ChimeRq 1;
BA_ "FlexKomSID" SG_ 500 ACCFCW_ChimeRq 1043;
BA_ "FlexKomSigLaenge" SG_ 500 ACCFCW_ChimeRq 64;
BA_ "FlexKomSigName" SG_ 500 ACCFCW_ChimeRq "DAS_A3_PKT";
BA_ "FlexKomSigStartPos" SG_ 500 ACCFCW_ChimeRq 7;
BA_ "FlexKomSigStartValue" SG_ 500 ACCFCW_ChimeRq "1FFF0CCB000000FFh";
BA_ "GenSigCycleTime" SG_ 500 ACCFCW_ChimeRq 20;
BA_ "GenSigSNA" SG_ 500 ACCFCW_ChimeRq "0h";
BA_ "GenSigTimeout_IC" SG_ 500 ACCFCW_ChimeRq 210;
BA_ "FlexKomComment" SG_ 500 ACC_Drive_Cmd "DAS_A3_PKT";
BA_ "FlexKomIsMotorola" SG_ 500 ACC_Drive_Cmd 1;
BA_ "FlexKomSID" SG_ 500 ACC_Drive_Cmd 1043;
BA_ "FlexKomSigLaenge" SG_ 500 ACC_Drive_Cmd 64;
BA_ "FlexKomSigName" SG_ 500 ACC_Drive_Cmd "DAS_A3_PKT";
BA_ "FlexKomSigStartPos" SG_ 500 ACC_Drive_Cmd 7;
BA_ "FlexKomSigStartValue" SG_ 500 ACC_Drive_Cmd "1FFF0CCB000000FFh";
BA_ "GenSigCycleTime" SG_ 500 ACC_Drive_Cmd 20;
BA_ "GenSigSNA" SG_ 500 ACC_Drive_Cmd "0h";
BA_ "GenSigTimeout_ORC" SG_ 500 ACC_Drive_Cmd 70;
BA_ "FlexKomComment" SG_ 500 ACC_Enbl "DAS_A3_PKT";
BA_ "FlexKomIsMotorola" SG_ 500 ACC_Enbl 1;
BA_ "FlexKomSID" SG_ 500 ACC_Enbl 1043;
BA_ "FlexKomSigLaenge" SG_ 500 ACC_Enbl 64;
BA_ "FlexKomSigName" SG_ 500 ACC_Enbl "DAS_A3_PKT";
BA_ "FlexKomSigStartPos" SG_ 500 ACC_Enbl 7;
BA_ "FlexKomSigStartValue" SG_ 500 ACC_Enbl "1FFF0CCB000000FFh";
BA_ "GenSigCycleTime" SG_ 500 ACC_Enbl 20;
BA_ "GenSigSNA" SG_ 500 ACC_Enbl "0h";
BA_ "GenSigTimeout_IC" SG_ 500 ACC_Enbl 210;
BA_ "GenSigTimeout_ORC" SG_ 500 ACC_Enbl 70;
BA_ "FlexKomComment" SG_ 500 ACC_Engd "DAS_A3_PKT";
BA_ "FlexKomIsMotorola" SG_ 500 ACC_Engd 1;
BA_ "FlexKomSID" SG_ 500 ACC_Engd 1043;
BA_ "FlexKomSigLaenge" SG_ 500 ACC_Engd 64;
BA_ "FlexKomSigName" SG_ 500 ACC_Engd "DAS_A3_PKT";
BA_ "FlexKomSigStartPos" SG_ 500 ACC_Engd 7;
BA_ "FlexKomSigStartValue" SG_ 500 ACC_Engd "1FFF0CCB000000FFh";
BA_ "GenSigCycleTime" SG_ 500 ACC_Engd 20;
BA_ "GenSigSNA" SG_ 500 ACC_Engd "0h";
BA_ "GenSigTimeout_IC" SG_ 500 ACC_Engd 210;
BA_ "GenSigTimeout_ORC" SG_ 500 ACC_Engd 70;
BA_ "RID" SG_ 500 ACC_Engd "6421";
BA_ "FlexKomComment" SG_ 500 ACC_Still_Cmd "DAS_A3_PKT";
BA_ "FlexKomIsMotorola" SG_ 500 ACC_Still_Cmd 1;
BA_ "FlexKomSID" SG_ 500 ACC_Still_Cmd 1043;
BA_ "FlexKomSigLaenge" SG_ 500 ACC_Still_Cmd 64;
BA_ "FlexKomSigName" SG_ 500 ACC_Still_Cmd "DAS_A3_PKT";
BA_ "FlexKomSigStartPos" SG_ 500 ACC_Still_Cmd 7;
BA_ "FlexKomSigStartValue" SG_ 500 ACC_Still_Cmd "1FFF0CCB000000FFh";
BA_ "GenSigCycleTime" SG_ 500 ACC_Still_Cmd 20;
BA_ "GenSigSNA" SG_ 500 ACC_Still_Cmd "0h";
BA_ "GenSigTimeout_ORC" SG_ 500 ACC_Still_Cmd 70;
BA_ "FlexKomComment" SG_ 500 As_DispRq "DAS_A3_PKT";
BA_ "FlexKomIsMotorola" SG_ 500 As_DispRq 1;
BA_ "FlexKomSID" SG_ 500 As_DispRq 1043;
BA_ "FlexKomSigLaenge" SG_ 500 As_DispRq 64;
BA_ "FlexKomSigName" SG_ 500 As_DispRq "DAS_A3_PKT";
BA_ "FlexKomSigStartPos" SG_ 500 As_DispRq 7;
BA_ "FlexKomSigStartValue" SG_ 500 As_DispRq "1FFF0CCB000000FFh";
BA_ "GenSigCycleTime" SG_ 500 As_DispRq 20;
BA_ "GenSigSNA" SG_ 500 As_DispRq "3h";
BA_ "GenSigTimeout_IC" SG_ 500 As_DispRq 210;
BA_ "GenSigTimeout_ORC" SG_ 500 As_DispRq 70;
BA_ "FlexKomComment" SG_ 500 Brk_Jrk_Rq "DAS_A3_PKT";
BA_ "FlexKomIsMotorola" SG_ 500 Brk_Jrk_Rq 1;
BA_ "FlexKomSID" SG_ 500 Brk_Jrk_Rq 1043;
BA_ "FlexKomSigLaenge" SG_ 500 Brk_Jrk_Rq 64;
BA_ "FlexKomSigName" SG_ 500 Brk_Jrk_Rq "DAS_A3_PKT";
BA_ "FlexKomSigStartPos" SG_ 500 Brk_Jrk_Rq 7;
BA_ "FlexKomSigStartValue" SG_ 500 Brk_Jrk_Rq "1FFF0CCB000000FFh";
BA_ "GenSigCycleTime" SG_ 500 Brk_Jrk_Rq 20;
BA_ "GenSigSNA" SG_ 500 Brk_Jrk_Rq "0h";
BA_ "FlexKomComment" SG_ 500 Brk_PreFill_Rq "DAS_A3_PKT";
BA_ "FlexKomIsMotorola" SG_ 500 Brk_PreFill_Rq 1;
BA_ "FlexKomSID" SG_ 500 Brk_PreFill_Rq 1043;
BA_ "FlexKomSigLaenge" SG_ 500 Brk_PreFill_Rq 64;
BA_ "FlexKomSigName" SG_ 500 Brk_PreFill_Rq "DAS_A3_PKT";
BA_ "FlexKomSigStartPos" SG_ 500 Brk_PreFill_Rq 7;
BA_ "FlexKomSigStartValue" SG_ 500 Brk_PreFill_Rq "1FFF0CCB000000FFh";
BA_ "GenSigCycleTime" SG_ 500 Brk_PreFill_Rq 20;
BA_ "GenSigSNA" SG_ 500 Brk_PreFill_Rq "0h";
BA_ "GenSigTimeout_ORC" SG_ 500 Brk_PreFill_Rq 70;
BA_ "FlexKomComment" SG_ 500 CRC_DAS_A3 "DAS_A3_PKT";
BA_ "FlexKomIsMotorola" SG_ 500 CRC_DAS_A3 1;
BA_ "FlexKomSID" SG_ 500 CRC_DAS_A3 1043;
BA_ "FlexKomSigLaenge" SG_ 500 CRC_DAS_A3 64;
BA_ "FlexKomSigName" SG_ 500 CRC_DAS_A3 "DAS_A3_PKT";
BA_ "FlexKomSigStartPos" SG_ 500 CRC_DAS_A3 7;
BA_ "FlexKomSigStartValue" SG_ 500 CRC_DAS_A3 "1FFF0CCB000000FFh";
BA_ "GenSigCycleTime" SG_ 500 CRC_DAS_A3 20;
BA_ "GenSigSNA" SG_ 500 CRC_DAS_A3 "FFh";
BA_ "GenSigStartValue" SG_ 500 CRC_DAS_A3 255;
BA_ "FlexKomComment" SG_ 500 DAS_ACCEL_Rq "DAS_A3_PKT";
BA_ "FlexKomIsMotorola" SG_ 500 DAS_ACCEL_Rq 1;
BA_ "FlexKomSID" SG_ 500 DAS_ACCEL_Rq 1043;
BA_ "FlexKomSigLaenge" SG_ 500 DAS_ACCEL_Rq 64;
BA_ "FlexKomSigName" SG_ 500 DAS_ACCEL_Rq "DAS_A3_PKT";
BA_ "FlexKomSigStartPos" SG_ 500 DAS_ACCEL_Rq 7;
BA_ "FlexKomSigStartValue" SG_ 500 DAS_ACCEL_Rq "1FFF0CCB000000FFh";
BA_ "GenSigCycleTime" SG_ 500 DAS_ACCEL_Rq 20;
BA_ "GenSigSNA" SG_ 500 DAS_ACCEL_Rq "FFFh";
BA_ "GenSigStartValue" SG_ 500 DAS_ACCEL_Rq 3275;
BA_ "GenSigTimeout_ORC" SG_ 500 DAS_ACCEL_Rq 70;
BA_ "FlexKomComment" SG_ 500 DAS_Rq_ID "DAS_A3_PKT";
BA_ "FlexKomIsMotorola" SG_ 500 DAS_Rq_ID 1;
BA_ "FlexKomSID" SG_ 500 DAS_Rq_ID 1043;
BA_ "FlexKomSigLaenge" SG_ 500 DAS_Rq_ID 64;
BA_ "FlexKomSigName" SG_ 500 DAS_Rq_ID "DAS_A3_PKT";
BA_ "FlexKomSigStartPos" SG_ 500 DAS_Rq_ID 7;
BA_ "FlexKomSigStartValue" SG_ 500 DAS_Rq_ID "1FFF0CCB000000FFh";
BA_ "GenSigCycleTime" SG_ 500 DAS_Rq_ID 20;
BA_ "GenSigSNA" SG_ 500 DAS_Rq_ID "7h";
BA_ "GenSigTimeout_ORC" SG_ 500 DAS_Rq_ID 70;
BA_ "FlexKomComment" SG_ 500 DAS_Sts "DAS_A3_PKT";
BA_ "FlexKomIsMotorola" SG_ 500 DAS_Sts 1;
BA_ "FlexKomSID" SG_ 500 DAS_Sts 1043;
BA_ "FlexKomSigLaenge" SG_ 500 DAS_Sts 64;
BA_ "FlexKomSigName" SG_ 500 DAS_Sts "DAS_A3_PKT";
BA_ "FlexKomSigStartPos" SG_ 500 DAS_Sts 7;
BA_ "FlexKomSigStartValue" SG_ 500 DAS_Sts "1FFF0CCB000000FFh";
BA_ "GenSigCycleTime" SG_ 500 DAS_Sts 20;
BA_ "GenSigSNA" SG_ 500 DAS_Sts "3h";
BA_ "FlexKomComment" SG_ 500 DsblFuelShutOff_ACC "DAS_A3_PKT";
BA_ "FlexKomIsMotorola" SG_ 500 DsblFuelShutOff_ACC 1;
BA_ "FlexKomSID" SG_ 500 DsblFuelShutOff_ACC 1043;
BA_ "FlexKomSigLaenge" SG_ 500 DsblFuelShutOff_ACC 64;
BA_ "FlexKomSigName" SG_ 500 DsblFuelShutOff_ACC "DAS_A3_PKT";
BA_ "FlexKomSigStartPos" SG_ 500 DsblFuelShutOff_ACC 7;
BA_ "FlexKomSigStartValue" SG_ 500 DsblFuelShutOff_ACC "1FFF0CCB000000FFh";
BA_ "GenSigCycleTime" SG_ 500 DsblFuelShutOff_ACC 20;
BA_ "GenSigSNA" SG_ 500 DsblFuelShutOff_ACC "0h";
BA_ "FlexKomComment" SG_ 500 MC_DAS_A3 "DAS_A3_PKT";
BA_ "FlexKomIsMotorola" SG_ 500 MC_DAS_A3 1;
BA_ "FlexKomSID" SG_ 500 MC_DAS_A3 1043;
BA_ "FlexKomSigLaenge" SG_ 500 MC_DAS_A3 64;
BA_ "FlexKomSigName" SG_ 500 MC_DAS_A3 "DAS_A3_PKT";
BA_ "FlexKomSigStartPos" SG_ 500 MC_DAS_A3 7;
BA_ "FlexKomSigStartValue" SG_ 500 MC_DAS_A3 "1FFF0CCB000000FFh";
BA_ "GenSigCycleTime" SG_ 500 MC_DAS_A3 20;
BA_ "GenSigSNA" SG_ 500 MC_DAS_A3 "0h";
BA_ "GenSigStartValue" SG_ 499 MC_DAS_A3_A 15;
BA_ "GenSigStartValue" SG_ 499 CRC_DAS_A3_A 255;
BA_ "FlexKomComment" SG_ 499 Brk_PreFill_Rq "DAS_A3_PKT";
BA_ "FlexKomIsMotorola" SG_ 499 Brk_PreFill_Rq 1;
BA_ "FlexKomSID" SG_ 499 Brk_PreFill_Rq 1043;
BA_ "FlexKomSigLaenge" SG_ 499 Brk_PreFill_Rq 64;
BA_ "FlexKomSigName" SG_ 499 Brk_PreFill_Rq "DAS_A3_PKT";
BA_ "FlexKomSigStartPos" SG_ 499 Brk_PreFill_Rq 7;
BA_ "FlexKomSigStartValue" SG_ 499 Brk_PreFill_Rq "1FFF0CCB000000FFh";
BA_ "GenSigCycleTime" SG_ 499 Brk_PreFill_Rq 10;
BA_ "GenSigSNA" SG_ 499 Brk_PreFill_Rq "0h";
BA_ "FlexKomComment" SG_ 499 DAS_EPB_APPLY_RQ "DAS_A5 Packet";
BA_ "FlexKomIsMotorola" SG_ 499 DAS_EPB_APPLY_RQ 1;
BA_ "FlexKomSID" SG_ 499 DAS_EPB_APPLY_RQ 2333;
BA_ "FlexKomSigLaenge" SG_ 499 DAS_EPB_APPLY_RQ 64;
BA_ "FlexKomSigName" SG_ 499 DAS_EPB_APPLY_RQ "DAS_A5_PKT";
BA_ "FlexKomSigStartPos" SG_ 499 DAS_EPB_APPLY_RQ 7;
BA_ "FlexKomSigStartValue" SG_ 499 DAS_EPB_APPLY_RQ "000000FF000000FFh";
BA_ "GenSigCycleTime" SG_ 499 DAS_EPB_APPLY_RQ 10;
BA_ "GenSigSNA" SG_ 499 DAS_EPB_APPLY_RQ "0h";
BA_ "FlexKomComment" SG_ 499 DAS_EPB_RELSE_RQ "DAS_A5 Packet";
BA_ "FlexKomIsMotorola" SG_ 499 DAS_EPB_RELSE_RQ 1;
BA_ "FlexKomSID" SG_ 499 DAS_EPB_RELSE_RQ 2333;
BA_ "FlexKomSigLaenge" SG_ 499 DAS_EPB_RELSE_RQ 64;
BA_ "FlexKomSigName" SG_ 499 DAS_EPB_RELSE_RQ "DAS_A5_PKT";
BA_ "FlexKomSigStartPos" SG_ 499 DAS_EPB_RELSE_RQ 7;
BA_ "FlexKomSigStartValue" SG_ 499 DAS_EPB_RELSE_RQ "000000FF000000FFh";
BA_ "GenSigCycleTime" SG_ 499 DAS_EPB_RELSE_RQ 10;
BA_ "GenSigSNA" SG_ 499 DAS_EPB_RELSE_RQ "0h";
BA_ "FlexKomComment" SG_ 499 LFC_Request "LFC_Pkt";
BA_ "FlexKomIsMotorola" SG_ 499 LFC_Request 1;
BA_ "FlexKomSID" SG_ 499 LFC_Request 9213;
BA_ "FlexKomSigLaenge" SG_ 499 LFC_Request 48;
BA_ "FlexKomSigName" SG_ 499 LFC_Request "RHSC_SDS_SteerControl_Pkt";
BA_ "FlexKomSigStartPos" SG_ 499 LFC_Request 7;
BA_ "FlexKomSigStartValue" SG_ 499 LFC_Request "0400000000FFh";
BA_ "GenSigCycleTime" SG_ 499 LFC_Request 10;
BA_ "FlexKomComment" SG_ 499 LFC_Request_Type "LFC_Pkt";
BA_ "FlexKomIsMotorola" SG_ 499 LFC_Request_Type 1;
BA_ "FlexKomSID" SG_ 499 LFC_Request_Type 9213;
BA_ "FlexKomSigLaenge" SG_ 499 LFC_Request_Type 48;
BA_ "FlexKomSigName" SG_ 499 LFC_Request_Type "RHSC_SDS_SteerControl_Pkt";
BA_ "FlexKomSigStartPos" SG_ 499 LFC_Request_Type 7;
BA_ "FlexKomSigStartValue" SG_ 499 LFC_Request_Type "0400000000FFh";
BA_ "GenSigCycleTime" SG_ 499 LFC_Request_Type 10;
BA_ "FlexKomComment" SG_ 499 RHSC_OpenLoopBraking_Rq "LFC_Pkt";
BA_ "FlexKomIsMotorola" SG_ 499 RHSC_OpenLoopBraking_Rq 1;
BA_ "FlexKomSID" SG_ 499 RHSC_OpenLoopBraking_Rq 9213;
BA_ "FlexKomSigLaenge" SG_ 499 RHSC_OpenLoopBraking_Rq 48;
BA_ "FlexKomSigName" SG_ 499 RHSC_OpenLoopBraking_Rq "RHSC_SDS_SteerControl_Pkt";
BA_ "FlexKomSigStartPos" SG_ 499 RHSC_OpenLoopBraking_Rq 7;
BA_ "FlexKomSigStartValue" SG_ 499 RHSC_OpenLoopBraking_Rq "0400000000FFh";
BA_ "GenSigCycleTime" SG_ 499 RHSC_OpenLoopBraking_Rq 10;
BA_ "FlexKomComment" SG_ 499 SDS_Engaged_State "DAS_A5 Packet";
BA_ "FlexKomIsMotorola" SG_ 499 SDS_Engaged_State 1;
BA_ "FlexKomSID" SG_ 499 SDS_Engaged_State 2333;
BA_ "FlexKomSigLaenge" SG_ 499 SDS_Engaged_State 64;
BA_ "FlexKomSigName" SG_ 499 SDS_Engaged_State "DAS_A5_PKT";
BA_ "FlexKomSigStartPos" SG_ 499 SDS_Engaged_State 7;
BA_ "FlexKomSigStartValue" SG_ 499 SDS_Engaged_State "000000FF000000FFh";
BA_ "GenSigCycleTime" SG_ 499 SDS_Engaged_State 10;
BA_ "GenSigSNA" SG_ 499 SDS_Engaged_State "3h";
BA_ "FlexKomComment" SG_ 501 ACCFaulted "DAS_A4 Packet";
BA_ "FlexKomIsMotorola" SG_ 501 ACCFaulted 1;
BA_ "FlexKomSID" SG_ 501 ACCFaulted 1717;
BA_ "FlexKomSigLaenge" SG_ 501 ACCFaulted 64;
BA_ "FlexKomSigName" SG_ 501 ACCFaulted "DAS_A4_PKT";
BA_ "FlexKomSigStartPos" SG_ 501 ACCFaulted 7;
BA_ "FlexKomSigStartValue" SG_ 501 ACCFaulted "00FFFF00000000FFh";
BA_ "GenSigCycleTime" SG_ 501 ACCFaulted 60;
BA_ "GenSigSNA" SG_ 501 ACCFaulted "0h";
BA_ "GenSigTimeout_IC" SG_ 501 ACCFaulted 630;
BA_ "GenSigTimeout_ORC" SG_ 501 ACCFaulted 210;
BA_ "FlexKomComment" SG_ 501 ACCNA_DASMSts "DAS_A4 Packet";
BA_ "FlexKomIsMotorola" SG_ 501 ACCNA_DASMSts 1;
BA_ "FlexKomSID" SG_ 501 ACCNA_DASMSts 1717;
BA_ "FlexKomSigLaenge" SG_ 501 ACCNA_DASMSts 64;
BA_ "FlexKomSigName" SG_ 501 ACCNA_DASMSts "DAS_A4_PKT";
BA_ "FlexKomSigStartPos" SG_ 501 ACCNA_DASMSts 7;
BA_ "FlexKomSigStartValue" SG_ 501 ACCNA_DASMSts "00FFFF00000000FFh";
BA_ "GenSigCycleTime" SG_ 501 ACCNA_DASMSts 60;
BA_ "GenSigSNA" SG_ 501 ACCNA_DASMSts "0h";
BA_ "GenSigTimeout_IC" SG_ 501 ACCNA_DASMSts 630;
BA_ "GenSigTimeout_ORC" SG_ 501 ACCNA_DASMSts 210;
BA_ "FlexKomComment" SG_ 501 ACCOnOff "DAS_A4 Packet";
BA_ "FlexKomIsMotorola" SG_ 501 ACCOnOff 1;
BA_ "FlexKomSID" SG_ 501 ACCOnOff 1717;
BA_ "FlexKomSigLaenge" SG_ 501 ACCOnOff 64;
BA_ "FlexKomSigName" SG_ 501 ACCOnOff "DAS_A4_PKT";
BA_ "FlexKomSigStartPos" SG_ 501 ACCOnOff 7;
BA_ "FlexKomSigStartValue" SG_ 501 ACCOnOff "00FFFF00000000FFh";
BA_ "GenSigCycleTime" SG_ 501 ACCOnOff 60;
BA_ "GenSigSNA" SG_ 501 ACCOnOff "7h";
BA_ "GenSigTimeout_IC" SG_ 501 ACCOnOff 630;
BA_ "GenSigTimeout_ORC" SG_ 501 ACCOnOff 210;
BA_ "FlexKomComment" SG_ 501 ACC_HMI_SCRN_REQ "DAS_A4 Packet";
BA_ "FlexKomIsMotorola" SG_ 501 ACC_HMI_SCRN_REQ 1;
BA_ "FlexKomSID" SG_ 501 ACC_HMI_SCRN_REQ 1717;
BA_ "FlexKomSigLaenge" SG_ 501 ACC_HMI_SCRN_REQ 64;
BA_ "FlexKomSigName" SG_ 501 ACC_HMI_SCRN_REQ "DAS_A4_PKT";
BA_ "FlexKomSigStartPos" SG_ 501 ACC_HMI_SCRN_REQ 7;
BA_ "FlexKomSigStartValue" SG_ 501 ACC_HMI_SCRN_REQ "00FFFF00000000FFh";
BA_ "GenSigCycleTime" SG_ 501 ACC_HMI_SCRN_REQ 60;
BA_ "GenSigSNA" SG_ 501 ACC_HMI_SCRN_REQ "0h";
BA_ "GenSigTimeout_IC" SG_ 501 ACC_HMI_SCRN_REQ 630;
BA_ "FlexKomComment" SG_ 501 ACConlyNA_DASMSts "DAS_A4 Packet";
BA_ "FlexKomIsMotorola" SG_ 501 ACConlyNA_DASMSts 1;
BA_ "FlexKomSID" SG_ 501 ACConlyNA_DASMSts 1717;
BA_ "FlexKomSigLaenge" SG_ 501 ACConlyNA_DASMSts 64;
BA_ "FlexKomSigName" SG_ 501 ACConlyNA_DASMSts "DAS_A4_PKT";
BA_ "FlexKomSigStartPos" SG_ 501 ACConlyNA_DASMSts 7;
BA_ "FlexKomSigStartValue" SG_ 501 ACConlyNA_DASMSts "00FFFF00000000FFh";
BA_ "GenSigCycleTime" SG_ 501 ACConlyNA_DASMSts 60;
BA_ "GenSigSNA" SG_ 501 ACConlyNA_DASMSts "0h";
BA_ "GenSigTimeout_IC" SG_ 501 ACConlyNA_DASMSts 630;
BA_ "FlexKomComment" SG_ 501 CIPV_Fused "DAS_A4 Packet";
BA_ "FlexKomIsMotorola" SG_ 501 CIPV_Fused 1;
BA_ "FlexKomSID" SG_ 501 CIPV_Fused 1717;
BA_ "FlexKomSigLaenge" SG_ 501 CIPV_Fused 64;
BA_ "FlexKomSigName" SG_ 501 CIPV_Fused "DAS_A4_PKT";
BA_ "FlexKomSigStartPos" SG_ 501 CIPV_Fused 7;
BA_ "FlexKomSigStartValue" SG_ 501 CIPV_Fused "00FFFF00000000FFh";
BA_ "GenSigCycleTime" SG_ 501 CIPV_Fused 60;
BA_ "GenSigSNA" SG_ 501 CIPV_Fused "0h";
BA_ "GenSigTimeout_ORC" SG_ 501 CIPV_Fused 210;
BA_ "FlexKomComment" SG_ 501 CameraBlocked "DAS_A4 Packet";
BA_ "FlexKomIsMotorola" SG_ 501 CameraBlocked 1;
BA_ "FlexKomSID" SG_ 501 CameraBlocked 1717;
BA_ "FlexKomSigLaenge" SG_ 501 CameraBlocked 64;
BA_ "FlexKomSigName" SG_ 501 CameraBlocked "DAS_A4_PKT";
BA_ "FlexKomSigStartPos" SG_ 501 CameraBlocked 7;
BA_ "FlexKomSigStartValue" SG_ 501 CameraBlocked "00FFFF00000000FFh";
BA_ "GenSigCycleTime" SG_ 501 CameraBlocked 60;
BA_ "GenSigSNA" SG_ 501 CameraBlocked "0h";
BA_ "GenSigTimeout_IC" SG_ 501 CameraBlocked 630;
BA_ "GenSigTimeout_ORC" SG_ 501 CameraBlocked 210;
BA_ "FlexKomComment" SG_ 501 CameraFailure "DAS_A4 Packet";
BA_ "FlexKomIsMotorola" SG_ 501 CameraFailure 1;
BA_ "FlexKomSID" SG_ 501 CameraFailure 1717;
BA_ "FlexKomSigLaenge" SG_ 501 CameraFailure 64;
BA_ "FlexKomSigName" SG_ 501 CameraFailure "DAS_A4_PKT";
BA_ "FlexKomSigStartPos" SG_ 501 CameraFailure 7;
BA_ "FlexKomSigStartValue" SG_ 501 CameraFailure "00FFFF00000000FFh";
BA_ "GenSigCycleTime" SG_ 501 CameraFailure 60;
BA_ "GenSigSNA" SG_ 501 CameraFailure "0h";
BA_ "GenSigTimeout_IC" SG_ 501 CameraFailure 630;
BA_ "GenSigTimeout_ORC" SG_ 501 CameraFailure 210;
BA_ "FlexKomComment" SG_ 501 FCWBrakingOff "DAS_A4 Packet";
BA_ "FlexKomIsMotorola" SG_ 501 FCWBrakingOff 1;
BA_ "FlexKomSID" SG_ 501 FCWBrakingOff 1717;
BA_ "FlexKomSigLaenge" SG_ 501 FCWBrakingOff 64;
BA_ "FlexKomSigName" SG_ 501 FCWBrakingOff "DAS_A4_PKT";
BA_ "FlexKomSigStartPos" SG_ 501 FCWBrakingOff 7;
BA_ "FlexKomSigStartValue" SG_ 501 FCWBrakingOff "00FFFF00000000FFh";
BA_ "GenSigCycleTime" SG_ 501 FCWBrakingOff 60;
BA_ "GenSigSNA" SG_ 501 FCWBrakingOff "0h";
BA_ "GenSigTimeout_IC" SG_ 501 FCWBrakingOff 630;
BA_ "GenSigTimeout_ORC" SG_ 501 FCWBrakingOff 210;
BA_ "FlexKomComment" SG_ 501 FCW_BrkOn "DAS_A4 Packet";
BA_ "FlexKomIsMotorola" SG_ 501 FCW_BrkOn 1;
BA_ "FlexKomSID" SG_ 501 FCW_BrkOn 1717;
BA_ "FlexKomSigLaenge" SG_ 501 FCW_BrkOn 64;
BA_ "FlexKomSigName" SG_ 501 FCW_BrkOn "DAS_A4_PKT";
BA_ "FlexKomSigStartPos" SG_ 501 FCW_BrkOn 7;
BA_ "FlexKomSigStartValue" SG_ 501 FCW_BrkOn "00FFFF00000000FFh";
BA_ "GenSigCycleTime" SG_ 501 FCW_BrkOn 60;
BA_ "GenSigSNA" SG_ 501 FCW_BrkOn "0h";
BA_ "GenSigTimeout_CBC" SG_ 501 FCW_BrkOn 630;
BA_ "GenSigTimeout_IC" SG_ 501 FCW_BrkOn 630;
BA_ "GenSigTimeout_ORC" SG_ 501 FCW_BrkOn 210;
BA_ "RID" SG_ 501 FCW_BrkOn "1882";
BA_ "FlexKomComment" SG_ 501 FCW_Error "DAS_A4 Packet";
BA_ "FlexKomIsMotorola" SG_ 501 FCW_Error 1;
BA_ "FlexKomSID" SG_ 501 FCW_Error 1717;
BA_ "FlexKomSigLaenge" SG_ 501 FCW_Error 64;
BA_ "FlexKomSigName" SG_ 501 FCW_Error "DAS_A4_PKT";
BA_ "FlexKomSigStartPos" SG_ 501 FCW_Error 7;
BA_ "FlexKomSigStartValue" SG_ 501 FCW_Error "00FFFF00000000FFh";
BA_ "GenSigCycleTime" SG_ 501 FCW_Error 60;
BA_ "GenSigSNA" SG_ 501 FCW_Error "3h";
BA_ "GenSigTimeout_IC" SG_ 501 FCW_Error 630;
BA_ "GenSigTimeout_ORC" SG_ 501 FCW_Error 210;
BA_ "FlexKomComment" SG_ 501 FCWonlyNA_DASMSts "DAS_A4 Packet";
BA_ "FlexKomIsMotorola" SG_ 501 FCWonlyNA_DASMSts 1;
BA_ "FlexKomSID" SG_ 501 FCWonlyNA_DASMSts 1717;
BA_ "FlexKomSigLaenge" SG_ 501 FCWonlyNA_DASMSts 64;
BA_ "FlexKomSigName" SG_ 501 FCWonlyNA_DASMSts "DAS_A4_PKT";
BA_ "FlexKomSigStartPos" SG_ 501 FCWonlyNA_DASMSts 7;
BA_ "FlexKomSigStartValue" SG_ 501 FCWonlyNA_DASMSts "00FFFF00000000FFh";
BA_ "GenSigCycleTime" SG_ 501 FCWonlyNA_DASMSts 60;
BA_ "GenSigSNA" SG_ 501 FCWonlyNA_DASMSts "0h";
BA_ "FlexKomComment" SG_ 501 HMI_Screens "DAS_A4 Packet";
BA_ "FlexKomIsMotorola" SG_ 501 HMI_Screens 1;
BA_ "FlexKomSID" SG_ 501 HMI_Screens 1717;
BA_ "FlexKomSigLaenge" SG_ 501 HMI_Screens 64;
BA_ "FlexKomSigName" SG_ 501 HMI_Screens "DAS_A4_PKT";
BA_ "FlexKomSigStartPos" SG_ 501 HMI_Screens 7;
BA_ "FlexKomSigStartValue" SG_ 501 HMI_Screens "00FFFF00000000FFh";
BA_ "GenSigCycleTime" SG_ 501 HMI_Screens 60;
BA_ "GenSigSNA" SG_ 501 HMI_Screens "FFh";
BA_ "GenSigTimeout_IC" SG_ 501 HMI_Screens 630;
BA_ "GenSigTimeout_ORC" SG_ 501 HMI_Screens 210;
BA_ "FlexKomComment" SG_ 501 NCCNA_DASMSts "DAS_A4 Packet";
BA_ "FlexKomIsMotorola" SG_ 501 NCCNA_DASMSts 1;
BA_ "FlexKomSID" SG_ 501 NCCNA_DASMSts 1717;
BA_ "FlexKomSigLaenge" SG_ 501 NCCNA_DASMSts 64;
BA_ "FlexKomSigName" SG_ 501 NCCNA_DASMSts "DAS_A4_PKT";
BA_ "FlexKomSigStartPos" SG_ 501 NCCNA_DASMSts 7;
BA_ "FlexKomSigStartValue" SG_ 501 NCCNA_DASMSts "00FFFF00000000FFh";
BA_ "GenSigCycleTime" SG_ 501 NCCNA_DASMSts 60;
BA_ "GenSigSNA" SG_ 501 NCCNA_DASMSts "0h";
BA_ "GenSigTimeout_IC" SG_ 501 NCCNA_DASMSts 630;
BA_ "GenSigTimeout_ORC" SG_ 501 NCCNA_DASMSts 210;
BA_ "FlexKomComment" SG_ 501 NCConlyNA_DASMSts "DAS_A4 Packet";
BA_ "FlexKomIsMotorola" SG_ 501 NCConlyNA_DASMSts 1;
BA_ "FlexKomSID" SG_ 501 NCConlyNA_DASMSts 1717;
BA_ "FlexKomSigLaenge" SG_ 501 NCConlyNA_DASMSts 64;
BA_ "FlexKomSigName" SG_ 501 NCConlyNA_DASMSts "DAS_A4_PKT";
BA_ "FlexKomSigStartPos" SG_ 501 NCConlyNA_DASMSts 7;
BA_ "FlexKomSigStartValue" SG_ 501 NCConlyNA_DASMSts "00FFFF00000000FFh";
BA_ "GenSigCycleTime" SG_ 501 NCConlyNA_DASMSts 60;
BA_ "GenSigSNA" SG_ 501 NCConlyNA_DASMSts "0h";
BA_ "GenSigTimeout_IC" SG_ 501 NCConlyNA_DASMSts 630;
BA_ "FlexKomComment" SG_ 501 ObjIntrstDist "DAS_A4 Packet";
BA_ "FlexKomIsMotorola" SG_ 501 ObjIntrstDist 1;
BA_ "FlexKomSID" SG_ 501 ObjIntrstDist 1717;
BA_ "FlexKomSigLaenge" SG_ 501 ObjIntrstDist 64;
BA_ "FlexKomSigName" SG_ 501 ObjIntrstDist "DAS_A4_PKT";
BA_ "FlexKomSigStartPos" SG_ 501 ObjIntrstDist 7;
BA_ "FlexKomSigStartValue" SG_ 501 ObjIntrstDist "00FFFF00000000FFh";
BA_ "GenSigCycleTime" SG_ 501 ObjIntrstDist 60;
BA_ "GenSigSNA" SG_ 501 ObjIntrstDist "FFh";
BA_ "GenSigStartValue" SG_ 501 ObjIntrstDist 255;
BA_ "GenSigTimeout_ORC" SG_ 501 ObjIntrstDist 210;
BA_ "FlexKomComment" SG_ 501 RadarBlocked "DAS_A4 Packet";
BA_ "FlexKomIsMotorola" SG_ 501 RadarBlocked 1;
BA_ "FlexKomSID" SG_ 501 RadarBlocked 1717;
BA_ "FlexKomSigLaenge" SG_ 501 RadarBlocked 64;
BA_ "FlexKomSigName" SG_ 501 RadarBlocked "DAS_A4_PKT";
BA_ "FlexKomSigStartPos" SG_ 501 RadarBlocked 7;
BA_ "FlexKomSigStartValue" SG_ 501 RadarBlocked "00FFFF00000000FFh";
BA_ "GenSigCycleTime" SG_ 501 RadarBlocked 60;
BA_ "GenSigSNA" SG_ 501 RadarBlocked "0h";
BA_ "GenSigTimeout_IC" SG_ 501 RadarBlocked 630;
BA_ "GenSigTimeout_ORC" SG_ 501 RadarBlocked 210;
BA_ "FlexKomComment" SG_ 501 SetSpeed_KPH "DAS_A4 Packet";
BA_ "FlexKomIsMotorola" SG_ 501 SetSpeed_KPH 1;
BA_ "FlexKomSID" SG_ 501 SetSpeed_KPH 1717;
BA_ "FlexKomSigLaenge" SG_ 501 SetSpeed_KPH 64;
BA_ "FlexKomSigName" SG_ 501 SetSpeed_KPH "DAS_A4_PKT";
BA_ "FlexKomSigStartPos" SG_ 501 SetSpeed_KPH 7;
BA_ "FlexKomSigStartValue" SG_ 501 SetSpeed_KPH "00FFFF00000000FFh";
BA_ "GenSigCycleTime" SG_ 501 SetSpeed_KPH 60;
BA_ "GenSigSNA" SG_ 501 SetSpeed_KPH "FFh";
BA_ "GenSigStartValue" SG_ 501 SetSpeed_KPH 255;
BA_ "GenSigTimeout_IC" SG_ 501 SetSpeed_KPH 630;
BA_ "FlexKomComment" SG_ 501 SetSpeed_MPH "DAS_A4 Packet";
BA_ "FlexKomIsMotorola" SG_ 501 SetSpeed_MPH 1;
BA_ "FlexKomSID" SG_ 501 SetSpeed_MPH 1717;
BA_ "FlexKomSigLaenge" SG_ 501 SetSpeed_MPH 64;
BA_ "FlexKomSigName" SG_ 501 SetSpeed_MPH "DAS_A4_PKT";
BA_ "FlexKomSigStartPos" SG_ 501 SetSpeed_MPH 7;
BA_ "FlexKomSigStartValue" SG_ 501 SetSpeed_MPH "00FFFF00000000FFh";
BA_ "GenSigCycleTime" SG_ 501 SetSpeed_MPH 60;
BA_ "GenSigSNA" SG_ 501 SetSpeed_MPH "FFh";
BA_ "GenSigStartValue" SG_ 501 SetSpeed_MPH 255;
BA_ "GenSigTimeout_IC" SG_ 501 SetSpeed_MPH 630;
BA_ "GenSigTimeout_ORC" SG_ 501 SetSpeed_MPH 210;
BA_ "FlexKomComment" SG_ 501 Sm_ICON_Dspl "DAS_A4 Packet";
BA_ "FlexKomIsMotorola" SG_ 501 Sm_ICON_Dspl 1;
BA_ "FlexKomSID" SG_ 501 Sm_ICON_Dspl 1717;
BA_ "FlexKomSigLaenge" SG_ 501 Sm_ICON_Dspl 64;
BA_ "FlexKomSigName" SG_ 501 Sm_ICON_Dspl "DAS_A4_PKT";
BA_ "FlexKomSigStartPos" SG_ 501 Sm_ICON_Dspl 7;
BA_ "FlexKomSigStartValue" SG_ 501 Sm_ICON_Dspl "00FFFF00000000FFh";
BA_ "GenSigCycleTime" SG_ 501 Sm_ICON_Dspl 60;
BA_ "GenSigSNA" SG_ 501 Sm_ICON_Dspl "3Fh";
BA_ "GenSigTimeout_IC" SG_ 501 Sm_ICON_Dspl 630;
BA_ "FlexKomComment" SG_ 625 CRC_DAS_A5 "DAS_A5 Packet";
BA_ "FlexKomIsMotorola" SG_ 625 CRC_DAS_A5 1;
BA_ "FlexKomSID" SG_ 625 CRC_DAS_A5 2333;
BA_ "FlexKomSigLaenge" SG_ 625 CRC_DAS_A5 64;
BA_ "FlexKomSigName" SG_ 625 CRC_DAS_A5 "DAS_A5_PKT";
BA_ "FlexKomSigStartPos" SG_ 625 CRC_DAS_A5 7;
BA_ "FlexKomSigStartValue" SG_ 625 CRC_DAS_A5 "000000FF000000FFh";
BA_ "GenSigCycleTime" SG_ 625 CRC_DAS_A5 20;
BA_ "GenSigSNA" SG_ 625 CRC_DAS_A5 "FFh";
BA_ "GenSigStartValue" SG_ 625 CRC_DAS_A5 255;
BA_ "FlexKomComment" SG_ 625 DAS_EPB_APPLY_RQ "DAS_A5 Packet";
BA_ "FlexKomIsMotorola" SG_ 625 DAS_EPB_APPLY_RQ 1;
BA_ "FlexKomSID" SG_ 625 DAS_EPB_APPLY_RQ 2333;
BA_ "FlexKomSigLaenge" SG_ 625 DAS_EPB_APPLY_RQ 64;
BA_ "FlexKomSigName" SG_ 625 DAS_EPB_APPLY_RQ "DAS_A5_PKT";
BA_ "FlexKomSigStartPos" SG_ 625 DAS_EPB_APPLY_RQ 7;
BA_ "FlexKomSigStartValue" SG_ 625 DAS_EPB_APPLY_RQ "000000FF000000FFh";
BA_ "GenSigCycleTime" SG_ 625 DAS_EPB_APPLY_RQ 20;
BA_ "GenSigSNA" SG_ 625 DAS_EPB_APPLY_RQ "0h";
BA_ "GenSigTimeout_RHSC2" SG_ 625 DAS_EPB_APPLY_RQ 70;
BA_ "FlexKomComment" SG_ 625 DAS_EPB_RELSE_RQ "DAS_A5 Packet";
BA_ "FlexKomIsMotorola" SG_ 625 DAS_EPB_RELSE_RQ 1;
BA_ "FlexKomSID" SG_ 625 DAS_EPB_RELSE_RQ 2333;
BA_ "FlexKomSigLaenge" SG_ 625 DAS_EPB_RELSE_RQ 64;
BA_ "FlexKomSigName" SG_ 625 DAS_EPB_RELSE_RQ "DAS_A5_PKT";
BA_ "FlexKomSigStartPos" SG_ 625 DAS_EPB_RELSE_RQ 7;
BA_ "FlexKomSigStartValue" SG_ 625 DAS_EPB_RELSE_RQ "000000FF000000FFh";
BA_ "GenSigCycleTime" SG_ 625 DAS_EPB_RELSE_RQ 20;
BA_ "GenSigSNA" SG_ 625 DAS_EPB_RELSE_RQ "0h";
BA_ "GenSigTimeout_RHSC2" SG_ 625 DAS_EPB_RELSE_RQ 70;
BA_ "FlexKomComment" SG_ 625 FCWBrkTeen "DAS_A5 Packet";
BA_ "FlexKomIsMotorola" SG_ 625 FCWBrkTeen 1;
BA_ "FlexKomSID" SG_ 625 FCWBrkTeen 2333;
BA_ "FlexKomSigLaenge" SG_ 625 FCWBrkTeen 64;
BA_ "FlexKomSigName" SG_ 625 FCWBrkTeen "DAS_A5_PKT";
BA_ "FlexKomSigStartPos" SG_ 625 FCWBrkTeen 7;
BA_ "FlexKomSigStartValue" SG_ 625 FCWBrkTeen "000000FF000000FFh";
BA_ "GenSigCycleTime" SG_ 625 FCWBrkTeen 20;
BA_ "GenSigSNA" SG_ 625 FCWBrkTeen "0h";
BA_ "GenSigTimeout_IC" SG_ 625 FCWBrkTeen 210;
BA_ "GenSigTimeout_ORC" SG_ 625 FCWBrkTeen 70;
BA_ "RID" SG_ 625 FCWBrkTeen "2165";
BA_ "FlexKomComment" SG_ 625 FCWSetting "DAS_A5 Packet";
BA_ "FlexKomIsMotorola" SG_ 625 FCWSetting 1;
BA_ "FlexKomSID" SG_ 625 FCWSetting 2333;
BA_ "FlexKomSigLaenge" SG_ 625 FCWSetting 64;
BA_ "FlexKomSigName" SG_ 625 FCWSetting "DAS_A5_PKT";
BA_ "FlexKomSigStartPos" SG_ 625 FCWSetting 7;
BA_ "FlexKomSigStartValue" SG_ 625 FCWSetting "000000FF000000FFh";
BA_ "GenSigCycleTime" SG_ 625 FCWSetting 20;
BA_ "GenSigSNA" SG_ 625 FCWSetting "0h";
BA_ "GenSigTimeout_CBC" SG_ 625 FCWSetting 210;
BA_ "GenSigTimeout_IC" SG_ 625 FCWSetting 210;
BA_ "GenSigTimeout_ORC" SG_ 625 FCWSetting 70;
BA_ "RID" SG_ 625 FCWSetting "2163";
BA_ "FlexKomComment" SG_ 625 FCWSettingTeen "DAS_A5 Packet";
BA_ "FlexKomIsMotorola" SG_ 625 FCWSettingTeen 1;
BA_ "FlexKomSID" SG_ 625 FCWSettingTeen 2333;
BA_ "FlexKomSigLaenge" SG_ 625 FCWSettingTeen 64;
BA_ "FlexKomSigName" SG_ 625 FCWSettingTeen "DAS_A5_PKT";
BA_ "FlexKomSigStartPos" SG_ 625 FCWSettingTeen 7;
BA_ "FlexKomSigStartValue" SG_ 625 FCWSettingTeen "000000FF000000FFh";
BA_ "GenSigCycleTime" SG_ 625 FCWSettingTeen 20;
BA_ "GenSigSNA" SG_ 625 FCWSettingTeen "0h";
BA_ "GenSigTimeout_CBC" SG_ 625 FCWSettingTeen 210;
BA_ "GenSigTimeout_IC" SG_ 625 FCWSettingTeen 210;
BA_ "GenSigTimeout_ORC" SG_ 625 FCWSettingTeen 70;
BA_ "RID" SG_ 625 FCWSettingTeen "2169";
BA_ "FlexKomComment" SG_ 625 FCWState "DAS_A5 Packet";
BA_ "FlexKomIsMotorola" SG_ 625 FCWState 1;
BA_ "FlexKomSID" SG_ 625 FCWState 2333;
BA_ "FlexKomSigLaenge" SG_ 625 FCWState 64;
BA_ "FlexKomSigName" SG_ 625 FCWState "DAS_A5_PKT";
BA_ "FlexKomSigStartPos" SG_ 625 FCWState 7;
BA_ "FlexKomSigStartValue" SG_ 625 FCWState "000000FF000000FFh";
BA_ "GenSigCycleTime" SG_ 625 FCWState 20;
BA_ "GenSigSNA" SG_ 625 FCWState "0h";
BA_ "GenSigTimeout_IC" SG_ 625 FCWState 210;
BA_ "GenSigTimeout_ORC" SG_ 625 FCWState 70;
BA_ "RID" SG_ 625 FCWState "2171";
BA_ "FlexKomComment" SG_ 625 MC_DAS_A5 "DAS_A5 Packet";
BA_ "FlexKomIsMotorola" SG_ 625 MC_DAS_A5 1;
BA_ "FlexKomSID" SG_ 625 MC_DAS_A5 2333;
BA_ "FlexKomSigLaenge" SG_ 625 MC_DAS_A5 64;
BA_ "FlexKomSigName" SG_ 625 MC_DAS_A5 "DAS_A5_PKT";
BA_ "FlexKomSigStartPos" SG_ 625 MC_DAS_A5 7;
BA_ "FlexKomSigStartValue" SG_ 625 MC_DAS_A5 "000000FF000000FFh";
BA_ "GenSigCycleTime" SG_ 625 MC_DAS_A5 20;
BA_ "GenSigSNA" SG_ 625 MC_DAS_A5 "0h";
BA_ "FlexKomComment" SG_ 625 SDS_Engaged_State "DAS_A5 Packet";
BA_ "FlexKomIsMotorola" SG_ 625 SDS_Engaged_State 1;
BA_ "FlexKomSID" SG_ 625 SDS_Engaged_State 2333;
BA_ "FlexKomSigLaenge" SG_ 625 SDS_Engaged_State 64;
BA_ "FlexKomSigName" SG_ 625 SDS_Engaged_State "DAS_A5_PKT";
BA_ "FlexKomSigStartPos" SG_ 625 SDS_Engaged_State 7;
BA_ "FlexKomSigStartValue" SG_ 625 SDS_Engaged_State "000000FF000000FFh";
BA_ "GenSigCycleTime" SG_ 625 SDS_Engaged_State 20;
BA_ "GenSigSNA" SG_ 625 SDS_Engaged_State "3h";
BA_ "GenSigTimeout_RHSC2" SG_ 625 SDS_Engaged_State 70;
BA_ "FlexKomComment" SG_ 625 WhlTrqActRq_DAS "DAS_A5 Packet";
BA_ "FlexKomIsMotorola" SG_ 625 WhlTrqActRq_DAS 1;
BA_ "FlexKomSID" SG_ 625 WhlTrqActRq_DAS 2333;
BA_ "FlexKomSigLaenge" SG_ 625 WhlTrqActRq_DAS 64;
BA_ "FlexKomSigName" SG_ 625 WhlTrqActRq_DAS "DAS_A5_PKT";
BA_ "FlexKomSigStartPos" SG_ 625 WhlTrqActRq_DAS 7;
BA_ "FlexKomSigStartValue" SG_ 625 WhlTrqActRq_DAS "000000FF000000FFh";
BA_ "GenSigCycleTime" SG_ 625 WhlTrqActRq_DAS 20;
BA_ "GenSigSNA" SG_ 625 WhlTrqActRq_DAS "0h";
BA_ "FlexKomComment" SG_ 625 WhlTrqRq_DAS "DAS_A5 Packet";
BA_ "FlexKomIsMotorola" SG_ 625 WhlTrqRq_DAS 1;
BA_ "FlexKomSID" SG_ 625 WhlTrqRq_DAS 2333;
BA_ "FlexKomSigLaenge" SG_ 625 WhlTrqRq_DAS 64;
BA_ "FlexKomSigName" SG_ 625 WhlTrqRq_DAS "DAS_A5_PKT";
BA_ "FlexKomSigStartPos" SG_ 625 WhlTrqRq_DAS 7;
BA_ "FlexKomSigStartValue" SG_ 625 WhlTrqRq_DAS "000000FF000000FFh";
BA_ "GenSigCycleTime" SG_ 625 WhlTrqRq_DAS 20;
BA_ "GenSigSNA" SG_ 625 WhlTrqRq_DAS "7FFFh";
BA_ "FlexKomComment" SG_ 2015 DG_RQ_GLOBAL "Diagnostic-Request";
BA_ "FlexKomIsMotorola" SG_ 2015 DG_RQ_GLOBAL 1;
BA_ "FlexKomSID" SG_ 2015 DG_RQ_GLOBAL 392;
BA_ "FlexKomSigLaenge" SG_ 2015 DG_RQ_GLOBAL 64;
BA_ "FlexKomSigName" SG_ 2015 DG_RQ_GLOBAL "DG_RQ_GLOBAL";
BA_ "FlexKomSigStartPos" SG_ 2015 DG_RQ_GLOBAL 7;
BA_ "FlexKomSigStartValue" SG_ 2015 DG_RQ_GLOBAL "0000000000000000h";
BA_ "GenSigSNA" SG_ 2015 DG_RQ_GLOBAL "0h";
BA_ "FlexKomComment" SG_ 1089 DG_RQ_GLOBAL_UDS "Diagnostic-Request";
BA_ "FlexKomIsMotorola" SG_ 1089 DG_RQ_GLOBAL_UDS 1;
BA_ "FlexKomSID" SG_ 1089 DG_RQ_GLOBAL_UDS 393;
BA_ "FlexKomSigLaenge" SG_ 1089 DG_RQ_GLOBAL_UDS 64;
BA_ "FlexKomSigName" SG_ 1089 DG_RQ_GLOBAL_UDS "DG_RQ_GLOBAL_UDS";
BA_ "FlexKomSigStartPos" SG_ 1089 DG_RQ_GLOBAL_UDS 7;
BA_ "FlexKomSigStartValue" SG_ 1089 DG_RQ_GLOBAL_UDS "0000000000000000h";
BA_ "GenSigSNA" SG_ 1089 DG_RQ_GLOBAL_UDS "0h";
BA_ "RID" SG_ 1089 DG_RQ_GLOBAL_UDS "2075";
BA_ "FlexKomComment" SG_ 860 DIST_TO_TURN "Navigation turn information packet";
BA_ "FlexKomIsMotorola" SG_ 860 DIST_TO_TURN 1;
BA_ "FlexKomSID" SG_ 860 DIST_TO_TURN 986;
BA_ "FlexKomSigLaenge" SG_ 860 DIST_TO_TURN 32;
BA_ "FlexKomSigName" SG_ 860 DIST_TO_TURN "TURN_INFO";
BA_ "FlexKomSigStartPos" SG_ 860 DIST_TO_TURN 7;
BA_ "FlexKomSigStartValue" SG_ 860 DIST_TO_TURN "00000000h";
BA_ "GenSigCycleTime" SG_ 860 DIST_TO_TURN 1000;
BA_ "GenSigSendType" SG_ 860 DIST_TO_TURN 5;
BA_ "GenSigSNA" SG_ 860 DIST_TO_TURN "FFFFh";
BA_ "GenSigTimeout_IC" SG_ 860 DIST_TO_TURN 10500;
BA_ "RID" SG_ 860 DIST_TO_TURN "1204";
BA_ "FlexKomComment" SG_ 860 NAVPrsnt "Navigation turn information packet";
BA_ "FlexKomIsMotorola" SG_ 860 NAVPrsnt 1;
BA_ "FlexKomSID" SG_ 860 NAVPrsnt 986;
BA_ "FlexKomSigLaenge" SG_ 860 NAVPrsnt 32;
BA_ "FlexKomSigName" SG_ 860 NAVPrsnt "TURN_INFO";
BA_ "FlexKomSigStartPos" SG_ 860 NAVPrsnt 7;
BA_ "FlexKomSigStartValue" SG_ 860 NAVPrsnt "00000000h";
BA_ "GenSigCycleTime" SG_ 860 NAVPrsnt 1000;
BA_ "GenSigSendType" SG_ 860 NAVPrsnt 5;
BA_ "GenSigSNA" SG_ 860 NAVPrsnt "0h";
BA_ "RID" SG_ 860 NAVPrsnt "1198";
BA_ "FlexKomComment" SG_ 860 NAV_ARROW "Navigation turn information packet";
BA_ "FlexKomIsMotorola" SG_ 860 NAV_ARROW 1;
BA_ "FlexKomSID" SG_ 860 NAV_ARROW 986;
BA_ "FlexKomSigLaenge" SG_ 860 NAV_ARROW 32;
BA_ "FlexKomSigName" SG_ 860 NAV_ARROW "TURN_INFO";
BA_ "FlexKomSigStartPos" SG_ 860 NAV_ARROW 7;
BA_ "FlexKomSigStartValue" SG_ 860 NAV_ARROW "00000000h";
BA_ "GenSigCycleTime" SG_ 860 NAV_ARROW 1000;
BA_ "GenSigSendType" SG_ 860 NAV_ARROW 5;
BA_ "GenSigSNA" SG_ 860 NAV_ARROW "0h";
BA_ "GenSigTimeout_IC" SG_ 860 NAV_ARROW 10500;
BA_ "RID" SG_ 860 NAV_ARROW "1033";
BA_ "FlexKomComment" SG_ 860 TURN_COMP "Navigation turn information packet";
BA_ "FlexKomIsMotorola" SG_ 860 TURN_COMP 1;
BA_ "FlexKomSID" SG_ 860 TURN_COMP 986;
BA_ "FlexKomSigLaenge" SG_ 860 TURN_COMP 32;
BA_ "FlexKomSigName" SG_ 860 TURN_COMP "TURN_INFO";
BA_ "FlexKomSigStartPos" SG_ 860 TURN_COMP 7;
BA_ "FlexKomSigStartValue" SG_ 860 TURN_COMP "00000000h";
BA_ "GenSigCycleTime" SG_ 860 TURN_COMP 1000;
BA_ "GenSigSendType" SG_ 860 TURN_COMP 5;
BA_ "GenSigSNA" SG_ 860 TURN_COMP "0h";
BA_ "GenSigTimeout_IC" SG_ 860 TURN_COMP 10500;
BA_ "RID" SG_ 860 TURN_COMP "1064";
BA_ "FlexKomComment" SG_ 860 T_BY_T_ON "Navigation turn information packet";
BA_ "FlexKomIsMotorola" SG_ 860 T_BY_T_ON 1;
BA_ "FlexKomSID" SG_ 860 T_BY_T_ON 986;
BA_ "FlexKomSigLaenge" SG_ 860 T_BY_T_ON 32;
BA_ "FlexKomSigName" SG_ 860 T_BY_T_ON "TURN_INFO";
BA_ "FlexKomSigStartPos" SG_ 860 T_BY_T_ON 7;
BA_ "FlexKomSigStartValue" SG_ 860 T_BY_T_ON "00000000h";
BA_ "GenSigCycleTime" SG_ 860 T_BY_T_ON 1000;
BA_ "GenSigSendType" SG_ 860 T_BY_T_ON 5;
BA_ "GenSigSNA" SG_ 860 T_BY_T_ON "0h";
BA_ "GenSigTimeout_IC" SG_ 860 T_BY_T_ON 10500;
BA_ "RID" SG_ 860 T_BY_T_ON "1194";
BA_ "FlexKomComment" SG_ 860 UNITS "Navigation turn information packet";
BA_ "FlexKomIsMotorola" SG_ 860 UNITS 1;
BA_ "FlexKomSID" SG_ 860 UNITS 986;
BA_ "FlexKomSigLaenge" SG_ 860 UNITS 32;
BA_ "FlexKomSigName" SG_ 860 UNITS "TURN_INFO";
BA_ "FlexKomSigStartPos" SG_ 860 UNITS 7;
BA_ "FlexKomSigStartValue" SG_ 860 UNITS "00000000h";
BA_ "GenSigCycleTime" SG_ 860 UNITS 1000;
BA_ "GenSigSendType" SG_ 860 UNITS 5;
BA_ "GenSigSNA" SG_ 860 UNITS "7h";
BA_ "GenSigTimeout_IC" SG_ 860 UNITS 10500;
BA_ "RID" SG_ 860 UNITS "1217";
BA_ "FlexKomComment" SG_ 1900 D_RQ_AHCP "Diagnostic-Request";
BA_ "FlexKomIsMotorola" SG_ 1900 D_RQ_AHCP 1;
BA_ "FlexKomSID" SG_ 1900 D_RQ_AHCP 2517;
BA_ "FlexKomSigLaenge" SG_ 1900 D_RQ_AHCP 64;
BA_ "FlexKomSigName" SG_ 1900 D_RQ_AHCP "D_RQ_AHCP";
BA_ "FlexKomSigStartPos" SG_ 1900 D_RQ_AHCP 7;
BA_ "FlexKomSigStartValue" SG_ 1900 D_RQ_AHCP "0000000000000000h";
BA_ "GenSigSendType" SG_ 1900 D_RQ_AHCP 1;
BA_ "GenSigSNA" SG_ 1900 D_RQ_AHCP "0h";
BA_ "FlexKomComment" SG_ 1898 D_RQ_APM "Diagnostic-Request";
BA_ "FlexKomIsMotorola" SG_ 1898 D_RQ_APM 1;
BA_ "FlexKomSID" SG_ 1898 D_RQ_APM 2124;
BA_ "FlexKomSigLaenge" SG_ 1898 D_RQ_APM 64;
BA_ "FlexKomSigName" SG_ 1898 D_RQ_APM "D_RQ_APM";
BA_ "FlexKomSigStartPos" SG_ 1898 D_RQ_APM 7;
BA_ "FlexKomSigStartValue" SG_ 1898 D_RQ_APM "0000000000000000h";
BA_ "GenSigSendType" SG_ 1898 D_RQ_APM 1;
BA_ "GenSigSNA" SG_ 1898 D_RQ_APM "0h";
BA_ "FlexKomComment" SG_ 2023 D_RQ_BPCM "Diagnostic-Request";
BA_ "FlexKomIsMotorola" SG_ 2023 D_RQ_BPCM 1;
BA_ "FlexKomSID" SG_ 2023 D_RQ_BPCM 2138;
BA_ "FlexKomSigLaenge" SG_ 2023 D_RQ_BPCM 64;
BA_ "FlexKomSigName" SG_ 2023 D_RQ_BPCM "D_RQ_BPCM";
BA_ "FlexKomSigStartPos" SG_ 2023 D_RQ_BPCM 7;
BA_ "FlexKomSigStartValue" SG_ 2023 D_RQ_BPCM "0000000000000000h";
BA_ "GenSigSendType" SG_ 2023 D_RQ_BPCM 1;
BA_ "GenSigSNA" SG_ 2023 D_RQ_BPCM "0h";
BA_ "FlexKomComment" SG_ 2020 D_RQ_BSMO "Diagnostic-Request";
BA_ "FlexKomIsMotorola" SG_ 2020 D_RQ_BSMO 1;
BA_ "FlexKomSID" SG_ 2020 D_RQ_BSMO 2284;
BA_ "FlexKomSigLaenge" SG_ 2020 D_RQ_BSMO 64;
BA_ "FlexKomSigName" SG_ 2020 D_RQ_BSMO "D_RQ_BSMO";
BA_ "FlexKomSigStartPos" SG_ 2020 D_RQ_BSMO 7;
BA_ "FlexKomSigStartValue" SG_ 2020 D_RQ_BSMO "0000000000000000h";
BA_ "GenSigSendType" SG_ 2020 D_RQ_BSMO 1;
BA_ "GenSigSNA" SG_ 2020 D_RQ_BSMO "0h";
BA_ "FlexKomComment" SG_ 1568 D_RQ_CBC "Diagnostic-Request";
BA_ "FlexKomIsMotorola" SG_ 1568 D_RQ_CBC 1;
BA_ "FlexKomSID" SG_ 1568 D_RQ_CBC 78;
BA_ "FlexKomSigLaenge" SG_ 1568 D_RQ_CBC 64;
BA_ "FlexKomSigName" SG_ 1568 D_RQ_CBC "D_RQ_CBC";
BA_ "FlexKomSigStartPos" SG_ 1568 D_RQ_CBC 7;
BA_ "FlexKomSigStartValue" SG_ 1568 D_RQ_CBC "0000000000000000h";
BA_ "GenSigSendType" SG_ 1568 D_RQ_CBC 1;
BA_ "GenSigSNA" SG_ 1568 D_RQ_CBC "0h";
BA_ "FlexKomComment" SG_ 1875 D_RQ_DASM "Diagnostic-Request";
BA_ "FlexKomIsMotorola" SG_ 1875 D_RQ_DASM 1;
BA_ "FlexKomSID" SG_ 1875 D_RQ_DASM 97;
BA_ "FlexKomSigLaenge" SG_ 1875 D_RQ_DASM 64;
BA_ "FlexKomSigName" SG_ 1875 D_RQ_DASM "D_RQ_DASM";
BA_ "FlexKomSigStartPos" SG_ 1875 D_RQ_DASM 7;
BA_ "FlexKomSigStartValue" SG_ 1875 D_RQ_DASM "0000000000000000h";
BA_ "GenSigSendType" SG_ 1875 D_RQ_DASM 1;
BA_ "GenSigSNA" SG_ 1875 D_RQ_DASM "0h";
BA_ "FlexKomComment" SG_ 1899 D_RQ_EAC "Diagnostic-Request";
BA_ "FlexKomIsMotorola" SG_ 1899 D_RQ_EAC 1;
BA_ "FlexKomSID" SG_ 1899 D_RQ_EAC 2126;
BA_ "FlexKomSigLaenge" SG_ 1899 D_RQ_EAC 64;
BA_ "FlexKomSigName" SG_ 1899 D_RQ_EAC "D_RQ_EAC";
BA_ "FlexKomSigStartPos" SG_ 1899 D_RQ_EAC 7;
BA_ "FlexKomSigStartValue" SG_ 1899 D_RQ_EAC "0000000000000000h";
BA_ "GenSigSendType" SG_ 1899 D_RQ_EAC 1;
BA_ "GenSigSNA" SG_ 1899 D_RQ_EAC "0h";
BA_ "FlexKomComment" SG_ 2019 D_RQ_EBCM "Diagnostic-Request";
BA_ "FlexKomIsMotorola" SG_ 2019 D_RQ_EBCM 1;
BA_ "FlexKomSID" SG_ 2019 D_RQ_EBCM 2128;
BA_ "FlexKomSigLaenge" SG_ 2019 D_RQ_EBCM 64;
BA_ "FlexKomSigName" SG_ 2019 D_RQ_EBCM "D_RQ_EBCM";
BA_ "FlexKomSigStartPos" SG_ 2019 D_RQ_EBCM 7;
BA_ "FlexKomSigStartValue" SG_ 2019 D_RQ_EBCM "0000000000000000h";
BA_ "GenSigSendType" SG_ 2019 D_RQ_EBCM 1;
BA_ "GenSigSNA" SG_ 2019 D_RQ_EBCM "0h";
BA_ "FlexKomComment" SG_ 2016 D_RQ_ECM "Diagnostic-Request";
BA_ "FlexKomIsMotorola" SG_ 2016 D_RQ_ECM 1;
BA_ "FlexKomSID" SG_ 2016 D_RQ_ECM 85;
BA_ "FlexKomSigLaenge" SG_ 2016 D_RQ_ECM 64;
BA_ "FlexKomSigName" SG_ 2016 D_RQ_ECM "D_RQ_ECM";
BA_ "FlexKomSigStartPos" SG_ 2016 D_RQ_ECM 7;
BA_ "FlexKomSigStartValue" SG_ 2016 D_RQ_ECM "0000000000000000h";
BA_ "GenSigSendType" SG_ 2016 D_RQ_ECM 1;
BA_ "GenSigSNA" SG_ 2016 D_RQ_ECM "0h";
BA_ "FlexKomComment" SG_ 1882 D_RQ_EPS "Diagnostic-Request";
BA_ "FlexKomIsMotorola" SG_ 1882 D_RQ_EPS 1;
BA_ "FlexKomSID" SG_ 1882 D_RQ_EPS 87;
BA_ "FlexKomSigLaenge" SG_ 1882 D_RQ_EPS 64;
BA_ "FlexKomSigName" SG_ 1882 D_RQ_EPS "D_RQ_EPS";
BA_ "FlexKomSigStartPos" SG_ 1882 D_RQ_EPS 7;
BA_ "FlexKomSigStartValue" SG_ 1882 D_RQ_EPS "0000000000000000h";
BA_ "GenSigSendType" SG_ 1882 D_RQ_EPS 1;
BA_ "GenSigSNA" SG_ 1882 D_RQ_EPS "0h";
BA_ "FlexKomComment" SG_ 1864 D_RQ_ESL "Diagnostic-Request";
BA_ "FlexKomIsMotorola" SG_ 1864 D_RQ_ESL 1;
BA_ "FlexKomSID" SG_ 1864 D_RQ_ESL 2339;
BA_ "FlexKomSigLaenge" SG_ 1864 D_RQ_ESL 64;
BA_ "FlexKomSigName" SG_ 1864 D_RQ_ESL "D_RQ_ESL";
BA_ "FlexKomSigStartPos" SG_ 1864 D_RQ_ESL 7;
BA_ "FlexKomSigStartValue" SG_ 1864 D_RQ_ESL "0000000000000000h";
BA_ "GenSigSendType" SG_ 1864 D_RQ_ESL 1;
BA_ "GenSigSNA" SG_ 1864 D_RQ_ESL "0h";
BA_ "FlexKomComment" SG_ 1865 D_RQ_ESM "Diagnostic-Request";
BA_ "FlexKomIsMotorola" SG_ 1865 D_RQ_ESM 1;
BA_ "FlexKomSID" SG_ 1865 D_RQ_ESM 90;
BA_ "FlexKomSigLaenge" SG_ 1865 D_RQ_ESM 64;
BA_ "FlexKomSigName" SG_ 1865 D_RQ_ESM "D_RQ_ESM";
BA_ "FlexKomSigStartPos" SG_ 1865 D_RQ_ESM 7;
BA_ "FlexKomSigStartValue" SG_ 1865 D_RQ_ESM "0000000000000000h";
BA_ "GenSigSendType" SG_ 1865 D_RQ_ESM 1;
BA_ "GenSigSNA" SG_ 1865 D_RQ_ESM "0h";
BA_ "RID" SG_ 1865 D_RQ_ESM "9607";
BA_ "FlexKomComment" SG_ 2018 D_RQ_HCP "Diagnostic-Request";
BA_ "FlexKomIsMotorola" SG_ 2018 D_RQ_HCP 1;
BA_ "FlexKomSID" SG_ 2018 D_RQ_HCP 2118;
BA_ "FlexKomSigLaenge" SG_ 2018 D_RQ_HCP 64;
BA_ "FlexKomSigName" SG_ 2018 D_RQ_HCP "D_RQ_HCP";
BA_ "FlexKomSigStartPos" SG_ 2018 D_RQ_HCP 7;
BA_ "FlexKomSigStartValue" SG_ 2018 D_RQ_HCP "0000000000000000h";
BA_ "GenSigSendType" SG_ 2018 D_RQ_HCP 1;
BA_ "GenSigSNA" SG_ 2018 D_RQ_HCP "0h";
BA_ "FlexKomComment" SG_ 1892 D_RQ_HaLF "Diagnostic-Request";
BA_ "FlexKomIsMotorola" SG_ 1892 D_RQ_HaLF 1;
BA_ "FlexKomSID" SG_ 1892 D_RQ_HaLF 1632;
BA_ "FlexKomSigLaenge" SG_ 1892 D_RQ_HaLF 64;
BA_ "FlexKomSigName" SG_ 1892 D_RQ_HaLF "D_RQ_HaLF";
BA_ "FlexKomSigStartPos" SG_ 1892 D_RQ_HaLF 7;
BA_ "FlexKomSigStartValue" SG_ 1892 D_RQ_HaLF "0000000000000000h";
BA_ "GenSigSendType" SG_ 1892 D_RQ_HaLF 1;
BA_ "GenSigSNA" SG_ 1892 D_RQ_HaLF "0h";
BA_ "FlexKomComment" SG_ 1858 D_RQ_IC "Diagnostic-Request";
BA_ "FlexKomIsMotorola" SG_ 1858 D_RQ_IC 1;
BA_ "FlexKomSID" SG_ 1858 D_RQ_IC 95;
BA_ "FlexKomSigLaenge" SG_ 1858 D_RQ_IC 64;
BA_ "FlexKomSigName" SG_ 1858 D_RQ_IC "D_RQ_IC";
BA_ "FlexKomSigStartPos" SG_ 1858 D_RQ_IC 7;
BA_ "FlexKomSigStartValue" SG_ 1858 D_RQ_IC "0000000000000000h";
BA_ "GenSigSendType" SG_ 1858 D_RQ_IC 1;
BA_ "GenSigSNA" SG_ 1858 D_RQ_IC "0h";
BA_ "FlexKomComment" SG_ 1902 D_RQ_OBCM "Diagnostic-Request";
BA_ "FlexKomIsMotorola" SG_ 1902 D_RQ_OBCM 1;
BA_ "FlexKomSID" SG_ 1902 D_RQ_OBCM 2136;
BA_ "FlexKomSigLaenge" SG_ 1902 D_RQ_OBCM 64;
BA_ "FlexKomSigName" SG_ 1902 D_RQ_OBCM "D_RQ_OBCM";
BA_ "FlexKomSigStartPos" SG_ 1902 D_RQ_OBCM 7;
BA_ "FlexKomSigStartValue" SG_ 1902 D_RQ_OBCM "0000000000000000h";
BA_ "GenSigSendType" SG_ 1902 D_RQ_OBCM 1;
BA_ "GenSigSNA" SG_ 1902 D_RQ_OBCM "0h";
BA_ "FlexKomComment" SG_ 1886 D_RQ_OCM "Diagnostic-Request";
BA_ "FlexKomIsMotorola" SG_ 1886 D_RQ_OCM 1;
BA_ "FlexKomSID" SG_ 1886 D_RQ_OCM 1536;
BA_ "FlexKomSigLaenge" SG_ 1886 D_RQ_OCM 64;
BA_ "FlexKomSigName" SG_ 1886 D_RQ_OCM "D_RQ_OCM";
BA_ "FlexKomSigStartPos" SG_ 1886 D_RQ_OCM 7;
BA_ "FlexKomSigStartValue" SG_ 1886 D_RQ_OCM "0000000000000000h";
BA_ "GenSigSendType" SG_ 1886 D_RQ_OCM 1;
BA_ "GenSigSNA" SG_ 1886 D_RQ_OCM "0h";
BA_ "FlexKomComment" SG_ 1860 D_RQ_ORC "Diagnostic-Request";
BA_ "FlexKomIsMotorola" SG_ 1860 D_RQ_ORC 1;
BA_ "FlexKomSID" SG_ 1860 D_RQ_ORC 101;
BA_ "FlexKomSigLaenge" SG_ 1860 D_RQ_ORC 64;
BA_ "FlexKomSigName" SG_ 1860 D_RQ_ORC "D_RQ_ORC";
BA_ "FlexKomSigStartPos" SG_ 1860 D_RQ_ORC 7;
BA_ "FlexKomSigStartValue" SG_ 1860 D_RQ_ORC "0000000000000000h";
BA_ "GenSigSendType" SG_ 1860 D_RQ_ORC 1;
BA_ "GenSigSNA" SG_ 1860 D_RQ_ORC "0h";
BA_ "FlexKomComment" SG_ 1890 D_RQ_PTS "Diagnostic-Request";
BA_ "FlexKomIsMotorola" SG_ 1890 D_RQ_PTS 1;
BA_ "FlexKomSID" SG_ 1890 D_RQ_PTS 109;
BA_ "FlexKomSigLaenge" SG_ 1890 D_RQ_PTS 64;
BA_ "FlexKomSigName" SG_ 1890 D_RQ_PTS "D_RQ_PTS";
BA_ "FlexKomSigStartPos" SG_ 1890 D_RQ_PTS 7;
BA_ "FlexKomSigStartValue" SG_ 1890 D_RQ_PTS "0000000000000000h";
BA_ "GenSigSendType" SG_ 1890 D_RQ_PTS 1;
BA_ "GenSigSNA" SG_ 1890 D_RQ_PTS "0h";
BA_ "FlexKomComment" SG_ 1856 D_RQ_RF_HUB "Diagnostic-Request";
BA_ "FlexKomIsMotorola" SG_ 1856 D_RQ_RF_HUB 1;
BA_ "FlexKomSID" SG_ 1856 D_RQ_RF_HUB 92;
BA_ "FlexKomSigLaenge" SG_ 1856 D_RQ_RF_HUB 64;
BA_ "FlexKomSigName" SG_ 1856 D_RQ_RF_HUB "D_RQ_RF_HUB";
BA_ "FlexKomSigStartPos" SG_ 1856 D_RQ_RF_HUB 7;
BA_ "FlexKomSigStartValue" SG_ 1856 D_RQ_RF_HUB "0000000000000000h";
BA_ "GenSigSendType" SG_ 1856 D_RQ_RF_HUB 1;
BA_ "GenSigSNA" SG_ 1856 D_RQ_RF_HUB "0h";
BA_ "FlexKomComment" SG_ 1891 D_RQ_SCCM "Diagnostic-Request";
BA_ "FlexKomIsMotorola" SG_ 1891 D_RQ_SCCM 1;
BA_ "FlexKomSID" SG_ 1891 D_RQ_SCCM 113;
BA_ "FlexKomSigLaenge" SG_ 1891 D_RQ_SCCM 64;
BA_ "FlexKomSigName" SG_ 1891 D_RQ_SCCM "D_RQ_SCCM";
BA_ "FlexKomSigStartPos" SG_ 1891 D_RQ_SCCM 7;
BA_ "FlexKomSigStartValue" SG_ 1891 D_RQ_SCCM "0000000000000000h";
BA_ "GenSigSendType" SG_ 1891 D_RQ_SCCM 1;
BA_ "GenSigSNA" SG_ 1891 D_RQ_SCCM "0h";
BA_ "FlexKomComment" SG_ 1150 D_RQ_SGW "Diagnostic-Request";
BA_ "FlexKomIsMotorola" SG_ 1150 D_RQ_SGW 1;
BA_ "FlexKomSID" SG_ 1150 D_RQ_SGW 2610;
BA_ "FlexKomSigLaenge" SG_ 1150 D_RQ_SGW 64;
BA_ "FlexKomSigName" SG_ 1150 D_RQ_SGW "D_RQ_SGW";
BA_ "FlexKomSigStartPos" SG_ 1150 D_RQ_SGW 7;
BA_ "FlexKomSigStartValue" SG_ 1150 D_RQ_SGW "0000000000000000h";
BA_ "GenSigSendType" SG_ 1150 D_RQ_SGW 1;
BA_ "GenSigSNA" SG_ 1150 D_RQ_SGW "0h";
BA_ "FlexKomComment" SG_ 1260 D_RS_AHCP "Diagnostic-Response";
BA_ "FlexKomIsMotorola" SG_ 1260 D_RS_AHCP 1;
BA_ "FlexKomSID" SG_ 1260 D_RS_AHCP 2518;
BA_ "FlexKomSigLaenge" SG_ 1260 D_RS_AHCP 64;
BA_ "FlexKomSigName" SG_ 1260 D_RS_AHCP "D_RS_AHCP";
BA_ "FlexKomSigStartPos" SG_ 1260 D_RS_AHCP 7;
BA_ "FlexKomSigStartValue" SG_ 1260 D_RS_AHCP "0000000000000000h";
BA_ "GenSigSendType" SG_ 1260 D_RS_AHCP 1;
BA_ "GenSigSNA" SG_ 1260 D_RS_AHCP "0h";
BA_ "FlexKomComment" SG_ 1258 D_RS_APM "Diagnostic-Response";
BA_ "FlexKomIsMotorola" SG_ 1258 D_RS_APM 1;
BA_ "FlexKomSID" SG_ 1258 D_RS_APM 2125;
BA_ "FlexKomSigLaenge" SG_ 1258 D_RS_APM 64;
BA_ "FlexKomSigName" SG_ 1258 D_RS_APM "D_RS_APM";
BA_ "FlexKomSigStartPos" SG_ 1258 D_RS_APM 7;
BA_ "FlexKomSigStartValue" SG_ 1258 D_RS_APM "0000000000000000h";
BA_ "GenSigSendType" SG_ 1258 D_RS_APM 1;
BA_ "GenSigSNA" SG_ 1258 D_RS_APM "0h";
BA_ "FlexKomComment" SG_ 2031 D_RS_BPCM "Diagnostic-Response";
BA_ "FlexKomIsMotorola" SG_ 2031 D_RS_BPCM 1;
BA_ "FlexKomSID" SG_ 2031 D_RS_BPCM 2139;
BA_ "FlexKomSigLaenge" SG_ 2031 D_RS_BPCM 64;
BA_ "FlexKomSigName" SG_ 2031 D_RS_BPCM "D_RS_BPCM";
BA_ "FlexKomSigStartPos" SG_ 2031 D_RS_BPCM 7;
BA_ "FlexKomSigStartValue" SG_ 2031 D_RS_BPCM "0000000000000000h";
BA_ "GenSigSendType" SG_ 2031 D_RS_BPCM 1;
BA_ "GenSigSNA" SG_ 2031 D_RS_BPCM "0h";
BA_ "FlexKomComment" SG_ 2028 D_RS_BSMO "Diagnostic-Response";
BA_ "FlexKomIsMotorola" SG_ 2028 D_RS_BSMO 1;
BA_ "FlexKomSID" SG_ 2028 D_RS_BSMO 2281;
BA_ "FlexKomSigLaenge" SG_ 2028 D_RS_BSMO 64;
BA_ "FlexKomSigName" SG_ 2028 D_RS_BSMO "D_RS_BSMO";
BA_ "FlexKomSigStartPos" SG_ 2028 D_RS_BSMO 7;
BA_ "FlexKomSigStartValue" SG_ 2028 D_RS_BSMO "0000000000000000h";
BA_ "GenSigSendType" SG_ 2028 D_RS_BSMO 1;
BA_ "GenSigSNA" SG_ 2028 D_RS_BSMO "0h";
BA_ "FlexKomComment" SG_ 1284 D_RS_CBC "Diagnostic-Response";
BA_ "FlexKomIsMotorola" SG_ 1284 D_RS_CBC 1;
BA_ "FlexKomSID" SG_ 1284 D_RS_CBC 132;
BA_ "FlexKomSigLaenge" SG_ 1284 D_RS_CBC 64;
BA_ "FlexKomSigName" SG_ 1284 D_RS_CBC "D_RS_CBC";
BA_ "FlexKomSigStartPos" SG_ 1284 D_RS_CBC 7;
BA_ "FlexKomSigStartValue" SG_ 1284 D_RS_CBC "0000000000000000h";
BA_ "GenSigSendType" SG_ 1284 D_RS_CBC 1;
BA_ "GenSigSNA" SG_ 1284 D_RS_CBC "0h";
BA_ "FlexKomComment" SG_ 1235 D_RS_DASM "Diagnostic-Response";
BA_ "FlexKomIsMotorola" SG_ 1235 D_RS_DASM 1;
BA_ "FlexKomSID" SG_ 1235 D_RS_DASM 149;
BA_ "FlexKomSigLaenge" SG_ 1235 D_RS_DASM 64;
BA_ "FlexKomSigName" SG_ 1235 D_RS_DASM "D_RS_DASM";
BA_ "FlexKomSigStartPos" SG_ 1235 D_RS_DASM 7;
BA_ "FlexKomSigStartValue" SG_ 1235 D_RS_DASM "0000000000000000h";
BA_ "GenSigSendType" SG_ 1235 D_RS_DASM 1;
BA_ "GenSigSNA" SG_ 1235 D_RS_DASM "0h";
BA_ "FlexKomComment" SG_ 1259 D_RS_EAC "Diagnostic-Response";
BA_ "FlexKomIsMotorola" SG_ 1259 D_RS_EAC 1;
BA_ "FlexKomSID" SG_ 1259 D_RS_EAC 2127;
BA_ "FlexKomSigLaenge" SG_ 1259 D_RS_EAC 64;
BA_ "FlexKomSigName" SG_ 1259 D_RS_EAC "D_RS_EAC";
BA_ "FlexKomSigStartPos" SG_ 1259 D_RS_EAC 7;
BA_ "FlexKomSigStartValue" SG_ 1259 D_RS_EAC "0000000000000000h";
BA_ "GenSigSendType" SG_ 1259 D_RS_EAC 1;
BA_ "GenSigSNA" SG_ 1259 D_RS_EAC "0h";
BA_ "FlexKomComment" SG_ 2027 D_RS_EBCM "Diagnostic-Response";
BA_ "FlexKomIsMotorola" SG_ 2027 D_RS_EBCM 1;
BA_ "FlexKomSID" SG_ 2027 D_RS_EBCM 2129;
BA_ "FlexKomSigLaenge" SG_ 2027 D_RS_EBCM 64;
BA_ "FlexKomSigName" SG_ 2027 D_RS_EBCM "D_RS_EBCM";
BA_ "FlexKomSigStartPos" SG_ 2027 D_RS_EBCM 7;
BA_ "FlexKomSigStartValue" SG_ 2027 D_RS_EBCM "0000000000000000h";
BA_ "GenSigSendType" SG_ 2027 D_RS_EBCM 1;
BA_ "GenSigSNA" SG_ 2027 D_RS_EBCM "0h";
BA_ "FlexKomComment" SG_ 2024 D_RS_ECM "Diagnostic-Response";
BA_ "FlexKomIsMotorola" SG_ 2024 D_RS_ECM 1;
BA_ "FlexKomSID" SG_ 2024 D_RS_ECM 139;
BA_ "FlexKomSigLaenge" SG_ 2024 D_RS_ECM 64;
BA_ "FlexKomSigName" SG_ 2024 D_RS_ECM "D_RS_ECM";
BA_ "FlexKomSigStartPos" SG_ 2024 D_RS_ECM 7;
BA_ "FlexKomSigStartValue" SG_ 2024 D_RS_ECM "0000000000000000h";
BA_ "GenSigSendType" SG_ 2024 D_RS_ECM 1;
BA_ "GenSigSNA" SG_ 2024 D_RS_ECM "0h";
BA_ "FlexKomComment" SG_ 1242 D_RS_EPS "Diagnostic-Response";
BA_ "FlexKomIsMotorola" SG_ 1242 D_RS_EPS 1;
BA_ "FlexKomSID" SG_ 1242 D_RS_EPS 141;
BA_ "FlexKomSigLaenge" SG_ 1242 D_RS_EPS 64;
BA_ "FlexKomSigName" SG_ 1242 D_RS_EPS "D_RS_EPS";
BA_ "FlexKomSigStartPos" SG_ 1242 D_RS_EPS 7;
BA_ "FlexKomSigStartValue" SG_ 1242 D_RS_EPS "0000000000000000h";
BA_ "GenSigSendType" SG_ 1242 D_RS_EPS 1;
BA_ "GenSigSNA" SG_ 1242 D_RS_EPS "0h";
BA_ "FlexKomComment" SG_ 1224 D_RS_ESL "Diagnostic-Response";
BA_ "FlexKomIsMotorola" SG_ 1224 D_RS_ESL 1;
BA_ "FlexKomSID" SG_ 1224 D_RS_ESL 2340;
BA_ "FlexKomSigLaenge" SG_ 1224 D_RS_ESL 64;
BA_ "FlexKomSigName" SG_ 1224 D_RS_ESL "D_RS_ESL";
BA_ "FlexKomSigStartPos" SG_ 1224 D_RS_ESL 7;
BA_ "FlexKomSigStartValue" SG_ 1224 D_RS_ESL "0000000000000000h";
BA_ "GenSigSendType" SG_ 1224 D_RS_ESL 1;
BA_ "GenSigSNA" SG_ 1224 D_RS_ESL "0h";
BA_ "FlexKomComment" SG_ 1225 D_RS_ESM "Diagnostic-Response";
BA_ "FlexKomIsMotorola" SG_ 1225 D_RS_ESM 1;
BA_ "FlexKomSID" SG_ 1225 D_RS_ESM 142;
BA_ "FlexKomSigLaenge" SG_ 1225 D_RS_ESM 64;
BA_ "FlexKomSigName" SG_ 1225 D_RS_ESM "D_RS_ESM";
BA_ "FlexKomSigStartPos" SG_ 1225 D_RS_ESM 7;
BA_ "FlexKomSigStartValue" SG_ 1225 D_RS_ESM "0000000000000000h";
BA_ "GenSigSendType" SG_ 1225 D_RS_ESM 1;
BA_ "GenSigSNA" SG_ 1225 D_RS_ESM "0h";
BA_ "RID" SG_ 1225 D_RS_ESM "9608";
BA_ "FlexKomComment" SG_ 2026 D_RS_HCP "Diagnostic-Response";
BA_ "FlexKomIsMotorola" SG_ 2026 D_RS_HCP 1;
BA_ "FlexKomSID" SG_ 2026 D_RS_HCP 2119;
BA_ "FlexKomSigLaenge" SG_ 2026 D_RS_HCP 64;
BA_ "FlexKomSigName" SG_ 2026 D_RS_HCP "D_RS_HCP";
BA_ "FlexKomSigStartPos" SG_ 2026 D_RS_HCP 7;
BA_ "FlexKomSigStartValue" SG_ 2026 D_RS_HCP "0000000000000000h";
BA_ "GenSigSendType" SG_ 2026 D_RS_HCP 1;
BA_ "GenSigSNA" SG_ 2026 D_RS_HCP "0h";
BA_ "FlexKomComment" SG_ 1252 D_RS_HaLF "Diagnostic-Response";
BA_ "FlexKomIsMotorola" SG_ 1252 D_RS_HaLF 1;
BA_ "FlexKomSID" SG_ 1252 D_RS_HaLF 1633;
BA_ "FlexKomSigLaenge" SG_ 1252 D_RS_HaLF 64;
BA_ "FlexKomSigName" SG_ 1252 D_RS_HaLF "D_RS_HaLF";
BA_ "FlexKomSigStartPos" SG_ 1252 D_RS_HaLF 7;
BA_ "FlexKomSigStartValue" SG_ 1252 D_RS_HaLF "0000000000000000h";
BA_ "GenSigSendType" SG_ 1252 D_RS_HaLF 1;
BA_ "GenSigSNA" SG_ 1252 D_RS_HaLF "0h";
BA_ "FlexKomComment" SG_ 1218 D_RS_IC "Diagnostic-Response";
BA_ "FlexKomIsMotorola" SG_ 1218 D_RS_IC 1;
BA_ "FlexKomSID" SG_ 1218 D_RS_IC 147;
BA_ "FlexKomSigLaenge" SG_ 1218 D_RS_IC 64;
BA_ "FlexKomSigName" SG_ 1218 D_RS_IC "D_RS_IC";
BA_ "FlexKomSigStartPos" SG_ 1218 D_RS_IC 7;
BA_ "FlexKomSigStartValue" SG_ 1218 D_RS_IC "0000000000000000h";
BA_ "GenSigSendType" SG_ 1218 D_RS_IC 1;
BA_ "GenSigSNA" SG_ 1218 D_RS_IC "0h";
BA_ "FlexKomComment" SG_ 1262 D_RS_OBCM "Diagnostic-Response";
BA_ "FlexKomIsMotorola" SG_ 1262 D_RS_OBCM 1;
BA_ "FlexKomSID" SG_ 1262 D_RS_OBCM 2137;
BA_ "FlexKomSigLaenge" SG_ 1262 D_RS_OBCM 64;
BA_ "FlexKomSigName" SG_ 1262 D_RS_OBCM "D_RS_OBCM";
BA_ "FlexKomSigStartPos" SG_ 1262 D_RS_OBCM 7;
BA_ "FlexKomSigStartValue" SG_ 1262 D_RS_OBCM "0000000000000000h";
BA_ "GenSigSendType" SG_ 1262 D_RS_OBCM 1;
BA_ "GenSigSNA" SG_ 1262 D_RS_OBCM "0h";
BA_ "FlexKomComment" SG_ 1246 D_RS_OCM "Diagnostic-Response";
BA_ "FlexKomIsMotorola" SG_ 1246 D_RS_OCM 1;
BA_ "FlexKomSID" SG_ 1246 D_RS_OCM 1537;
BA_ "FlexKomSigLaenge" SG_ 1246 D_RS_OCM 64;
BA_ "FlexKomSigName" SG_ 1246 D_RS_OCM "D_RS_OCM";
BA_ "FlexKomSigStartPos" SG_ 1246 D_RS_OCM 7;
BA_ "FlexKomSigStartValue" SG_ 1246 D_RS_OCM "0000000000000000h";
BA_ "GenSigSendType" SG_ 1246 D_RS_OCM 1;
BA_ "GenSigSNA" SG_ 1246 D_RS_OCM "0h";
BA_ "FlexKomComment" SG_ 1220 D_RS_ORC "Diagnostic-Response";
BA_ "FlexKomIsMotorola" SG_ 1220 D_RS_ORC 1;
BA_ "FlexKomSID" SG_ 1220 D_RS_ORC 153;
BA_ "FlexKomSigLaenge" SG_ 1220 D_RS_ORC 64;
BA_ "FlexKomSigName" SG_ 1220 D_RS_ORC "D_RS_ORC";
BA_ "FlexKomSigStartPos" SG_ 1220 D_RS_ORC 7;
BA_ "FlexKomSigStartValue" SG_ 1220 D_RS_ORC "0000000000000000h";
BA_ "GenSigSendType" SG_ 1220 D_RS_ORC 1;
BA_ "GenSigSNA" SG_ 1220 D_RS_ORC "0h";
BA_ "FlexKomComment" SG_ 1250 D_RS_PTS "Diagnostic-Response";
BA_ "FlexKomIsMotorola" SG_ 1250 D_RS_PTS 1;
BA_ "FlexKomSID" SG_ 1250 D_RS_PTS 161;
BA_ "FlexKomSigLaenge" SG_ 1250 D_RS_PTS 64;
BA_ "FlexKomSigName" SG_ 1250 D_RS_PTS "D_RS_PTS";
BA_ "FlexKomSigStartPos" SG_ 1250 D_RS_PTS 7;
BA_ "FlexKomSigStartValue" SG_ 1250 D_RS_PTS "0000000000000000h";
BA_ "GenSigSendType" SG_ 1250 D_RS_PTS 1;
BA_ "GenSigSNA" SG_ 1250 D_RS_PTS "0h";
BA_ "FlexKomComment" SG_ 1216 D_RS_RF_HUB "Diagnostic-Response";
BA_ "FlexKomIsMotorola" SG_ 1216 D_RS_RF_HUB 1;
BA_ "FlexKomSID" SG_ 1216 D_RS_RF_HUB 144;
BA_ "FlexKomSigLaenge" SG_ 1216 D_RS_RF_HUB 64;
BA_ "FlexKomSigName" SG_ 1216 D_RS_RF_HUB "D_RS_RF_HUB";
BA_ "FlexKomSigStartPos" SG_ 1216 D_RS_RF_HUB 7;
BA_ "FlexKomSigStartValue" SG_ 1216 D_RS_RF_HUB "0000000000000000h";
BA_ "GenSigSendType" SG_ 1216 D_RS_RF_HUB 1;
BA_ "GenSigSNA" SG_ 1216 D_RS_RF_HUB "0h";
BA_ "FlexKomComment" SG_ 1251 D_RS_SCCM "Diagnostic-Response";
BA_ "FlexKomIsMotorola" SG_ 1251 D_RS_SCCM 1;
BA_ "FlexKomSID" SG_ 1251 D_RS_SCCM 165;
BA_ "FlexKomSigLaenge" SG_ 1251 D_RS_SCCM 64;
BA_ "FlexKomSigName" SG_ 1251 D_RS_SCCM "D_RS_SCCM";
BA_ "FlexKomSigStartPos" SG_ 1251 D_RS_SCCM 7;
BA_ "FlexKomSigStartValue" SG_ 1251 D_RS_SCCM "0000000000000000h";
BA_ "GenSigSendType" SG_ 1251 D_RS_SCCM 1;
BA_ "GenSigSNA" SG_ 1251 D_RS_SCCM "0h";
BA_ "FlexKomComment" SG_ 1151 D_RS_SGW "Diagnostic-Response";
BA_ "FlexKomIsMotorola" SG_ 1151 D_RS_SGW 1;
BA_ "FlexKomSID" SG_ 1151 D_RS_SGW 2611;
BA_ "FlexKomSigLaenge" SG_ 1151 D_RS_SGW 64;
BA_ "FlexKomSigName" SG_ 1151 D_RS_SGW "D_RS_SGW";
BA_ "FlexKomSigStartPos" SG_ 1151 D_RS_SGW 7;
BA_ "FlexKomSigStartValue" SG_ 1151 D_RS_SGW "0000000000000000h";
BA_ "GenSigSendType" SG_ 1151 D_RS_SGW 1;
BA_ "GenSigSNA" SG_ 1151 D_RS_SGW "0h";
BA_ "FlexKomComment" SG_ 653 BrakePedalApplied "Message EBCM_C1 packet";
BA_ "FlexKomIsMotorola" SG_ 653 BrakePedalApplied 1;
BA_ "FlexKomSID" SG_ 653 BrakePedalApplied 2377;
BA_ "FlexKomSigLaenge" SG_ 653 BrakePedalApplied 64;
BA_ "FlexKomSigName" SG_ 653 BrakePedalApplied "EBCM_C1_Pkt";
BA_ "FlexKomSigStartPos" SG_ 653 BrakePedalApplied 7;
BA_ "FlexKomSigStartValue" SG_ 653 BrakePedalApplied "0000F003FFFE00FFh";
BA_ "GenSigCycleTime" SG_ 653 BrakePedalApplied 20;
BA_ "GenSigSNA" SG_ 653 BrakePedalApplied "0h";
BA_ "FlexKomComment" SG_ 653 BrakePedalAppliedV "Message EBCM_C1 packet";
BA_ "FlexKomIsMotorola" SG_ 653 BrakePedalAppliedV 1;
BA_ "FlexKomSID" SG_ 653 BrakePedalAppliedV 2377;
BA_ "FlexKomSigLaenge" SG_ 653 BrakePedalAppliedV 64;
BA_ "FlexKomSigName" SG_ 653 BrakePedalAppliedV "EBCM_C1_Pkt";
BA_ "FlexKomSigStartPos" SG_ 653 BrakePedalAppliedV 7;
BA_ "FlexKomSigStartValue" SG_ 653 BrakePedalAppliedV "0000F003FFFE00FFh";
BA_ "GenSigCycleTime" SG_ 653 BrakePedalAppliedV 20;
BA_ "GenSigSNA" SG_ 653 BrakePedalAppliedV "0h";
BA_ "FlexKomComment" SG_ 653 BrakePedalTravelSensor "Message EBCM_C1 packet";
BA_ "FlexKomIsMotorola" SG_ 653 BrakePedalTravelSensor 1;
BA_ "FlexKomSID" SG_ 653 BrakePedalTravelSensor 2377;
BA_ "FlexKomSigLaenge" SG_ 653 BrakePedalTravelSensor 64;
BA_ "FlexKomSigName" SG_ 653 BrakePedalTravelSensor "EBCM_C1_Pkt";
BA_ "FlexKomSigStartPos" SG_ 653 BrakePedalTravelSensor 7;
BA_ "FlexKomSigStartValue" SG_ 653 BrakePedalTravelSensor "0000F003FFFE00FFh";
BA_ "GenSigCycleTime" SG_ 653 BrakePedalTravelSensor 20;
BA_ "GenSigSNA" SG_ 653 BrakePedalTravelSensor "FFh";
BA_ "FlexKomComment" SG_ 653 BrakePedalTravelSensorV "Message EBCM_C1 packet";
BA_ "FlexKomIsMotorola" SG_ 653 BrakePedalTravelSensorV 1;
BA_ "FlexKomSID" SG_ 653 BrakePedalTravelSensorV 2377;
BA_ "FlexKomSigLaenge" SG_ 653 BrakePedalTravelSensorV 64;
BA_ "FlexKomSigName" SG_ 653 BrakePedalTravelSensorV "EBCM_C1_Pkt";
BA_ "FlexKomSigStartPos" SG_ 653 BrakePedalTravelSensorV 7;
BA_ "FlexKomSigStartValue" SG_ 653 BrakePedalTravelSensorV "0000F003FFFE00FFh";
BA_ "GenSigCycleTime" SG_ 653 BrakePedalTravelSensorV 20;
BA_ "GenSigSNA" SG_ 653 BrakePedalTravelSensorV "0h";
BA_ "FlexKomComment" SG_ 653 BrakeSysStateSec "Message EBCM_C1 packet";
BA_ "FlexKomIsMotorola" SG_ 653 BrakeSysStateSec 1;
BA_ "FlexKomSID" SG_ 653 BrakeSysStateSec 2377;
BA_ "FlexKomSigLaenge" SG_ 653 BrakeSysStateSec 64;
BA_ "FlexKomSigName" SG_ 653 BrakeSysStateSec "EBCM_C1_Pkt";
BA_ "FlexKomSigStartPos" SG_ 653 BrakeSysStateSec 7;
BA_ "FlexKomSigStartValue" SG_ 653 BrakeSysStateSec "0000F003FFFE00FFh";
BA_ "GenSigCycleTime" SG_ 653 BrakeSysStateSec 20;
BA_ "GenSigSNA" SG_ 653 BrakeSysStateSec "7h";
BA_ "GenSigTimeout_RHSC2" SG_ 653 BrakeSysStateSec 70;
BA_ "FlexKomComment" SG_ 653 BrkPdl_Flt_2 "Message EBCM_C1 packet";
BA_ "FlexKomIsMotorola" SG_ 653 BrkPdl_Flt_2 1;
BA_ "FlexKomSID" SG_ 653 BrkPdl_Flt_2 2377;
BA_ "FlexKomSigLaenge" SG_ 653 BrkPdl_Flt_2 64;
BA_ "FlexKomSigName" SG_ 653 BrkPdl_Flt_2 "EBCM_C1_Pkt";
BA_ "FlexKomSigStartPos" SG_ 653 BrkPdl_Flt_2 7;
BA_ "FlexKomSigStartValue" SG_ 653 BrkPdl_Flt_2 "0000F003FFFE00FFh";
BA_ "GenSigCycleTime" SG_ 653 BrkPdl_Flt_2 20;
BA_ "GenSigSNA" SG_ 653 BrkPdl_Flt_2 "0h";
BA_ "GenSigTimeout_RHSC2" SG_ 653 BrkPdl_Flt_2 70;
BA_ "FlexKomComment" SG_ 653 BrkPdl_Stat_2 "Message EBCM_C1 packet";
BA_ "FlexKomIsMotorola" SG_ 653 BrkPdl_Stat_2 1;
BA_ "FlexKomSID" SG_ 653 BrkPdl_Stat_2 2377;
BA_ "FlexKomSigLaenge" SG_ 653 BrkPdl_Stat_2 64;
BA_ "FlexKomSigName" SG_ 653 BrkPdl_Stat_2 "EBCM_C1_Pkt";
BA_ "FlexKomSigStartPos" SG_ 653 BrkPdl_Stat_2 7;
BA_ "FlexKomSigStartValue" SG_ 653 BrkPdl_Stat_2 "0000F003FFFE00FFh";
BA_ "GenSigCycleTime" SG_ 653 BrkPdl_Stat_2 20;
BA_ "GenSigSNA" SG_ 653 BrkPdl_Stat_2 "3h";
BA_ "GenSigTimeout_RHSC2" SG_ 653 BrkPdl_Stat_2 70;
BA_ "FlexKomComment" SG_ 653 Brk_Stat_2 "Message EBCM_C1 packet";
BA_ "FlexKomIsMotorola" SG_ 653 Brk_Stat_2 1;
BA_ "FlexKomSID" SG_ 653 Brk_Stat_2 2377;
BA_ "FlexKomSigLaenge" SG_ 653 Brk_Stat_2 64;
BA_ "FlexKomSigName" SG_ 653 Brk_Stat_2 "EBCM_C1_Pkt";
BA_ "FlexKomSigStartPos" SG_ 653 Brk_Stat_2 7;
BA_ "FlexKomSigStartValue" SG_ 653 Brk_Stat_2 "0000F003FFFE00FFh";
BA_ "GenSigCycleTime" SG_ 653 Brk_Stat_2 20;
BA_ "GenSigSNA" SG_ 653 Brk_Stat_2 "3h";
BA_ "GenSigTimeout_RHSC2" SG_ 653 Brk_Stat_2 70;
BA_ "FlexKomComment" SG_ 653 CRC_EBCM_C1 "Message EBCM_C1 packet";
BA_ "FlexKomIsMotorola" SG_ 653 CRC_EBCM_C1 1;
BA_ "FlexKomSID" SG_ 653 CRC_EBCM_C1 2377;
BA_ "FlexKomSigLaenge" SG_ 653 CRC_EBCM_C1 64;
BA_ "FlexKomSigName" SG_ 653 CRC_EBCM_C1 "EBCM_C1_Pkt";
BA_ "FlexKomSigStartPos" SG_ 653 CRC_EBCM_C1 7;
BA_ "FlexKomSigStartValue" SG_ 653 CRC_EBCM_C1 "0000F003FFFE00FFh";
BA_ "GenSigCycleTime" SG_ 653 CRC_EBCM_C1 20;
BA_ "GenSigSNA" SG_ 653 CRC_EBCM_C1 "FFh";
BA_ "GenSigStartValue" SG_ 653 CRC_EBCM_C1 255;
BA_ "GenSigTimeout_RHSC2" SG_ 653 CRC_EBCM_C1 70;
BA_ "FlexKomComment" SG_ 653 DAS_RqActv "Message EBCM_C1 packet";
BA_ "FlexKomIsMotorola" SG_ 653 DAS_RqActv 1;
BA_ "FlexKomSID" SG_ 653 DAS_RqActv 2377;
BA_ "FlexKomSigLaenge" SG_ 653 DAS_RqActv 64;
BA_ "FlexKomSigName" SG_ 653 DAS_RqActv "EBCM_C1_Pkt";
BA_ "FlexKomSigStartPos" SG_ 653 DAS_RqActv 7;
BA_ "FlexKomSigStartValue" SG_ 653 DAS_RqActv "0000F003FFFE00FFh";
BA_ "GenSigCycleTime" SG_ 653 DAS_RqActv 20;
BA_ "GenSigSNA" SG_ 653 DAS_RqActv "7h";
BA_ "GenSigTimeout_RHSC2" SG_ 653 DAS_RqActv 70;
BA_ "FlexKomComment" SG_ 653 DriverBrakingTrue_EBCM "Message EBCM_C1 packet";
BA_ "FlexKomIsMotorola" SG_ 653 DriverBrakingTrue_EBCM 1;
BA_ "FlexKomSID" SG_ 653 DriverBrakingTrue_EBCM 2377;
BA_ "FlexKomSigLaenge" SG_ 653 DriverBrakingTrue_EBCM 64;
BA_ "FlexKomSigName" SG_ 653 DriverBrakingTrue_EBCM "EBCM_C1_Pkt";
BA_ "FlexKomSigStartPos" SG_ 653 DriverBrakingTrue_EBCM 7;
BA_ "FlexKomSigStartValue" SG_ 653 DriverBrakingTrue_EBCM "0000F003FFFE00FFh";
BA_ "GenSigCycleTime" SG_ 653 DriverBrakingTrue_EBCM 20;
BA_ "GenSigSNA" SG_ 653 DriverBrakingTrue_EBCM "0h";
BA_ "GenSigTimeout_RHSC2" SG_ 653 DriverBrakingTrue_EBCM 70;
BA_ "FlexKomComment" SG_ 653 EBCMSysEmsMlfAtv "Message EBCM_C1 packet";
BA_ "FlexKomIsMotorola" SG_ 653 EBCMSysEmsMlfAtv 1;
BA_ "FlexKomSID" SG_ 653 EBCMSysEmsMlfAtv 2377;
BA_ "FlexKomSigLaenge" SG_ 653 EBCMSysEmsMlfAtv 64;
BA_ "FlexKomSigName" SG_ 653 EBCMSysEmsMlfAtv "EBCM_C1_Pkt";
BA_ "FlexKomSigStartPos" SG_ 653 EBCMSysEmsMlfAtv 7;
BA_ "FlexKomSigStartValue" SG_ 653 EBCMSysEmsMlfAtv "0000F003FFFE00FFh";
BA_ "GenSigCycleTime" SG_ 653 EBCMSysEmsMlfAtv 20;
BA_ "GenSigSNA" SG_ 653 EBCMSysEmsMlfAtv "0h";
BA_ "FlexKomComment" SG_ 653 EBCM_BrakeState "Message EBCM_C1 packet";
BA_ "FlexKomIsMotorola" SG_ 653 EBCM_BrakeState 1;
BA_ "FlexKomSID" SG_ 653 EBCM_BrakeState 2377;
BA_ "FlexKomSigLaenge" SG_ 653 EBCM_BrakeState 64;
BA_ "FlexKomSigName" SG_ 653 EBCM_BrakeState "EBCM_C1_Pkt";
BA_ "FlexKomSigStartPos" SG_ 653 EBCM_BrakeState 7;
BA_ "FlexKomSigStartValue" SG_ 653 EBCM_BrakeState "0000F003FFFE00FFh";
BA_ "GenSigCycleTime" SG_ 653 EBCM_BrakeState 20;
BA_ "GenSigSNA" SG_ 653 EBCM_BrakeState "7h";
BA_ "GenSigTimeout_RHSC2" SG_ 653 EBCM_BrakeState 70;
BA_ "FlexKomComment" SG_ 653 EstBrakeTorqueAppliedSec "Message EBCM_C1 packet";
BA_ "FlexKomIsMotorola" SG_ 653 EstBrakeTorqueAppliedSec 1;
BA_ "FlexKomSID" SG_ 653 EstBrakeTorqueAppliedSec 2377;
BA_ "FlexKomSigLaenge" SG_ 653 EstBrakeTorqueAppliedSec 64;
BA_ "FlexKomSigName" SG_ 653 EstBrakeTorqueAppliedSec "EBCM_C1_Pkt";
BA_ "FlexKomSigStartPos" SG_ 653 EstBrakeTorqueAppliedSec 7;
BA_ "FlexKomSigStartValue" SG_ 653 EstBrakeTorqueAppliedSec "0000F003FFFE00FFh";
BA_ "GenSigCycleTime" SG_ 653 EstBrakeTorqueAppliedSec 20;
BA_ "GenSigSNA" SG_ 653 EstBrakeTorqueAppliedSec "0h";
BA_ "FlexKomComment" SG_ 653 MC_EBCM_C1 "Message EBCM_C1 packet";
BA_ "FlexKomIsMotorola" SG_ 653 MC_EBCM_C1 1;
BA_ "FlexKomSID" SG_ 653 MC_EBCM_C1 2377;
BA_ "FlexKomSigLaenge" SG_ 653 MC_EBCM_C1 64;
BA_ "FlexKomSigName" SG_ 653 MC_EBCM_C1 "EBCM_C1_Pkt";
BA_ "FlexKomSigStartPos" SG_ 653 MC_EBCM_C1 7;
BA_ "FlexKomSigStartValue" SG_ 653 MC_EBCM_C1 "0000F003FFFE00FFh";
BA_ "GenSigCycleTime" SG_ 653 MC_EBCM_C1 20;
BA_ "GenSigSNA" SG_ 653 MC_EBCM_C1 "0h";
BA_ "GenSigTimeout_RHSC2" SG_ 653 MC_EBCM_C1 70;
BA_ "FlexKomComment" SG_ 653 MIL_OnRq_EBCM "Message EBCM_C1 packet";
BA_ "FlexKomIsMotorola" SG_ 653 MIL_OnRq_EBCM 1;
BA_ "FlexKomSID" SG_ 653 MIL_OnRq_EBCM 2377;
BA_ "FlexKomSigLaenge" SG_ 653 MIL_OnRq_EBCM 64;
BA_ "FlexKomSigName" SG_ 653 MIL_OnRq_EBCM "EBCM_C1_Pkt";
BA_ "FlexKomSigStartPos" SG_ 653 MIL_OnRq_EBCM 7;
BA_ "FlexKomSigStartValue" SG_ 653 MIL_OnRq_EBCM "0000F003FFFE00FFh";
BA_ "GenSigCycleTime" SG_ 653 MIL_OnRq_EBCM 20;
BA_ "GenSigSNA" SG_ 653 MIL_OnRq_EBCM "0h";
BA_ "FlexKomComment" SG_ 653 SDS_Engaged_State_EBCM "Message EBCM_C1 packet";
BA_ "FlexKomIsMotorola" SG_ 653 SDS_Engaged_State_EBCM 1;
BA_ "FlexKomSID" SG_ 653 SDS_Engaged_State_EBCM 2377;
BA_ "FlexKomSigLaenge" SG_ 653 SDS_Engaged_State_EBCM 64;
BA_ "FlexKomSigName" SG_ 653 SDS_Engaged_State_EBCM "EBCM_C1_Pkt";
BA_ "FlexKomSigStartPos" SG_ 653 SDS_Engaged_State_EBCM 7;
BA_ "FlexKomSigStartValue" SG_ 653 SDS_Engaged_State_EBCM "0000F003FFFE00FFh";
BA_ "GenSigCycleTime" SG_ 653 SDS_Engaged_State_EBCM 20;
BA_ "GenSigSNA" SG_ 653 SDS_Engaged_State_EBCM "3h";
BA_ "GenSigTimeout_RHSC2" SG_ 653 SDS_Engaged_State_EBCM 70;
BA_ "FlexKomComment" SG_ 653 ThermalCapacitySec "Message EBCM_C1 packet";
BA_ "FlexKomIsMotorola" SG_ 653 ThermalCapacitySec 1;
BA_ "FlexKomSID" SG_ 653 ThermalCapacitySec 2377;
BA_ "FlexKomSigLaenge" SG_ 653 ThermalCapacitySec 64;
BA_ "FlexKomSigName" SG_ 653 ThermalCapacitySec "EBCM_C1_Pkt";
BA_ "FlexKomSigStartPos" SG_ 653 ThermalCapacitySec 7;
BA_ "FlexKomSigStartValue" SG_ 653 ThermalCapacitySec "0000F003FFFE00FFh";
BA_ "GenSigCycleTime" SG_ 653 ThermalCapacitySec 20;
BA_ "GenSigSNA" SG_ 653 ThermalCapacitySec "0h";
BA_ "FlexKomComment" SG_ 264 CRC_ECM_A1 "ECM_A1 Packet";
BA_ "FlexKomIsMotorola" SG_ 264 CRC_ECM_A1 1;
BA_ "FlexKomSID" SG_ 264 CRC_ECM_A1 446;
BA_ "FlexKomSigLaenge" SG_ 264 CRC_ECM_A1 64;
BA_ "FlexKomSigName" SG_ 264 CRC_ECM_A1 "ECM_A1_PKT";
BA_ "FlexKomSigStartPos" SG_ 264 CRC_ECM_A1 7;
BA_ "FlexKomSigStartValue" SG_ 264 CRC_ECM_A1 "FFFF1FFF1FFF00FFh";
BA_ "GenSigCycleTime" SG_ 264 CRC_ECM_A1 10;
BA_ "GenSigSNA" SG_ 264 CRC_ECM_A1 "FFh";
BA_ "GenSigStartValue" SG_ 264 CRC_ECM_A1 255;
BA_ "FlexKomComment" SG_ 264 ECM_IMMO_STAT_CANC "ECM_A1 Packet";
BA_ "FlexKomIsMotorola" SG_ 264 ECM_IMMO_STAT_CANC 1;
BA_ "FlexKomSID" SG_ 264 ECM_IMMO_STAT_CANC 446;
BA_ "FlexKomSigLaenge" SG_ 264 ECM_IMMO_STAT_CANC 64;
BA_ "FlexKomSigName" SG_ 264 ECM_IMMO_STAT_CANC "ECM_A1_PKT";
BA_ "FlexKomSigStartPos" SG_ 264 ECM_IMMO_STAT_CANC 7;
BA_ "FlexKomSigStartValue" SG_ 264 ECM_IMMO_STAT_CANC "FFFF1FFF1FFF00FFh";
BA_ "GenSigCycleTime" SG_ 264 ECM_IMMO_STAT_CANC 10;
BA_ "GenSigSNA" SG_ 264 ECM_IMMO_STAT_CANC "3h";
BA_ "GenSigTimeout_CBC" SG_ 264 ECM_IMMO_STAT_CANC 105;
BA_ "FlexKomComment" SG_ 264 EngRPM "ECM_A1 Packet";
BA_ "FlexKomIsMotorola" SG_ 264 EngRPM 1;
BA_ "FlexKomSID" SG_ 264 EngRPM 446;
BA_ "FlexKomSigLaenge" SG_ 264 EngRPM 64;
BA_ "FlexKomSigName" SG_ 264 EngRPM "ECM_A1_PKT";
BA_ "FlexKomSigStartPos" SG_ 264 EngRPM 7;
BA_ "FlexKomSigStartValue" SG_ 264 EngRPM "FFFF1FFF1FFF00FFh";
BA_ "GenSigCycleTime" SG_ 264 EngRPM 10;
BA_ "GenSigSNA" SG_ 264 EngRPM "FFFFh";
BA_ "GenSigStartValue" SG_ 264 EngRPM 65535;
BA_ "GenSigTimeout_CBC" SG_ 264 EngRPM 105;
BA_ "GenSigTimeout_EPS" SG_ 264 EngRPM 105;
BA_ "GenSigTimeout_RHSC2" SG_ 264 EngRPM 105;
BA_ "GenSigTimeout_IC" SG_ 264 EngRPM 105;
BA_ "GenSigTimeout_ORC" SG_ 264 EngRPM 35;
BA_ "RID" SG_ 264 EngRPM "2185";
BA_ "FlexKomComment" SG_ 264 MC_ECM_A1 "ECM_A1 Packet";
BA_ "FlexKomIsMotorola" SG_ 264 MC_ECM_A1 1;
BA_ "FlexKomSID" SG_ 264 MC_ECM_A1 446;
BA_ "FlexKomSigLaenge" SG_ 264 MC_ECM_A1 64;
BA_ "FlexKomSigName" SG_ 264 MC_ECM_A1 "ECM_A1_PKT";
BA_ "FlexKomSigStartPos" SG_ 264 MC_ECM_A1 7;
BA_ "FlexKomSigStartValue" SG_ 264 MC_ECM_A1 "FFFF1FFF1FFF00FFh";
BA_ "GenSigCycleTime" SG_ 264 MC_ECM_A1 10;
BA_ "GenSigSNA" SG_ 264 MC_ECM_A1 "0h";
BA_ "FlexKomComment" SG_ 288 AccelPdlPosn "ECM_A2 Packet";
BA_ "FlexKomIsMotorola" SG_ 288 AccelPdlPosn 1;
BA_ "FlexKomSID" SG_ 288 AccelPdlPosn 455;
BA_ "FlexKomSigLaenge" SG_ 288 AccelPdlPosn 56;
BA_ "FlexKomSigName" SG_ 288 AccelPdlPosn "ECM_A2_PKT";
BA_ "FlexKomSigStartPos" SG_ 288 AccelPdlPosn 7;
BA_ "FlexKomSigStartValue" SG_ 288 AccelPdlPosn "1FFFFF1FFF00FFh";
BA_ "GenSigCycleTime" SG_ 288 AccelPdlPosn 20;
BA_ "GenSigSNA" SG_ 288 AccelPdlPosn "FFh";
BA_ "GenSigStartValue" SG_ 288 AccelPdlPosn 255;
BA_ "GenSigTimeout_ETM" SG_ 288 AccelPdlPosn 210;
BA_ "RID" SG_ 288 AccelPdlPosn "5036";
BA_ "FlexKomComment" SG_ 288 AccelPdlPosnSens_Flt "ECM_A2 Packet";
BA_ "FlexKomIsMotorola" SG_ 288 AccelPdlPosnSens_Flt 1;
BA_ "FlexKomSID" SG_ 288 AccelPdlPosnSens_Flt 455;
BA_ "FlexKomSigLaenge" SG_ 288 AccelPdlPosnSens_Flt 56;
BA_ "FlexKomSigName" SG_ 288 AccelPdlPosnSens_Flt "ECM_A2_PKT";
BA_ "FlexKomSigStartPos" SG_ 288 AccelPdlPosnSens_Flt 7;
BA_ "FlexKomSigStartValue" SG_ 288 AccelPdlPosnSens_Flt "1FFFFF1FFF00FFh";
BA_ "GenSigCycleTime" SG_ 288 AccelPdlPosnSens_Flt 20;
BA_ "GenSigSNA" SG_ 288 AccelPdlPosnSens_Flt "0h";
BA_ "RID" SG_ 288 AccelPdlPosnSens_Flt "5031";
BA_ "FlexKomComment" SG_ 288 CRC_ECM_A2 "ECM_A2 Packet";
BA_ "FlexKomIsMotorola" SG_ 288 CRC_ECM_A2 1;
BA_ "FlexKomSID" SG_ 288 CRC_ECM_A2 455;
BA_ "FlexKomSigLaenge" SG_ 288 CRC_ECM_A2 56;
BA_ "FlexKomSigName" SG_ 288 CRC_ECM_A2 "ECM_A2_PKT";
BA_ "FlexKomSigStartPos" SG_ 288 CRC_ECM_A2 7;
BA_ "FlexKomSigStartValue" SG_ 288 CRC_ECM_A2 "1FFFFF1FFF00FFh";
BA_ "GenSigCycleTime" SG_ 288 CRC_ECM_A2 20;
BA_ "GenSigSNA" SG_ 288 CRC_ECM_A2 "FFh";
BA_ "GenSigStartValue" SG_ 288 CRC_ECM_A2 255;
BA_ "FlexKomComment" SG_ 288 CRUISE_OVERRIDE "ECM_A2 Packet";
BA_ "FlexKomIsMotorola" SG_ 288 CRUISE_OVERRIDE 1;
BA_ "FlexKomSID" SG_ 288 CRUISE_OVERRIDE 455;
BA_ "FlexKomSigLaenge" SG_ 288 CRUISE_OVERRIDE 56;
BA_ "FlexKomSigName" SG_ 288 CRUISE_OVERRIDE "ECM_A2_PKT";
BA_ "FlexKomSigStartPos" SG_ 288 CRUISE_OVERRIDE 7;
BA_ "FlexKomSigStartValue" SG_ 288 CRUISE_OVERRIDE "1FFFFF1FFF00FFh";
BA_ "GenSigCycleTime" SG_ 288 CRUISE_OVERRIDE 20;
BA_ "GenSigSNA" SG_ 288 CRUISE_OVERRIDE "0h";
BA_ "GenSigTimeout_IC" SG_ 288 CRUISE_OVERRIDE 210;
BA_ "FlexKomComment" SG_ 288 ECM_LHOM "ECM_A2 Packet";
BA_ "FlexKomIsMotorola" SG_ 288 ECM_LHOM 1;
BA_ "FlexKomSID" SG_ 288 ECM_LHOM 455;
BA_ "FlexKomSigLaenge" SG_ 288 ECM_LHOM 56;
BA_ "FlexKomSigName" SG_ 288 ECM_LHOM "ECM_A2_PKT";
BA_ "FlexKomSigStartPos" SG_ 288 ECM_LHOM 7;
BA_ "FlexKomSigStartValue" SG_ 288 ECM_LHOM "1FFFFF1FFF00FFh";
BA_ "GenSigCycleTime" SG_ 288 ECM_LHOM 20;
BA_ "GenSigSNA" SG_ 288 ECM_LHOM "0h";
BA_ "FlexKomComment" SG_ 288 ESS_RqShftPark "ECM_A2 Packet";
BA_ "FlexKomIsMotorola" SG_ 288 ESS_RqShftPark 1;
BA_ "FlexKomSID" SG_ 288 ESS_RqShftPark 455;
BA_ "FlexKomSigLaenge" SG_ 288 ESS_RqShftPark 56;
BA_ "FlexKomSigName" SG_ 288 ESS_RqShftPark "ECM_A2_PKT";
BA_ "FlexKomSigStartPos" SG_ 288 ESS_RqShftPark 7;
BA_ "FlexKomSigStartValue" SG_ 288 ESS_RqShftPark "1FFFFF1FFF00FFh";
BA_ "GenSigCycleTime" SG_ 288 ESS_RqShftPark 20;
BA_ "GenSigSNA" SG_ 288 ESS_RqShftPark "0h";
BA_ "FlexKomComment" SG_ 288 EngTrq_Enbl_Rq_AS "ECM_A2 Packet";
BA_ "FlexKomIsMotorola" SG_ 288 EngTrq_Enbl_Rq_AS 1;
BA_ "FlexKomSID" SG_ 288 EngTrq_Enbl_Rq_AS 455;
BA_ "FlexKomSigLaenge" SG_ 288 EngTrq_Enbl_Rq_AS 56;
BA_ "FlexKomSigName" SG_ 288 EngTrq_Enbl_Rq_AS "ECM_A2_PKT";
BA_ "FlexKomSigStartPos" SG_ 288 EngTrq_Enbl_Rq_AS 7;
BA_ "FlexKomSigStartValue" SG_ 288 EngTrq_Enbl_Rq_AS "1FFFFF1FFF00FFh";
BA_ "GenSigCycleTime" SG_ 288 EngTrq_Enbl_Rq_AS 20;
BA_ "GenSigSNA" SG_ 288 EngTrq_Enbl_Rq_AS "0h";
BA_ "FlexKomComment" SG_ 288 EngTrq_Enbl_Rq_ESC "ECM_A2 Packet";
BA_ "FlexKomIsMotorola" SG_ 288 EngTrq_Enbl_Rq_ESC 1;
BA_ "FlexKomSID" SG_ 288 EngTrq_Enbl_Rq_ESC 455;
BA_ "FlexKomSigLaenge" SG_ 288 EngTrq_Enbl_Rq_ESC 56;
BA_ "FlexKomSigName" SG_ 288 EngTrq_Enbl_Rq_ESC "ECM_A2_PKT";
BA_ "FlexKomSigStartPos" SG_ 288 EngTrq_Enbl_Rq_ESC 7;
BA_ "FlexKomSigStartValue" SG_ 288 EngTrq_Enbl_Rq_ESC "1FFFFF1FFF00FFh";
BA_ "GenSigCycleTime" SG_ 288 EngTrq_Enbl_Rq_ESC 20;
BA_ "GenSigSNA" SG_ 288 EngTrq_Enbl_Rq_ESC "0h";
BA_ "FlexKomComment" SG_ 288 LV12PwrFreeRq "ECM_A2 Packet";
BA_ "FlexKomIsMotorola" SG_ 288 LV12PwrFreeRq 1;
BA_ "FlexKomSID" SG_ 288 LV12PwrFreeRq 455;
BA_ "FlexKomSigLaenge" SG_ 288 LV12PwrFreeRq 56;
BA_ "FlexKomSigName" SG_ 288 LV12PwrFreeRq "ECM_A2_PKT";
BA_ "FlexKomSigStartPos" SG_ 288 LV12PwrFreeRq 7;
BA_ "FlexKomSigStartValue" SG_ 288 LV12PwrFreeRq "1FFFFF1FFF00FFh";
BA_ "GenSigCycleTime" SG_ 288 LV12PwrFreeRq 20;
BA_ "GenSigSNA" SG_ 288 LV12PwrFreeRq "0h";
BA_ "FlexKomComment" SG_ 288 MC_ECM_A2 "ECM_A2 Packet";
BA_ "FlexKomIsMotorola" SG_ 288 MC_ECM_A2 1;
BA_ "FlexKomSID" SG_ 288 MC_ECM_A2 455;
BA_ "FlexKomSigLaenge" SG_ 288 MC_ECM_A2 56;
BA_ "FlexKomSigName" SG_ 288 MC_ECM_A2 "ECM_A2_PKT";
BA_ "FlexKomSigStartPos" SG_ 288 MC_ECM_A2 7;
BA_ "FlexKomSigStartValue" SG_ 288 MC_ECM_A2 "1FFFFF1FFF00FFh";
BA_ "GenSigCycleTime" SG_ 288 MC_ECM_A2 20;
BA_ "GenSigSNA" SG_ 288 MC_ECM_A2 "0h";
BA_ "FlexKomComment" SG_ 288 RPMOverRev "ECM_A2 Packet";
BA_ "FlexKomIsMotorola" SG_ 288 RPMOverRev 1;
BA_ "FlexKomSID" SG_ 288 RPMOverRev 455;
BA_ "FlexKomSigLaenge" SG_ 288 RPMOverRev 56;
BA_ "FlexKomSigName" SG_ 288 RPMOverRev "ECM_A2_PKT";
BA_ "FlexKomSigStartPos" SG_ 288 RPMOverRev 7;
BA_ "FlexKomSigStartValue" SG_ 288 RPMOverRev "1FFFFF1FFF00FFh";
BA_ "GenSigCycleTime" SG_ 288 RPMOverRev 20;
BA_ "GenSigSNA" SG_ 288 RPMOverRev "0h";
BA_ "FlexKomComment" SG_ 760 CRC_ECM_A3 "ECM_A3 message packet";
BA_ "FlexKomIsMotorola" SG_ 760 CRC_ECM_A3 1;
BA_ "FlexKomSID" SG_ 760 CRC_ECM_A3 1369;
BA_ "FlexKomSigLaenge" SG_ 760 CRC_ECM_A3 64;
BA_ "FlexKomSigName" SG_ 760 CRC_ECM_A3 "ECM_A3_PKT";
BA_ "FlexKomSigStartPos" SG_ 760 CRC_ECM_A3 7;
BA_ "FlexKomSigStartValue" SG_ 760 CRC_ECM_A3 "5FFF1FFF00FF0FFFh";
BA_ "GenSigCycleTime" SG_ 760 CRC_ECM_A3 10;
BA_ "GenSigSNA" SG_ 760 CRC_ECM_A3 "FFh";
BA_ "GenSigStartValue" SG_ 760 CRC_ECM_A3 255;
BA_ "FlexKomComment" SG_ 760 ESS_ENG_ST "ECM_A3 message packet";
BA_ "FlexKomIsMotorola" SG_ 760 ESS_ENG_ST 1;
BA_ "FlexKomSID" SG_ 760 ESS_ENG_ST 1369;
BA_ "FlexKomSigLaenge" SG_ 760 ESS_ENG_ST 64;
BA_ "FlexKomSigName" SG_ 760 ESS_ENG_ST "ECM_A3_PKT";
BA_ "FlexKomSigStartPos" SG_ 760 ESS_ENG_ST 7;
BA_ "FlexKomSigStartValue" SG_ 760 ESS_ENG_ST "5FFF1FFF00FF0FFFh";
BA_ "GenSigCycleTime" SG_ 760 ESS_ENG_ST 10;
BA_ "GenSigSNA" SG_ 760 ESS_ENG_ST "Fh";
BA_ "GenSigStartValue" SG_ 760 ESS_ENG_ST 15;
BA_ "GenSigTimeout_CBC" SG_ 760 ESS_ENG_ST 105;
BA_ "GenSigTimeout_ORC" SG_ 760 ESS_ENG_ST 35;
BA_ "GenSigTimeout_RF_HUB" SG_ 760 ESS_ENG_ST 105;
BA_ "RID" SG_ 760 ESS_ENG_ST "1653";
BA_ "FlexKomComment" SG_ 760 MC_ECM_A3 "ECM_A3 message packet";
BA_ "FlexKomIsMotorola" SG_ 760 MC_ECM_A3 1;
BA_ "FlexKomSID" SG_ 760 MC_ECM_A3 1369;
BA_ "FlexKomSigLaenge" SG_ 760 MC_ECM_A3 64;
BA_ "FlexKomSigName" SG_ 760 MC_ECM_A3 "ECM_A3_PKT";
BA_ "FlexKomSigStartPos" SG_ 760 MC_ECM_A3 7;
BA_ "FlexKomSigStartValue" SG_ 760 MC_ECM_A3 "5FFF1FFF00FF0FFFh";
BA_ "GenSigCycleTime" SG_ 760 MC_ECM_A3 10;
BA_ "GenSigSNA" SG_ 760 MC_ECM_A3 "0h";
BA_ "RID" SG_ 760 MC_ECM_A3 "9769";
BA_ "FlexKomComment" SG_ 559 ActlAccelPdlPosn "ECM_A5 Packet";
BA_ "FlexKomIsMotorola" SG_ 559 ActlAccelPdlPosn 1;
BA_ "FlexKomSID" SG_ 559 ActlAccelPdlPosn 1821;
BA_ "FlexKomSigLaenge" SG_ 559 ActlAccelPdlPosn 64;
BA_ "FlexKomSigName" SG_ 559 ActlAccelPdlPosn "ECM_A5_PKT";
BA_ "FlexKomSigStartPos" SG_ 559 ActlAccelPdlPosn 7;
BA_ "FlexKomSigStartValue" SG_ 559 ActlAccelPdlPosn "FFFFFFFF00000CFFh";
BA_ "GenSigCycleTime" SG_ 559 ActlAccelPdlPosn 20;
BA_ "GenSigSNA" SG_ 559 ActlAccelPdlPosn "FFh";
BA_ "GenSigStartValue" SG_ 559 ActlAccelPdlPosn 255;
BA_ "GenSigTimeout_CBC" SG_ 559 ActlAccelPdlPosn 210;
BA_ "RID" SG_ 559 ActlAccelPdlPosn "5035";
BA_ "FlexKomComment" SG_ 559 CRC_ECM_A5 "ECM_A5 Packet";
BA_ "FlexKomIsMotorola" SG_ 559 CRC_ECM_A5 1;
BA_ "FlexKomSID" SG_ 559 CRC_ECM_A5 1821;
BA_ "FlexKomSigLaenge" SG_ 559 CRC_ECM_A5 64;
BA_ "FlexKomSigName" SG_ 559 CRC_ECM_A5 "ECM_A5_PKT";
BA_ "FlexKomSigStartPos" SG_ 559 CRC_ECM_A5 7;
BA_ "FlexKomSigStartValue" SG_ 559 CRC_ECM_A5 "FFFFFFFF00000CFFh";
BA_ "GenSigCycleTime" SG_ 559 CRC_ECM_A5 20;
BA_ "GenSigSNA" SG_ 559 CRC_ECM_A5 "FFh";
BA_ "GenSigStartValue" SG_ 559 CRC_ECM_A5 255;
BA_ "FlexKomComment" SG_ 559 MC_ECM_A5 "ECM_A5 Packet";
BA_ "FlexKomIsMotorola" SG_ 559 MC_ECM_A5 1;
BA_ "FlexKomSID" SG_ 559 MC_ECM_A5 1821;
BA_ "FlexKomSigLaenge" SG_ 559 MC_ECM_A5 64;
BA_ "FlexKomSigName" SG_ 559 MC_ECM_A5 "ECM_A5_PKT";
BA_ "FlexKomSigStartPos" SG_ 559 MC_ECM_A5 7;
BA_ "FlexKomSigStartValue" SG_ 559 MC_ECM_A5 "FFFFFFFF00000CFFh";
BA_ "GenSigCycleTime" SG_ 559 MC_ECM_A5 20;
BA_ "GenSigSNA" SG_ 559 MC_ECM_A5 "0h";
BA_ "FlexKomComment" SG_ 864 ECM_APPL1 "Application";
BA_ "FlexKomIsMotorola" SG_ 864 ECM_APPL1 1;
BA_ "FlexKomSID" SG_ 864 ECM_APPL1 780;
BA_ "FlexKomSigLaenge" SG_ 864 ECM_APPL1 64;
BA_ "FlexKomSigName" SG_ 864 ECM_APPL1 "ECM_APPL1";
BA_ "FlexKomSigStartPos" SG_ 864 ECM_APPL1 7;
BA_ "FlexKomSigStartValue" SG_ 864 ECM_APPL1 "0000000000000000h";
BA_ "GenSigSendType" SG_ 864 ECM_APPL1 1;
BA_ "GenSigSNA" SG_ 864 ECM_APPL1 "0h";
BA_ "FlexKomComment" SG_ 850 ECM_APPL2 "Application";
BA_ "FlexKomIsMotorola" SG_ 850 ECM_APPL2 1;
BA_ "FlexKomSID" SG_ 850 ECM_APPL2 1110;
BA_ "FlexKomSigLaenge" SG_ 850 ECM_APPL2 64;
BA_ "FlexKomSigName" SG_ 850 ECM_APPL2 "ECM_APPL2";
BA_ "FlexKomSigStartPos" SG_ 850 ECM_APPL2 7;
BA_ "FlexKomSigStartValue" SG_ 850 ECM_APPL2 "0000000000000000h";
BA_ "GenSigSendType" SG_ 850 ECM_APPL2 1;
BA_ "GenSigSNA" SG_ 850 ECM_APPL2 "0h";
BA_ "FlexKomComment" SG_ 880 ECM_APPL3 "CCP synchronous - TDC event DAQ";
BA_ "FlexKomIsMotorola" SG_ 880 ECM_APPL3 1;
BA_ "FlexKomSID" SG_ 880 ECM_APPL3 781;
BA_ "FlexKomSigLaenge" SG_ 880 ECM_APPL3 64;
BA_ "FlexKomSigName" SG_ 880 ECM_APPL3 "ECM_APPL3";
BA_ "FlexKomSigStartPos" SG_ 880 ECM_APPL3 7;
BA_ "FlexKomSigStartValue" SG_ 880 ECM_APPL3 "0000000000000000h";
BA_ "GenSigSendType" SG_ 880 ECM_APPL3 1;
BA_ "GenSigSNA" SG_ 880 ECM_APPL3 "0h";
BA_ "FlexKomComment" SG_ 896 ECM_APPL4 "CCP 5ms DAQ  (from ENGINE to external tool)";
BA_ "FlexKomIsMotorola" SG_ 896 ECM_APPL4 1;
BA_ "FlexKomSID" SG_ 896 ECM_APPL4 782;
BA_ "FlexKomSigLaenge" SG_ 896 ECM_APPL4 64;
BA_ "FlexKomSigName" SG_ 896 ECM_APPL4 "ECM_APPL4";
BA_ "FlexKomSigStartPos" SG_ 896 ECM_APPL4 7;
BA_ "FlexKomSigStartValue" SG_ 896 ECM_APPL4 "0000000000000000h";
BA_ "GenSigSendType" SG_ 896 ECM_APPL4 1;
BA_ "GenSigSNA" SG_ 896 ECM_APPL4 "0h";
BA_ "FlexKomComment" SG_ 912 ECM_APPL5 "CCP 10ms DAQ  (from ENGINE to external tool)";
BA_ "FlexKomIsMotorola" SG_ 912 ECM_APPL5 1;
BA_ "FlexKomSID" SG_ 912 ECM_APPL5 783;
BA_ "FlexKomSigLaenge" SG_ 912 ECM_APPL5 64;
BA_ "FlexKomSigName" SG_ 912 ECM_APPL5 "ECM_APPL5";
BA_ "FlexKomSigStartPos" SG_ 912 ECM_APPL5 7;
BA_ "FlexKomSigStartValue" SG_ 912 ECM_APPL5 "0000000000000000h";
BA_ "GenSigSendType" SG_ 912 ECM_APPL5 1;
BA_ "GenSigSNA" SG_ 912 ECM_APPL5 "0h";
BA_ "FlexKomComment" SG_ 928 ECM_APPL6 "CCP 80ms DAQ  (from ENGINE to external tool)";
BA_ "FlexKomIsMotorola" SG_ 928 ECM_APPL6 1;
BA_ "FlexKomSID" SG_ 928 ECM_APPL6 784;
BA_ "FlexKomSigLaenge" SG_ 928 ECM_APPL6 64;
BA_ "FlexKomSigName" SG_ 928 ECM_APPL6 "ECM_APPL6";
BA_ "FlexKomSigStartPos" SG_ 928 ECM_APPL6 7;
BA_ "FlexKomSigStartValue" SG_ 928 ECM_APPL6 "0000000000000000h";
BA_ "GenSigSendType" SG_ 928 ECM_APPL6 1;
BA_ "GenSigSNA" SG_ 928 ECM_APPL6 "0h";
BA_ "FlexKomComment" SG_ 936 ECM_APPL7 "Application";
BA_ "FlexKomIsMotorola" SG_ 936 ECM_APPL7 1;
BA_ "FlexKomSID" SG_ 936 ECM_APPL7 1111;
BA_ "FlexKomSigLaenge" SG_ 936 ECM_APPL7 64;
BA_ "FlexKomSigName" SG_ 936 ECM_APPL7 "ECM_APPL7";
BA_ "FlexKomSigStartPos" SG_ 936 ECM_APPL7 7;
BA_ "FlexKomSigStartValue" SG_ 936 ECM_APPL7 "0000000000000000h";
BA_ "GenSigSendType" SG_ 936 ECM_APPL7 1;
BA_ "GenSigSNA" SG_ 936 ECM_APPL7 "0h";
BA_ "FlexKomComment" SG_ 632 CC_SetSpdDspl "Cruise control set speed for display (kmph only)";
BA_ "FlexKomIsMotorola" SG_ 632 CC_SetSpdDspl 1;
BA_ "FlexKomSID" SG_ 632 CC_SetSpdDspl 1361;
BA_ "FlexKomSigLaenge" SG_ 632 CC_SetSpdDspl 8;
BA_ "FlexKomSigName" SG_ 632 CC_SetSpdDspl "CC_SetSpdDspl";
BA_ "FlexKomSigStartPos" SG_ 632 CC_SetSpdDspl 7;
BA_ "FlexKomSigStartValue" SG_ 632 CC_SetSpdDspl "FFh";
BA_ "GenSigCycleTime" SG_ 632 CC_SetSpdDspl 100;
BA_ "GenSigSNA" SG_ 632 CC_SetSpdDspl "FFh";
BA_ "GenSigStartValue" SG_ 632 CC_SetSpdDspl 255;
BA_ "GenSigTimeout_IC" SG_ 632 CC_SetSpdDspl 1050;
BA_ "FlexKomComment" SG_ 632 CC_SetSpdDsplMPH "Cruise control set speed for display in miles per ";
BA_ "FlexKomIsMotorola" SG_ 632 CC_SetSpdDsplMPH 1;
BA_ "FlexKomSID" SG_ 632 CC_SetSpdDsplMPH 1610;
BA_ "FlexKomSigLaenge" SG_ 632 CC_SetSpdDsplMPH 8;
BA_ "FlexKomSigName" SG_ 632 CC_SetSpdDsplMPH "CC_SetSpdDsplMPH";
BA_ "FlexKomSigStartPos" SG_ 632 CC_SetSpdDsplMPH 47;
BA_ "FlexKomSigStartValue" SG_ 632 CC_SetSpdDsplMPH "FFh";
BA_ "GenSigCycleTime" SG_ 632 CC_SetSpdDsplMPH 100;
BA_ "GenSigSNA" SG_ 632 CC_SetSpdDsplMPH "FFh";
BA_ "GenSigStartValue" SG_ 632 CC_SetSpdDsplMPH 255;
BA_ "GenSigTimeout_IC" SG_ 632 CC_SetSpdDsplMPH 1050;
BA_ "FlexKomComment" SG_ 632 ESS_ActvEBrake "ESS active E-brake. 1 = Active, 0 = Inactive";
BA_ "FlexKomIsMotorola" SG_ 632 ESS_ActvEBrake 1;
BA_ "FlexKomSID" SG_ 632 ESS_ActvEBrake 2528;
BA_ "FlexKomSigLaenge" SG_ 632 ESS_ActvEBrake 1;
BA_ "FlexKomSigName" SG_ 632 ESS_ActvEBrake "ESS_ActvEBrake";
BA_ "FlexKomSigStartPos" SG_ 632 ESS_ActvEBrake 38;
BA_ "FlexKomSigStartValue" SG_ 632 ESS_ActvEBrake "00h";
BA_ "GenSigCycleTime" SG_ 632 ESS_ActvEBrake 100;
BA_ "GenSigSNA" SG_ 632 ESS_ActvEBrake "0h";
BA_ "FlexKomComment" SG_ 632 SpStDispstat "Stop start packet";
BA_ "FlexKomIsMotorola" SG_ 632 SpStDispstat 1;
BA_ "FlexKomSID" SG_ 632 SpStDispstat 1567;
BA_ "FlexKomSigLaenge" SG_ 632 SpStDispstat 16;
BA_ "FlexKomSigName" SG_ 632 SpStDispstat "SpStPacket";
BA_ "FlexKomSigStartPos" SG_ 632 SpStDispstat 55;
BA_ "FlexKomSigStartValue" SG_ 632 SpStDispstat "0000h";
BA_ "GenSigCycleTime" SG_ 632 SpStDispstat 100;
BA_ "GenSigSNA" SG_ 632 SpStDispstat "3Fh";
BA_ "GenSigTimeout_IC" SG_ 632 SpStDispstat 1050;
BA_ "GenSigTimeout_ORC" SG_ 632 SpStDispstat 350;
BA_ "FlexKomComment" SG_ 632 SpStSwStat "Stop start packet";
BA_ "FlexKomIsMotorola" SG_ 632 SpStSwStat 1;
BA_ "FlexKomSID" SG_ 632 SpStSwStat 1567;
BA_ "FlexKomSigLaenge" SG_ 632 SpStSwStat 16;
BA_ "FlexKomSigName" SG_ 632 SpStSwStat "SpStPacket";
BA_ "FlexKomSigStartPos" SG_ 632 SpStSwStat 55;
BA_ "FlexKomSigStartValue" SG_ 632 SpStSwStat "0000h";
BA_ "GenSigCycleTime" SG_ 632 SpStSwStat 100;
BA_ "GenSigSNA" SG_ 632 SpStSwStat "3h";
BA_ "GenSigTimeout_CBC" SG_ 632 SpStSwStat 1050;
BA_ "GenSigTimeout_IC" SG_ 632 SpStSwStat 1050;
BA_ "GenSigTimeout_ORC" SG_ 632 SpStSwStat 350;
BA_ "RID" SG_ 632 SpStSwStat "1002 1617 1706 5114";
BA_ "FlexKomComment" SG_ 632 SpStWarnStat "Stop start packet";
BA_ "FlexKomIsMotorola" SG_ 632 SpStWarnStat 1;
BA_ "FlexKomSID" SG_ 632 SpStWarnStat 1567;
BA_ "FlexKomSigLaenge" SG_ 632 SpStWarnStat 16;
BA_ "FlexKomSigName" SG_ 632 SpStWarnStat "SpStPacket";
BA_ "FlexKomSigStartPos" SG_ 632 SpStWarnStat 55;
BA_ "FlexKomSigStartValue" SG_ 632 SpStWarnStat "0000h";
BA_ "GenSigCycleTime" SG_ 632 SpStWarnStat 100;
BA_ "GenSigSNA" SG_ 632 SpStWarnStat "Fh";
BA_ "GenSigTimeout_IC" SG_ 632 SpStWarnStat 1050;
BA_ "GenSigTimeout_ORC" SG_ 632 SpStWarnStat 350;
BA_ "FlexKomComment" SG_ 384 AM_ECM_Prsnt "Aftermarket ECM present";
BA_ "FlexKomIsMotorola" SG_ 384 AM_ECM_Prsnt 1;
BA_ "FlexKomSID" SG_ 384 AM_ECM_Prsnt 1941;
BA_ "FlexKomSigLaenge" SG_ 384 AM_ECM_Prsnt 2;
BA_ "FlexKomSigName" SG_ 384 AM_ECM_Prsnt "AM_ECM_Prsnt";
BA_ "FlexKomSigStartPos" SG_ 384 AM_ECM_Prsnt 46;
BA_ "FlexKomSigStartValue" SG_ 384 AM_ECM_Prsnt "00h";
BA_ "GenSigCycleTime" SG_ 384 AM_ECM_Prsnt 100;
BA_ "GenSigSNA" SG_ 384 AM_ECM_Prsnt "3h";
BA_ "GenSigTimeout_CBC" SG_ 384 AM_ECM_Prsnt 1050;
BA_ "FlexKomComment" SG_ 384 AirPress_Outsd "Ambient air pressure (barometric pressure)";
BA_ "FlexKomIsMotorola" SG_ 384 AirPress_Outsd 1;
BA_ "FlexKomSID" SG_ 384 AirPress_Outsd 1084;
BA_ "FlexKomSigLaenge" SG_ 384 AirPress_Outsd 8;
BA_ "FlexKomSigName" SG_ 384 AirPress_Outsd "AirPress_Outsd";
BA_ "FlexKomSigStartPos" SG_ 384 AirPress_Outsd 23;
BA_ "FlexKomSigStartValue" SG_ 384 AirPress_Outsd "FFh";
BA_ "GenSigCycleTime" SG_ 384 AirPress_Outsd 100;
BA_ "GenSigSNA" SG_ 384 AirPress_Outsd "FFh";
BA_ "GenSigStartValue" SG_ 384 AirPress_Outsd 255;
BA_ "GenSigTimeout_ETM" SG_ 384 AirPress_Outsd 1050;
BA_ "GenSigTimeout_IC" SG_ 384 AirPress_Outsd 1050;
BA_ "GenSigTimeout_RF_HUB" SG_ 384 AirPress_Outsd 1050;
BA_ "FlexKomComment" SG_ 384 CHRG_FAIL "Charging system Failure (battery indicator request";
BA_ "FlexKomIsMotorola" SG_ 384 CHRG_FAIL 1;
BA_ "FlexKomSID" SG_ 384 CHRG_FAIL 1085;
BA_ "FlexKomSigLaenge" SG_ 384 CHRG_FAIL 1;
BA_ "FlexKomSigName" SG_ 384 CHRG_FAIL "CHRG_FAIL";
BA_ "FlexKomSigStartPos" SG_ 384 CHRG_FAIL 41;
BA_ "FlexKomSigStartValue" SG_ 384 CHRG_FAIL "00h";
BA_ "GenSigCycleTime" SG_ 384 CHRG_FAIL 100;
BA_ "GenSigSNA" SG_ 384 CHRG_FAIL "1h";
BA_ "GenSigTimeout_IC" SG_ 384 CHRG_FAIL 1050;
BA_ "GenSigTimeout_ORC" SG_ 384 CHRG_FAIL 350;
BA_ "FlexKomComment" SG_ 384 EngCoolTemp "Engine coolant temperature";
BA_ "FlexKomIsMotorola" SG_ 384 EngCoolTemp 1;
BA_ "FlexKomSID" SG_ 384 EngCoolTemp 711;
BA_ "FlexKomSigLaenge" SG_ 384 EngCoolTemp 8;
BA_ "FlexKomSigName" SG_ 384 EngCoolTemp "EngCoolTemp";
BA_ "FlexKomSigStartPos" SG_ 384 EngCoolTemp 15;
BA_ "FlexKomSigStartValue" SG_ 384 EngCoolTemp "FFh";
BA_ "GenSigCycleTime" SG_ 384 EngCoolTemp 100;
BA_ "GenSigSNA" SG_ 384 EngCoolTemp "FFh";
BA_ "GenSigStartValue" SG_ 384 EngCoolTemp 255;
BA_ "GenSigTimeout_CBC" SG_ 384 EngCoolTemp 1050;
BA_ "GenSigTimeout_IC" SG_ 384 EngCoolTemp 1050;
BA_ "RID" SG_ 384 EngCoolTemp "1130";
BA_ "FlexKomComment" SG_ 384 IntkAirTemp "Engine Intake Air Temperature";
BA_ "FlexKomIsMotorola" SG_ 384 IntkAirTemp 1;
BA_ "FlexKomSID" SG_ 384 IntkAirTemp 441;
BA_ "FlexKomSigLaenge" SG_ 384 IntkAirTemp 8;
BA_ "FlexKomSigName" SG_ 384 IntkAirTemp "IntkAirTemp";
BA_ "FlexKomSigStartPos" SG_ 384 IntkAirTemp 7;
BA_ "FlexKomSigStartValue" SG_ 384 IntkAirTemp "00h";
BA_ "GenSigCycleTime" SG_ 384 IntkAirTemp 100;
BA_ "GenSigSNA" SG_ 384 IntkAirTemp "FFh";
BA_ "GenSigTimeout_ETM" SG_ 384 IntkAirTemp 1050;
BA_ "GenSigTimeout_IC" SG_ 384 IntkAirTemp 1050;
BA_ "RID" SG_ 384 IntkAirTemp "1149";
BA_ "FlexKomComment" SG_ 384 SysVolt "Engine voltage packet";
BA_ "FlexKomIsMotorola" SG_ 384 SysVolt 1;
BA_ "FlexKomSID" SG_ 384 SysVolt 437;
BA_ "FlexKomSigLaenge" SG_ 384 SysVolt 16;
BA_ "FlexKomSigName" SG_ 384 SysVolt "EngVoltPkt";
BA_ "FlexKomSigStartPos" SG_ 384 SysVolt 31;
BA_ "FlexKomSigStartValue" SG_ 384 SysVolt "0000h";
BA_ "GenSigCycleTime" SG_ 384 SysVolt 100;
BA_ "GenSigSNA" SG_ 384 SysVolt "FFh";
BA_ "FlexKomComment" SG_ 779 DisOilLifeRst "Oil life packet";
BA_ "FlexKomIsMotorola" SG_ 779 DisOilLifeRst 1;
BA_ "FlexKomSID" SG_ 779 DisOilLifeRst 1668;
BA_ "FlexKomSigLaenge" SG_ 779 DisOilLifeRst 40;
BA_ "FlexKomSigName" SG_ 779 DisOilLifeRst "OilLifePkt";
BA_ "FlexKomSigStartPos" SG_ 779 DisOilLifeRst 7;
BA_ "FlexKomSigStartValue" SG_ 779 DisOilLifeRst "FFFFFF0FFFh";
BA_ "GenSigCycleTime" SG_ 779 DisOilLifeRst 1000;
BA_ "GenSigSNA" SG_ 779 DisOilLifeRst "FFFFh";
BA_ "GenSigStartValue" SG_ 779 DisOilLifeRst 65535;
BA_ "GenSigTimeout_CBC" SG_ 779 DisOilLifeRst 10500;
BA_ "GenSigTimeout_ETM" SG_ 779 DisOilLifeRst 10500;
BA_ "GenSigTimeout_IC" SG_ 779 DisOilLifeRst 10500;
BA_ "FlexKomComment" SG_ 779 FuelMM_Sts "Fuel maintenance mode status";
BA_ "FlexKomIsMotorola" SG_ 779 FuelMM_Sts 1;
BA_ "FlexKomSID" SG_ 779 FuelMM_Sts 2550;
BA_ "FlexKomSigLaenge" SG_ 779 FuelMM_Sts 8;
BA_ "FlexKomSigName" SG_ 779 FuelMM_Sts "FuelMM_Sts";
BA_ "FlexKomSigStartPos" SG_ 779 FuelMM_Sts 47;
BA_ "FlexKomSigStartValue" SG_ 779 FuelMM_Sts "00h";
BA_ "GenSigCycleTime" SG_ 779 FuelMM_Sts 1000;
BA_ "GenSigSNA" SG_ 779 FuelMM_Sts "0h";
BA_ "GenSigTimeout_IC" SG_ 779 FuelMM_Sts 10500;
BA_ "FlexKomComment" SG_ 779 HoursOilLifeRst "Oil life packet";
BA_ "FlexKomIsMotorola" SG_ 779 HoursOilLifeRst 1;
BA_ "FlexKomSID" SG_ 779 HoursOilLifeRst 1668;
BA_ "FlexKomSigLaenge" SG_ 779 HoursOilLifeRst 40;
BA_ "FlexKomSigName" SG_ 779 HoursOilLifeRst "OilLifePkt";
BA_ "FlexKomSigStartPos" SG_ 779 HoursOilLifeRst 7;
BA_ "FlexKomSigStartValue" SG_ 779 HoursOilLifeRst "FFFFFF0FFFh";
BA_ "GenSigCycleTime" SG_ 779 HoursOilLifeRst 1000;
BA_ "GenSigSNA" SG_ 779 HoursOilLifeRst "FFFh";
BA_ "GenSigStartValue" SG_ 779 HoursOilLifeRst 4095;
BA_ "GenSigTimeout_CBC" SG_ 779 HoursOilLifeRst 10500;
BA_ "GenSigTimeout_ETM" SG_ 779 HoursOilLifeRst 10500;
BA_ "GenSigTimeout_IC" SG_ 779 HoursOilLifeRst 10500;
BA_ "FlexKomComment" SG_ 779 MntncSts "Oil life packet";
BA_ "FlexKomIsMotorola" SG_ 779 MntncSts 1;
BA_ "FlexKomSID" SG_ 779 MntncSts 1668;
BA_ "FlexKomSigLaenge" SG_ 779 MntncSts 40;
BA_ "FlexKomSigName" SG_ 779 MntncSts "OilLifePkt";
BA_ "FlexKomSigStartPos" SG_ 779 MntncSts 7;
BA_ "FlexKomSigStartValue" SG_ 779 MntncSts "FFFFFF0FFFh";
BA_ "GenSigCycleTime" SG_ 779 MntncSts 1000;
BA_ "GenSigSNA" SG_ 779 MntncSts "3h";
BA_ "GenSigTimeout_ETM" SG_ 779 MntncSts 10500;
BA_ "GenSigTimeout_IC" SG_ 779 MntncSts 10500;
BA_ "FlexKomComment" SG_ 779 OilLifeLeft "Oil life packet";
BA_ "FlexKomIsMotorola" SG_ 779 OilLifeLeft 1;
BA_ "FlexKomSID" SG_ 779 OilLifeLeft 1668;
BA_ "FlexKomSigLaenge" SG_ 779 OilLifeLeft 40;
BA_ "FlexKomSigName" SG_ 779 OilLifeLeft "OilLifePkt";
BA_ "FlexKomSigStartPos" SG_ 779 OilLifeLeft 7;
BA_ "FlexKomSigStartValue" SG_ 779 OilLifeLeft "FFFFFF0FFFh";
BA_ "GenSigCycleTime" SG_ 779 OilLifeLeft 1000;
BA_ "GenSigSNA" SG_ 779 OilLifeLeft "FFh";
BA_ "GenSigStartValue" SG_ 779 OilLifeLeft 255;
BA_ "GenSigTimeout_ETM" SG_ 779 OilLifeLeft 10500;
BA_ "GenSigTimeout_IC" SG_ 779 OilLifeLeft 10500;
BA_ "FlexKomComment" SG_ 779 OilLifeLeftRst "Oil life packet";
BA_ "FlexKomIsMotorola" SG_ 779 OilLifeLeftRst 1;
BA_ "FlexKomSID" SG_ 779 OilLifeLeftRst 1668;
BA_ "FlexKomSigLaenge" SG_ 779 OilLifeLeftRst 40;
BA_ "FlexKomSigName" SG_ 779 OilLifeLeftRst "OilLifePkt";
BA_ "FlexKomSigStartPos" SG_ 779 OilLifeLeftRst 7;
BA_ "FlexKomSigStartValue" SG_ 779 OilLifeLeftRst "FFFFFF0FFFh";
BA_ "GenSigCycleTime" SG_ 779 OilLifeLeftRst 1000;
BA_ "GenSigSNA" SG_ 779 OilLifeLeftRst "0h";
BA_ "GenSigTimeout_ETM" SG_ 779 OilLifeLeftRst 10500;
BA_ "GenSigTimeout_IC" SG_ 779 OilLifeLeftRst 10500;
BA_ "RID" SG_ 779 OilLifeLeftRst "1619";
BA_ "FlexKomComment" SG_ 703 DrvAway_Alert "Drive Away Alert; True = [1]";
BA_ "FlexKomIsMotorola" SG_ 703 DrvAway_Alert 1;
BA_ "FlexKomSID" SG_ 703 DrvAway_Alert 2390;
BA_ "FlexKomSigLaenge" SG_ 703 DrvAway_Alert 1;
BA_ "FlexKomSigName" SG_ 703 DrvAway_Alert "DrvAway_Alert";
BA_ "FlexKomSigStartPos" SG_ 703 DrvAway_Alert 7;
BA_ "FlexKomSigStartValue" SG_ 703 DrvAway_Alert "00h";
BA_ "GenSigCycleTime" SG_ 703 DrvAway_Alert 100;
BA_ "GenSigSNA" SG_ 703 DrvAway_Alert "0h";
BA_ "GenSigTimeout_IC" SG_ 703 DrvAway_Alert 1050;
BA_ "FlexKomComment" SG_ 703 DrvAway_Inhibit "Drive Away Inhibit; True = [1]";
BA_ "FlexKomIsMotorola" SG_ 703 DrvAway_Inhibit 1;
BA_ "FlexKomSID" SG_ 703 DrvAway_Inhibit 2391;
BA_ "FlexKomSigLaenge" SG_ 703 DrvAway_Inhibit 1;
BA_ "FlexKomSigName" SG_ 703 DrvAway_Inhibit "DrvAway_Inhibit";
BA_ "FlexKomSigStartPos" SG_ 703 DrvAway_Inhibit 15;
BA_ "FlexKomSigStartValue" SG_ 703 DrvAway_Inhibit "00h";
BA_ "GenSigCycleTime" SG_ 703 DrvAway_Inhibit 100;
BA_ "GenSigSNA" SG_ 703 DrvAway_Inhibit "0h";
BA_ "GenSigTimeout_IC" SG_ 703 DrvAway_Inhibit 1050;
BA_ "FlexKomComment" SG_ 863 RevOilLifeRst "Engine revolutions since last oil life reset";
BA_ "FlexKomIsMotorola" SG_ 863 RevOilLifeRst 1;
BA_ "FlexKomSID" SG_ 863 RevOilLifeRst 2109;
BA_ "FlexKomSigLaenge" SG_ 863 RevOilLifeRst 16;
BA_ "FlexKomSigName" SG_ 863 RevOilLifeRst "RevOilLifeRst";
BA_ "FlexKomSigStartPos" SG_ 863 RevOilLifeRst 55;
BA_ "FlexKomSigStartValue" SG_ 863 RevOilLifeRst "FFFFh";
BA_ "GenSigCycleTime" SG_ 863 RevOilLifeRst 100;
BA_ "GenSigSNA" SG_ 863 RevOilLifeRst "FFFFh";
BA_ "GenSigStartValue" SG_ 863 RevOilLifeRst 65535;
BA_ "GenSigTimeout_CBC" SG_ 863 RevOilLifeRst 1050;
BA_ "FlexKomComment" SG_ 800 KeySense_DispReq "Key sense cluster EVIC request";
BA_ "FlexKomIsMotorola" SG_ 800 KeySense_DispReq 1;
BA_ "FlexKomSID" SG_ 800 KeySense_DispReq 2393;
BA_ "FlexKomSigLaenge" SG_ 800 KeySense_DispReq 2;
BA_ "FlexKomSigName" SG_ 800 KeySense_DispReq "KeySense_DispReq";
BA_ "FlexKomSigStartPos" SG_ 800 KeySense_DispReq 15;
BA_ "FlexKomSigStartValue" SG_ 800 KeySense_DispReq "00h";
BA_ "GenSigCycleTime" SG_ 800 KeySense_DispReq 100;
BA_ "GenSigSNA" SG_ 800 KeySense_DispReq "0h";
BA_ "GenSigTimeout_IC" SG_ 800 KeySense_DispReq 1050;
BA_ "FlexKomComment" SG_ 800 KeySense_SetSpdOpt "Key sense max speed option for ECM speed limiting";
BA_ "FlexKomIsMotorola" SG_ 800 KeySense_SetSpdOpt 1;
BA_ "FlexKomSID" SG_ 800 KeySense_SetSpdOpt 2394;
BA_ "FlexKomSigLaenge" SG_ 800 KeySense_SetSpdOpt 3;
BA_ "FlexKomSigName" SG_ 800 KeySense_SetSpdOpt "KeySense_SetSpdOpt";
BA_ "FlexKomSigStartPos" SG_ 800 KeySense_SetSpdOpt 2;
BA_ "FlexKomSigStartValue" SG_ 800 KeySense_SetSpdOpt "00h";
BA_ "GenSigCycleTime" SG_ 800 KeySense_SetSpdOpt 100;
BA_ "GenSigSNA" SG_ 800 KeySense_SetSpdOpt "7h";
BA_ "RID" SG_ 800 KeySense_SetSpdOpt "2192";
BA_ "FlexKomComment" SG_ 800 LeakCheckTimerValue "Requested leak test timer value";
BA_ "FlexKomIsMotorola" SG_ 800 LeakCheckTimerValue 1;
BA_ "FlexKomSID" SG_ 800 LeakCheckTimerValue 2575;
BA_ "FlexKomSigLaenge" SG_ 800 LeakCheckTimerValue 16;
BA_ "FlexKomSigName" SG_ 800 LeakCheckTimerValue "LeakCheckTimerValue";
BA_ "FlexKomSigStartPos" SG_ 800 LeakCheckTimerValue 15;
BA_ "FlexKomSigStartValue" SG_ 800 LeakCheckTimerValue "0000h";
BA_ "GenSigCycleTime" SG_ 800 LeakCheckTimerValue 100;
BA_ "GenSigSNA" SG_ 800 LeakCheckTimerValue "1FFh";
BA_ "FlexKomComment" SG_ 800 LeakTestRequest "Leak test is requested after powerdown; No request";
BA_ "FlexKomIsMotorola" SG_ 800 LeakTestRequest 1;
BA_ "FlexKomSID" SG_ 800 LeakTestRequest 2577;
BA_ "FlexKomSigLaenge" SG_ 800 LeakTestRequest 1;
BA_ "FlexKomSigName" SG_ 800 LeakTestRequest "LeakTestRequest";
BA_ "FlexKomSigStartPos" SG_ 800 LeakTestRequest 26;
BA_ "FlexKomSigStartValue" SG_ 800 LeakTestRequest "00h";
BA_ "GenSigCycleTime" SG_ 800 LeakTestRequest 100;
BA_ "GenSigSNA" SG_ 800 LeakTestRequest "0h";
BA_ "FlexKomComment" SG_ 800 LeakTestSts "Status of leak test";
BA_ "FlexKomIsMotorola" SG_ 800 LeakTestSts 1;
BA_ "FlexKomSID" SG_ 800 LeakTestSts 2576;
BA_ "FlexKomSigLaenge" SG_ 800 LeakTestSts 2;
BA_ "FlexKomSigName" SG_ 800 LeakTestSts "LeakTestSts";
BA_ "FlexKomSigStartPos" SG_ 800 LeakTestSts 28;
BA_ "FlexKomSigStartValue" SG_ 800 LeakTestSts "00h";
BA_ "GenSigCycleTime" SG_ 800 LeakTestSts 100;
BA_ "GenSigSNA" SG_ 800 LeakTestSts "0h";
BA_ "FlexKomComment" SG_ 800 RefuelEvent "Status of refuel event";
BA_ "FlexKomIsMotorola" SG_ 800 RefuelEvent 1;
BA_ "FlexKomSID" SG_ 800 RefuelEvent 2574;
BA_ "FlexKomSigLaenge" SG_ 800 RefuelEvent 3;
BA_ "FlexKomSigName" SG_ 800 RefuelEvent "RefuelEvent";
BA_ "FlexKomSigStartPos" SG_ 800 RefuelEvent 13;
BA_ "FlexKomSigStartValue" SG_ 800 RefuelEvent "00h";
BA_ "GenSigCycleTime" SG_ 800 RefuelEvent 100;
BA_ "GenSigSNA" SG_ 800 RefuelEvent "0h";
BA_ "FlexKomComment" SG_ 800 RefuelIndication "Indication to the driver about the status of the r";
BA_ "FlexKomIsMotorola" SG_ 800 RefuelIndication 1;
BA_ "FlexKomSID" SG_ 800 RefuelIndication 2578;
BA_ "FlexKomSigLaenge" SG_ 800 RefuelIndication 3;
BA_ "FlexKomSigName" SG_ 800 RefuelIndication "RefuelIndication";
BA_ "FlexKomSigStartPos" SG_ 800 RefuelIndication 31;
BA_ "FlexKomSigStartValue" SG_ 800 RefuelIndication "00h";
BA_ "GenSigCycleTime" SG_ 800 RefuelIndication 100;
BA_ "GenSigSNA" SG_ 800 RefuelIndication "0h";
BA_ "GenSigTimeout_IC" SG_ 800 RefuelIndication 1050;
BA_ "FlexKomComment" SG_ 308 BARO_ENG "General engine Data";
BA_ "FlexKomIsMotorola" SG_ 308 BARO_ENG 1;
BA_ "FlexKomSID" SG_ 308 BARO_ENG 1352;
BA_ "FlexKomSigLaenge" SG_ 308 BARO_ENG 48;
BA_ "FlexKomSigName" SG_ 308 BARO_ENG "Engine_1_Pkt";
BA_ "FlexKomSigStartPos" SG_ 308 BARO_ENG 23;
BA_ "FlexKomSigStartValue" SG_ 308 BARO_ENG "FF00FFFF00FFh";
BA_ "GenSigCycleTime" SG_ 308 BARO_ENG 20;
BA_ "GenSigSNA" SG_ 308 BARO_ENG "FFh";
BA_ "GenSigTimeout_IC" SG_ 308 BARO_ENG 210;
BA_ "FlexKomComment" SG_ 308 CRUISE_EGD "Cruise system is controlling speed";
BA_ "FlexKomIsMotorola" SG_ 308 CRUISE_EGD 1;
BA_ "FlexKomSID" SG_ 308 CRUISE_EGD 856;
BA_ "FlexKomSigLaenge" SG_ 308 CRUISE_EGD 1;
BA_ "FlexKomSigName" SG_ 308 CRUISE_EGD "CRUISE_EGD";
BA_ "FlexKomSigStartPos" SG_ 308 CRUISE_EGD 5;
BA_ "FlexKomSigStartValue" SG_ 308 CRUISE_EGD "00h";
BA_ "GenSigCycleTime" SG_ 308 CRUISE_EGD 20;
BA_ "GenSigSNA" SG_ 308 CRUISE_EGD "0h";
BA_ "GenSigTimeout_CBC" SG_ 308 CRUISE_EGD 210;
BA_ "GenSigTimeout_IC" SG_ 308 CRUISE_EGD 210;
BA_ "GenSigTimeout_ORC" SG_ 308 CRUISE_EGD 70;
BA_ "RID" SG_ 308 CRUISE_EGD "1101";
BA_ "FlexKomComment" SG_ 308 CRUISE_ON "Cruise control system 'on'";
BA_ "FlexKomIsMotorola" SG_ 308 CRUISE_ON 1;
BA_ "FlexKomSID" SG_ 308 CRUISE_ON 1250;
BA_ "FlexKomSigLaenge" SG_ 308 CRUISE_ON 1;
BA_ "FlexKomSigName" SG_ 308 CRUISE_ON "CRUISE_ON";
BA_ "FlexKomSigStartPos" SG_ 308 CRUISE_ON 7;
BA_ "FlexKomSigStartValue" SG_ 308 CRUISE_ON "00h";
BA_ "GenSigCycleTime" SG_ 308 CRUISE_ON 20;
BA_ "GenSigSNA" SG_ 308 CRUISE_ON "0h";
BA_ "GenSigTimeout_IC" SG_ 308 CRUISE_ON 210;
BA_ "GenSigTimeout_ORC" SG_ 308 CRUISE_ON 70;
BA_ "GenSigTimeout_SCCM" SG_ 308 CRUISE_ON 210;
BA_ "FlexKomComment" SG_ 308 MAP_ENG "General engine Data";
BA_ "FlexKomIsMotorola" SG_ 308 MAP_ENG 1;
BA_ "FlexKomSID" SG_ 308 MAP_ENG 1352;
BA_ "FlexKomSigLaenge" SG_ 308 MAP_ENG 48;
BA_ "FlexKomSigName" SG_ 308 MAP_ENG "Engine_1_Pkt";
BA_ "FlexKomSigStartPos" SG_ 308 MAP_ENG 23;
BA_ "FlexKomSigStartValue" SG_ 308 MAP_ENG "FF00FFFF00FFh";
BA_ "GenSigCycleTime" SG_ 308 MAP_ENG 20;
BA_ "GenSigSNA" SG_ 308 MAP_ENG "FFh";
BA_ "GenSigStartValue" SG_ 308 MAP_ENG 255;
BA_ "GenSigTimeout_ETM" SG_ 308 MAP_ENG 1010;
BA_ "FlexKomComment" SG_ 308 Rel_Pdl_ENG "General engine Data";
BA_ "FlexKomIsMotorola" SG_ 308 Rel_Pdl_ENG 1;
BA_ "FlexKomSID" SG_ 308 Rel_Pdl_ENG 1352;
BA_ "FlexKomSigLaenge" SG_ 308 Rel_Pdl_ENG 48;
BA_ "FlexKomSigName" SG_ 308 Rel_Pdl_ENG "Engine_1_Pkt";
BA_ "FlexKomSigStartPos" SG_ 308 Rel_Pdl_ENG 23;
BA_ "FlexKomSigStartValue" SG_ 308 Rel_Pdl_ENG "FF00FFFF00FFh";
BA_ "GenSigCycleTime" SG_ 308 Rel_Pdl_ENG 20;
BA_ "GenSigSNA" SG_ 308 Rel_Pdl_ENG "FFh";
BA_ "GenSigStartValue" SG_ 308 Rel_Pdl_ENG 255;
BA_ "FlexKomComment" SG_ 308 Rel_Thrt_ENG "General engine Data";
BA_ "FlexKomIsMotorola" SG_ 308 Rel_Thrt_ENG 1;
BA_ "FlexKomSID" SG_ 308 Rel_Thrt_ENG 1352;
BA_ "FlexKomSigLaenge" SG_ 308 Rel_Thrt_ENG 48;
BA_ "FlexKomSigName" SG_ 308 Rel_Thrt_ENG "Engine_1_Pkt";
BA_ "FlexKomSigStartPos" SG_ 308 Rel_Thrt_ENG 23;
BA_ "FlexKomSigStartValue" SG_ 308 Rel_Thrt_ENG "FF00FFFF00FFh";
BA_ "GenSigCycleTime" SG_ 308 Rel_Thrt_ENG 20;
BA_ "GenSigSNA" SG_ 308 Rel_Thrt_ENG "FFh";
BA_ "GenSigStartValue" SG_ 308 Rel_Thrt_ENG 255;
BA_ "FlexKomComment" SG_ 308 V_MAX_TM "Max. or cruise control set speed";
BA_ "FlexKomIsMotorola" SG_ 308 V_MAX_TM 1;
BA_ "FlexKomSID" SG_ 308 V_MAX_TM 1252;
BA_ "FlexKomSigLaenge" SG_ 308 V_MAX_TM 8;
BA_ "FlexKomSigName" SG_ 308 V_MAX_TM "V_MAX_TM";
BA_ "FlexKomSigStartPos" SG_ 308 V_MAX_TM 15;
BA_ "FlexKomSigStartValue" SG_ 308 V_MAX_TM "FFh";
BA_ "GenSigCycleTime" SG_ 308 V_MAX_TM 20;
BA_ "GenSigSNA" SG_ 308 V_MAX_TM "FFh";
BA_ "GenSigStartValue" SG_ 308 V_MAX_TM 255;
BA_ "FlexKomComment" SG_ 280 ANL_LFT "ECM_ENG_TRQ packet";
BA_ "FlexKomIsMotorola" SG_ 280 ANL_LFT 1;
BA_ "FlexKomSID" SG_ 280 ANL_LFT 1853;
BA_ "FlexKomSigLaenge" SG_ 280 ANL_LFT 64;
BA_ "FlexKomSigName" SG_ 280 ANL_LFT "ECM_ENG_TRQ_Pkt";
BA_ "FlexKomSigStartPos" SG_ 280 ANL_LFT 7;
BA_ "FlexKomSigStartValue" SG_ 280 ANL_LFT "9FFF1FFF1FFF00FFh";
BA_ "GenSigCycleTime" SG_ 280 ANL_LFT 10;
BA_ "GenSigSNA" SG_ 280 ANL_LFT "0h";
BA_ "GenSigTimeout_CBC" SG_ 280 ANL_LFT 105;
BA_ "FlexKomComment" SG_ 280 CRC_ECM_ENG_TRQ "ECM_ENG_TRQ packet";
BA_ "FlexKomIsMotorola" SG_ 280 CRC_ECM_ENG_TRQ 1;
BA_ "FlexKomSID" SG_ 280 CRC_ECM_ENG_TRQ 1853;
BA_ "FlexKomSigLaenge" SG_ 280 CRC_ECM_ENG_TRQ 64;
BA_ "FlexKomSigName" SG_ 280 CRC_ECM_ENG_TRQ "ECM_ENG_TRQ_Pkt";
BA_ "FlexKomSigStartPos" SG_ 280 CRC_ECM_ENG_TRQ 7;
BA_ "FlexKomSigStartValue" SG_ 280 CRC_ECM_ENG_TRQ "9FFF1FFF1FFF00FFh";
BA_ "GenSigCycleTime" SG_ 280 CRC_ECM_ENG_TRQ 10;
BA_ "GenSigSNA" SG_ 280 CRC_ECM_ENG_TRQ "FFh";
BA_ "GenSigStartValue" SG_ 280 CRC_ECM_ENG_TRQ 255;
BA_ "FlexKomComment" SG_ 280 MC_ECM_ENG_TRQ "ECM_ENG_TRQ packet";
BA_ "FlexKomIsMotorola" SG_ 280 MC_ECM_ENG_TRQ 1;
BA_ "FlexKomSID" SG_ 280 MC_ECM_ENG_TRQ 1853;
BA_ "FlexKomSigLaenge" SG_ 280 MC_ECM_ENG_TRQ 64;
BA_ "FlexKomSigName" SG_ 280 MC_ECM_ENG_TRQ "ECM_ENG_TRQ_Pkt";
BA_ "FlexKomSigStartPos" SG_ 280 MC_ECM_ENG_TRQ 7;
BA_ "FlexKomSigStartValue" SG_ 280 MC_ECM_ENG_TRQ "9FFF1FFF1FFF00FFh";
BA_ "GenSigCycleTime" SG_ 280 MC_ECM_ENG_TRQ 10;
BA_ "GenSigSNA" SG_ 280 MC_ECM_ENG_TRQ "0h";
BA_ "FlexKomComment" SG_ 280 StartRelayBCMCmd "ECM_ENG_TRQ packet";
BA_ "FlexKomIsMotorola" SG_ 280 StartRelayBCMCmd 1;
BA_ "FlexKomSID" SG_ 280 StartRelayBCMCmd 1853;
BA_ "FlexKomSigLaenge" SG_ 280 StartRelayBCMCmd 64;
BA_ "FlexKomSigName" SG_ 280 StartRelayBCMCmd "ECM_ENG_TRQ_Pkt";
BA_ "FlexKomSigStartPos" SG_ 280 StartRelayBCMCmd 7;
BA_ "FlexKomSigStartValue" SG_ 280 StartRelayBCMCmd "9FFF1FFF1FFF00FFh";
BA_ "GenSigCycleTime" SG_ 280 StartRelayBCMCmd 10;
BA_ "GenSigSNA" SG_ 280 StartRelayBCMCmd "0h";
BA_ "FlexKomComment" SG_ 290 GrMax_Rq_ECM "Target gear upper and lower limit";
BA_ "FlexKomIsMotorola" SG_ 290 GrMax_Rq_ECM 1;
BA_ "FlexKomSID" SG_ 290 GrMax_Rq_ECM 1243;
BA_ "FlexKomSigLaenge" SG_ 290 GrMax_Rq_ECM 6;
BA_ "FlexKomSigName" SG_ 290 GrMax_Rq_ECM "ECM_Gear";
BA_ "FlexKomSigStartPos" SG_ 290 GrMax_Rq_ECM 21;
BA_ "FlexKomSigStartValue" SG_ 290 GrMax_Rq_ECM "00h";
BA_ "GenSigCycleTime" SG_ 290 GrMax_Rq_ECM 20;
BA_ "GenSigSNA" SG_ 290 GrMax_Rq_ECM "0h";
BA_ "FlexKomComment" SG_ 290 NMOTS "Target idle speed";
BA_ "FlexKomIsMotorola" SG_ 290 NMOTS 1;
BA_ "FlexKomSID" SG_ 290 NMOTS 1248;
BA_ "FlexKomSigLaenge" SG_ 290 NMOTS 16;
BA_ "FlexKomSigName" SG_ 290 NMOTS "NMOTS";
BA_ "FlexKomSigStartPos" SG_ 290 NMOTS 39;
BA_ "FlexKomSigStartValue" SG_ 290 NMOTS "FFFFh";
BA_ "GenSigCycleTime" SG_ 290 NMOTS 20;
BA_ "GenSigSNA" SG_ 290 NMOTS "FFFFh";
BA_ "GenSigStartValue" SG_ 290 NMOTS 65535;
BA_ "FlexKomComment" SG_ 672 DefFuelEcon "Default fuel economy";
BA_ "FlexKomIsMotorola" SG_ 672 DefFuelEcon 1;
BA_ "FlexKomSID" SG_ 672 DefFuelEcon 709;
BA_ "FlexKomSigLaenge" SG_ 672 DefFuelEcon 8;
BA_ "FlexKomSigName" SG_ 672 DefFuelEcon "DefFuelEcon";
BA_ "FlexKomSigStartPos" SG_ 672 DefFuelEcon 55;
BA_ "FlexKomSigStartValue" SG_ 672 DefFuelEcon "FFh";
BA_ "GenSigCycleTime" SG_ 672 DefFuelEcon 100;
BA_ "GenSigSNA" SG_ 672 DefFuelEcon "FFh";
BA_ "GenSigStartValue" SG_ 672 DefFuelEcon 255;
BA_ "GenSigTimeout_IC" SG_ 672 DefFuelEcon 1050;
BA_ "FlexKomComment" SG_ 672 ETC_IND_LMP "ETC faulty, indicator lamp request";
BA_ "FlexKomIsMotorola" SG_ 672 ETC_IND_LMP 1;
BA_ "FlexKomSID" SG_ 672 ETC_IND_LMP 712;
BA_ "FlexKomSigLaenge" SG_ 672 ETC_IND_LMP 2;
BA_ "FlexKomSigName" SG_ 672 ETC_IND_LMP "ETC_IND_LMP";
BA_ "FlexKomSigStartPos" SG_ 672 ETC_IND_LMP 3;
BA_ "FlexKomSigStartValue" SG_ 672 ETC_IND_LMP "00h";
BA_ "GenSigCycleTime" SG_ 672 ETC_IND_LMP 100;
BA_ "GenSigSNA" SG_ 672 ETC_IND_LMP "3h";
BA_ "GenSigTimeout_ETM" SG_ 672 ETC_IND_LMP 1050;
BA_ "GenSigTimeout_IC" SG_ 672 ETC_IND_LMP 1050;
BA_ "FlexKomComment" SG_ 672 EngOilIndLmp_On_Rq "Request oil level/oil pressure indicator lamp";
BA_ "FlexKomIsMotorola" SG_ 672 EngOilIndLmp_On_Rq 1;
BA_ "FlexKomSID" SG_ 672 EngOilIndLmp_On_Rq 1080;
BA_ "FlexKomSigLaenge" SG_ 672 EngOilIndLmp_On_Rq 1;
BA_ "FlexKomSigName" SG_ 672 EngOilIndLmp_On_Rq "EngOilIndLmp_On_Rq";
BA_ "FlexKomSigStartPos" SG_ 672 EngOilIndLmp_On_Rq 10;
BA_ "FlexKomSigStartValue" SG_ 672 EngOilIndLmp_On_Rq "00h";
BA_ "GenSigCycleTime" SG_ 672 EngOilIndLmp_On_Rq 100;
BA_ "GenSigSNA" SG_ 672 EngOilIndLmp_On_Rq "1h";
BA_ "GenSigTimeout_ETM" SG_ 672 EngOilIndLmp_On_Rq 1050;
BA_ "GenSigTimeout_IC" SG_ 672 EngOilIndLmp_On_Rq 1050;
BA_ "FlexKomComment" SG_ 672 EngOilTemp "Oil temperature";
BA_ "FlexKomIsMotorola" SG_ 672 EngOilTemp 1;
BA_ "FlexKomSID" SG_ 672 EngOilTemp 440;
BA_ "FlexKomSigLaenge" SG_ 672 EngOilTemp 8;
BA_ "FlexKomSigName" SG_ 672 EngOilTemp "EngOilTemp";
BA_ "FlexKomSigStartPos" SG_ 672 EngOilTemp 31;
BA_ "FlexKomSigStartValue" SG_ 672 EngOilTemp "FFh";
BA_ "GenSigCycleTime" SG_ 672 EngOilTemp 100;
BA_ "GenSigSNA" SG_ 672 EngOilTemp "FFh";
BA_ "GenSigStartValue" SG_ 672 EngOilTemp 255;
BA_ "GenSigTimeout_CBC" SG_ 672 EngOilTemp 1050;
BA_ "GenSigTimeout_IC" SG_ 672 EngOilTemp 1050;
BA_ "RID" SG_ 672 EngOilTemp "1200";
BA_ "FlexKomComment" SG_ 672 EngRun_Stat "Engine running state";
BA_ "FlexKomIsMotorola" SG_ 672 EngRun_Stat 1;
BA_ "FlexKomSID" SG_ 672 EngRun_Stat 1081;
BA_ "FlexKomSigLaenge" SG_ 672 EngRun_Stat 3;
BA_ "FlexKomSigName" SG_ 672 EngRun_Stat "EngRun_Stat";
BA_ "FlexKomSigStartPos" SG_ 672 EngRun_Stat 58;
BA_ "FlexKomSigStartValue" SG_ 672 EngRun_Stat "07h";
BA_ "GenSigCycleTime" SG_ 672 EngRun_Stat 100;
BA_ "GenSigSNA" SG_ 672 EngRun_Stat "7h";
BA_ "GenSigStartValue" SG_ 672 EngRun_Stat 7;
BA_ "GenSigTimeout_CBC" SG_ 672 EngRun_Stat 1050;
BA_ "GenSigTimeout_IC" SG_ 672 EngRun_Stat 1050;
BA_ "RID" SG_ 672 EngRun_Stat "2093";
BA_ "FlexKomComment" SG_ 672 FuelCons "Fuel consumption";
BA_ "FlexKomIsMotorola" SG_ 672 FuelCons 1;
BA_ "FlexKomSID" SG_ 672 FuelCons 443;
BA_ "FlexKomSigLaenge" SG_ 672 FuelCons 16;
BA_ "FlexKomSigName" SG_ 672 FuelCons "FuelCons";
BA_ "FlexKomSigStartPos" SG_ 672 FuelCons 39;
BA_ "FlexKomSigStartValue" SG_ 672 FuelCons "FFFFh";
BA_ "GenSigCycleTime" SG_ 672 FuelCons 100;
BA_ "GenSigSNA" SG_ 672 FuelCons "FFFFh";
BA_ "GenSigStartValue" SG_ 672 FuelCons 65535;
BA_ "GenSigTimeout_CBC" SG_ 672 FuelCons 1050;
BA_ "GenSigTimeout_IC" SG_ 672 FuelCons 1050;
BA_ "RID" SG_ 672 FuelCons "1818";
BA_ "FlexKomComment" SG_ 672 MIL_IND_BLINK "Request MIL blink (OBD II)";
BA_ "FlexKomIsMotorola" SG_ 672 MIL_IND_BLINK 1;
BA_ "FlexKomSID" SG_ 672 MIL_IND_BLINK 713;
BA_ "FlexKomSigLaenge" SG_ 672 MIL_IND_BLINK 1;
BA_ "FlexKomSigName" SG_ 672 MIL_IND_BLINK "MIL_IND_BLINK";
BA_ "FlexKomSigStartPos" SG_ 672 MIL_IND_BLINK 1;
BA_ "FlexKomSigStartValue" SG_ 672 MIL_IND_BLINK "00h";
BA_ "GenSigCycleTime" SG_ 672 MIL_IND_BLINK 100;
BA_ "GenSigSNA" SG_ 672 MIL_IND_BLINK "0h";
BA_ "GenSigTimeout_IC" SG_ 672 MIL_IND_BLINK 1050;
BA_ "GenSigTimeout_ORC" SG_ 672 MIL_IND_BLINK 350;
BA_ "FlexKomComment" SG_ 672 MIL_OnRq "MIL on request from the engine";
BA_ "FlexKomIsMotorola" SG_ 672 MIL_OnRq 1;
BA_ "FlexKomSID" SG_ 672 MIL_OnRq 714;
BA_ "FlexKomSigLaenge" SG_ 672 MIL_OnRq 1;
BA_ "FlexKomSigName" SG_ 672 MIL_OnRq "MIL_OnRq";
BA_ "FlexKomSigStartValue" SG_ 672 MIL_OnRq "00h";
BA_ "GenSigCycleTime" SG_ 672 MIL_OnRq 100;
BA_ "GenSigSNA" SG_ 672 MIL_OnRq "0h";
BA_ "GenSigTimeout_IC" SG_ 672 MIL_OnRq 1050;
BA_ "GenSigTimeout_ORC" SG_ 672 MIL_OnRq 350;
BA_ "RID" SG_ 672 MIL_OnRq "1210";
BA_ "FlexKomComment" SG_ 672 OIL_IND_LMP_FLSH "Oil indicator lamp flash (for in plant use)";
BA_ "FlexKomIsMotorola" SG_ 672 OIL_IND_LMP_FLSH 1;
BA_ "FlexKomSID" SG_ 672 OIL_IND_LMP_FLSH 716;
BA_ "FlexKomSigLaenge" SG_ 672 OIL_IND_LMP_FLSH 1;
BA_ "FlexKomSigName" SG_ 672 OIL_IND_LMP_FLSH "OIL_IND_LMP_FLSH";
BA_ "FlexKomSigStartPos" SG_ 672 OIL_IND_LMP_FLSH 8;
BA_ "FlexKomSigStartValue" SG_ 672 OIL_IND_LMP_FLSH "00h";
BA_ "GenSigCycleTime" SG_ 672 OIL_IND_LMP_FLSH 100;
BA_ "GenSigSNA" SG_ 672 OIL_IND_LMP_FLSH "0h";
BA_ "GenSigTimeout_IC" SG_ 672 OIL_IND_LMP_FLSH 1050;
BA_ "FlexKomComment" SG_ 672 OIL_PRESS "Oil pressure";
BA_ "FlexKomIsMotorola" SG_ 672 OIL_PRESS 1;
BA_ "FlexKomSID" SG_ 672 OIL_PRESS 717;
BA_ "FlexKomSigLaenge" SG_ 672 OIL_PRESS 8;
BA_ "FlexKomSigName" SG_ 672 OIL_PRESS "OIL_PRESS";
BA_ "FlexKomSigStartPos" SG_ 672 OIL_PRESS 23;
BA_ "FlexKomSigStartValue" SG_ 672 OIL_PRESS "FFh";
BA_ "GenSigCycleTime" SG_ 672 OIL_PRESS 100;
BA_ "GenSigSNA" SG_ 672 OIL_PRESS "FFh";
BA_ "GenSigStartValue" SG_ 672 OIL_PRESS 255;
BA_ "GenSigTimeout_CBC" SG_ 672 OIL_PRESS 1050;
BA_ "GenSigTimeout_IC" SG_ 672 OIL_PRESS 1050;
BA_ "RID" SG_ 672 OIL_PRESS "1183";
BA_ "FlexKomComment" SG_ 672 OIL_TEMP_CHM_RQ "Engine oil overtemp. indicator/chime request";
BA_ "FlexKomIsMotorola" SG_ 672 OIL_TEMP_CHM_RQ 1;
BA_ "FlexKomSID" SG_ 672 OIL_TEMP_CHM_RQ 718;
BA_ "FlexKomSigLaenge" SG_ 672 OIL_TEMP_CHM_RQ 4;
BA_ "FlexKomSigName" SG_ 672 OIL_TEMP_CHM_RQ "OIL_TEMP_RQ";
BA_ "FlexKomSigStartPos" SG_ 672 OIL_TEMP_CHM_RQ 14;
BA_ "FlexKomSigStartValue" SG_ 672 OIL_TEMP_CHM_RQ "00h";
BA_ "GenSigCycleTime" SG_ 672 OIL_TEMP_CHM_RQ 100;
BA_ "GenSigSNA" SG_ 672 OIL_TEMP_CHM_RQ "0h";
BA_ "GenSigTimeout_IC" SG_ 672 OIL_TEMP_CHM_RQ 1050;
BA_ "FlexKomComment" SG_ 672 OIL_TEMP_IND_RQ "Engine oil overtemp. indicator/chime request";
BA_ "FlexKomIsMotorola" SG_ 672 OIL_TEMP_IND_RQ 1;
BA_ "FlexKomSID" SG_ 672 OIL_TEMP_IND_RQ 718;
BA_ "FlexKomSigLaenge" SG_ 672 OIL_TEMP_IND_RQ 4;
BA_ "FlexKomSigName" SG_ 672 OIL_TEMP_IND_RQ "OIL_TEMP_RQ";
BA_ "FlexKomSigStartPos" SG_ 672 OIL_TEMP_IND_RQ 14;
BA_ "FlexKomSigStartValue" SG_ 672 OIL_TEMP_IND_RQ "00h";
BA_ "GenSigCycleTime" SG_ 672 OIL_TEMP_IND_RQ 100;
BA_ "GenSigSNA" SG_ 672 OIL_TEMP_IND_RQ "3h";
BA_ "GenSigTimeout_ETM" SG_ 672 OIL_TEMP_IND_RQ 1050;
BA_ "GenSigTimeout_IC" SG_ 672 OIL_TEMP_IND_RQ 1050;
BA_ "FlexKomComment" SG_ 257 AccelPdlPosn_OBD "Pedal value for OBD (ISO 15031-5.4 PID 49)";
BA_ "FlexKomIsMotorola" SG_ 257 AccelPdlPosn_OBD 1;
BA_ "FlexKomSID" SG_ 257 AccelPdlPosn_OBD 1089;
BA_ "FlexKomSigLaenge" SG_ 257 AccelPdlPosn_OBD 8;
BA_ "FlexKomSigName" SG_ 257 AccelPdlPosn_OBD "AccelPdlPosn_OBD";
BA_ "FlexKomSigStartPos" SG_ 257 AccelPdlPosn_OBD 31;
BA_ "FlexKomSigStartValue" SG_ 257 AccelPdlPosn_OBD "00h";
BA_ "GenSigCycleTime" SG_ 257 AccelPdlPosn_OBD 100;
BA_ "GenSigSNA" SG_ 257 AccelPdlPosn_OBD "0h";
BA_ "FlexKomComment" SG_ 257 CARB_PERM "CARB permanent fault code drive cycle";
BA_ "FlexKomIsMotorola" SG_ 257 CARB_PERM 1;
BA_ "FlexKomSID" SG_ 257 CARB_PERM 1258;
BA_ "FlexKomSigLaenge" SG_ 257 CARB_PERM 1;
BA_ "FlexKomSigName" SG_ 257 CARB_PERM "CARB_PERM";
BA_ "FlexKomSigStartPos" SG_ 257 CARB_PERM 3;
BA_ "FlexKomSigStartValue" SG_ 257 CARB_PERM "00h";
BA_ "GenSigCycleTime" SG_ 257 CARB_PERM 100;
BA_ "GenSigSNA" SG_ 257 CARB_PERM "0h";
BA_ "FlexKomComment" SG_ 257 CARB_Temp "CARB warmup criteria is true [1]";
BA_ "FlexKomIsMotorola" SG_ 257 CARB_Temp 1;
BA_ "FlexKomSID" SG_ 257 CARB_Temp 1261;
BA_ "FlexKomSigLaenge" SG_ 257 CARB_Temp 1;
BA_ "FlexKomSigName" SG_ 257 CARB_Temp "CARB_Temp";
BA_ "FlexKomSigStartValue" SG_ 257 CARB_Temp "00h";
BA_ "GenSigCycleTime" SG_ 257 CARB_Temp 100;
BA_ "GenSigSNA" SG_ 257 CARB_Temp "0h";
BA_ "FlexKomComment" SG_ 257 ECM_SKIM_STAT "ECM Immobilizer Status Packet";
BA_ "FlexKomIsMotorola" SG_ 257 ECM_SKIM_STAT 1;
BA_ "FlexKomSID" SG_ 257 ECM_SKIM_STAT 429;
BA_ "FlexKomSigLaenge" SG_ 257 ECM_SKIM_STAT 3;
BA_ "FlexKomSigName" SG_ 257 ECM_SKIM_STAT "ECM_SKIM_STAT_PKT";
BA_ "FlexKomSigStartPos" SG_ 257 ECM_SKIM_STAT 10;
BA_ "FlexKomSigStartValue" SG_ 257 ECM_SKIM_STAT "00h";
BA_ "GenSigCycleTime" SG_ 257 ECM_SKIM_STAT 100;
BA_ "GenSigSNA" SG_ 257 ECM_SKIM_STAT "3h";
BA_ "FlexKomComment" SG_ 257 ENGINE_RESET "ECM Immobilizer Status Packet";
BA_ "FlexKomIsMotorola" SG_ 257 ENGINE_RESET 1;
BA_ "FlexKomSID" SG_ 257 ENGINE_RESET 429;
BA_ "FlexKomSigLaenge" SG_ 257 ENGINE_RESET 3;
BA_ "FlexKomSigName" SG_ 257 ENGINE_RESET "ECM_SKIM_STAT_PKT";
BA_ "FlexKomSigStartPos" SG_ 257 ENGINE_RESET 10;
BA_ "FlexKomSigStartValue" SG_ 257 ENGINE_RESET "00h";
BA_ "GenSigCycleTime" SG_ 257 ENGINE_RESET 100;
BA_ "GenSigSNA" SG_ 257 ENGINE_RESET "0h";
BA_ "FlexKomComment" SG_ 257 EngLoad_OBD "Load value for OBD (ISO 15031-5.4 PID 4)";
BA_ "FlexKomIsMotorola" SG_ 257 EngLoad_OBD 1;
BA_ "FlexKomSID" SG_ 257 EngLoad_OBD 1088;
BA_ "FlexKomSigLaenge" SG_ 257 EngLoad_OBD 8;
BA_ "FlexKomSigName" SG_ 257 EngLoad_OBD "EngLoad_OBD";
BA_ "FlexKomSigStartPos" SG_ 257 EngLoad_OBD 23;
BA_ "FlexKomSigStartValue" SG_ 257 EngLoad_OBD "00h";
BA_ "GenSigCycleTime" SG_ 257 EngLoad_OBD 100;
BA_ "GenSigSNA" SG_ 257 EngLoad_OBD "0h";
BA_ "FlexKomComment" SG_ 257 IgnCntrTrue "Ignition cycle counter is true [1]";
BA_ "FlexKomIsMotorola" SG_ 257 IgnCntrTrue 1;
BA_ "FlexKomSID" SG_ 257 IgnCntrTrue 1255;
BA_ "FlexKomSigLaenge" SG_ 257 IgnCntrTrue 1;
BA_ "FlexKomSigName" SG_ 257 IgnCntrTrue "IgnCntrTrue";
BA_ "FlexKomSigStartPos" SG_ 257 IgnCntrTrue 6;
BA_ "FlexKomSigStartValue" SG_ 257 IgnCntrTrue "00h";
BA_ "GenSigCycleTime" SG_ 257 IgnCntrTrue 100;
BA_ "GenSigSNA" SG_ 257 IgnCntrTrue "0h";
BA_ "FlexKomComment" SG_ 257 InpICC_Fail "Inputs to the Ign Cycle Cntr are in a Pend or MIL ";
BA_ "FlexKomIsMotorola" SG_ 257 InpICC_Fail 1;
BA_ "FlexKomSID" SG_ 257 InpICC_Fail 1259;
BA_ "FlexKomSigLaenge" SG_ 257 InpICC_Fail 1;
BA_ "FlexKomSigName" SG_ 257 InpICC_Fail "InpICC_Fail";
BA_ "FlexKomSigStartPos" SG_ 257 InpICC_Fail 2;
BA_ "FlexKomSigStartValue" SG_ 257 InpICC_Fail "00h";
BA_ "GenSigCycleTime" SG_ 257 InpICC_Fail 100;
BA_ "GenSigSNA" SG_ 257 InpICC_Fail "0h";
BA_ "FlexKomComment" SG_ 257 Inp_GD_Fail "Inputs to the general denominator are in a pend or";
BA_ "FlexKomIsMotorola" SG_ 257 Inp_GD_Fail 1;
BA_ "FlexKomSID" SG_ 257 Inp_GD_Fail 1260;
BA_ "FlexKomSigLaenge" SG_ 257 Inp_GD_Fail 1;
BA_ "FlexKomSigName" SG_ 257 Inp_GD_Fail "Inp_GD_Fail";
BA_ "FlexKomSigStartPos" SG_ 257 Inp_GD_Fail 1;
BA_ "FlexKomSigStartValue" SG_ 257 Inp_GD_Fail "00h";
BA_ "GenSigCycleTime" SG_ 257 Inp_GD_Fail 100;
BA_ "GenSigSNA" SG_ 257 Inp_GD_Fail "0h";
BA_ "FlexKomComment" SG_ 257 OBD_GnrlDenCond_Stat "General denominator conditions are met [1].";
BA_ "FlexKomIsMotorola" SG_ 257 OBD_GnrlDenCond_Stat 1;
BA_ "FlexKomSID" SG_ 257 OBD_GnrlDenCond_Stat 1256;
BA_ "FlexKomSigLaenge" SG_ 257 OBD_GnrlDenCond_Stat 1;
BA_ "FlexKomSigName" SG_ 257 OBD_GnrlDenCond_Stat "OBD_GnrlDenCond_Stat";
BA_ "FlexKomSigStartPos" SG_ 257 OBD_GnrlDenCond_Stat 5;
BA_ "FlexKomSigStartValue" SG_ 257 OBD_GnrlDenCond_Stat "00h";
BA_ "GenSigCycleTime" SG_ 257 OBD_GnrlDenCond_Stat 100;
BA_ "GenSigSNA" SG_ 257 OBD_GnrlDenCond_Stat "0h";
BA_ "FlexKomComment" SG_ 257 RAD_FAN1_STAT "Low speed or single radiator fan requested duty cy";
BA_ "FlexKomIsMotorola" SG_ 257 RAD_FAN1_STAT 1;
BA_ "FlexKomSID" SG_ 257 RAD_FAN1_STAT 1091;
BA_ "FlexKomSigLaenge" SG_ 257 RAD_FAN1_STAT 8;
BA_ "FlexKomSigName" SG_ 257 RAD_FAN1_STAT "RAD_FAN1_STAT";
BA_ "FlexKomSigStartPos" SG_ 257 RAD_FAN1_STAT 39;
BA_ "FlexKomSigStartValue" SG_ 257 RAD_FAN1_STAT "00h";
BA_ "GenSigCycleTime" SG_ 257 RAD_FAN1_STAT 100;
BA_ "GenSigSNA" SG_ 257 RAD_FAN1_STAT "FFh";
BA_ "GenSigTimeout_ETM" SG_ 257 RAD_FAN1_STAT 1050;
VAL_ 624 EngineOffTimer 4095 "SNA" ;
VAL_ 624 Gate_Req_PE 0 "NO_REQ" 1 "HNDL_PE_REQ" 2 "BTN_PE_REQ" 3 "HF_PE_REQ" ;
VAL_ 624 L_R_Req_PE 0 "NO_REQ" 1 "HNDL_PE_REQ" 2 "BTN_PE_REQ" 3 "HF_PE_REQ" ;
VAL_ 624 R_R_Req_PE 0 "NO_REQ" 1 "HNDL_PE_REQ" 2 "BTN_PE_REQ" 3 "HF_PE_REQ" ;
VAL_ 456 VTA_STAT 0 "VTA_DISARM" 1 "VTA_PREARM" 2 "VTA_ARM" 3 "VTA_LGT" 4 "VTA_LGT_HORN" 5 "VTA_TAMP" 6 "VTA_ITM_Alarm" 7 "SNA" ;
VAL_ 788 CFG_FEATURE 0 "CFG_NONE" 1 "CFG_AUTO_LK" 2 "CFG_AUTO_UNLK" 3 "CFG_DLY_LK" 4 "CFG_DRV_FST" 5 "CFG_SOUND_LK" 6 "CFG_HORN_DUR" 7 "CFG_FLASH_LK" 8 "CFG_DrAlrPrsnt" 9 "CFG_PARK_ASSIST" 10 "CFG_LANG" 11 "CFG_US_METRIC" 12 "CFG_SRV_INTV" 13 "CFG_AUTO_WPR" 14 "CFG_HL_DLY" 15 "CFG_HL_WPR" 16 "CFG_ACC_DLY" 18 "CFG_REM_MEM" 19 "CFG_EASY_EXIT" 20 "CFG_LO_VEH" 21 "CFG_TILT_IN_REV" 22 "CFG_ILL_APRCH" 23 "CFG_ILL_ENTRY" 24 "CFG_GLBL_UP_WIN" 25 "CFG_GLBL_DN_WIN" 26 "CFG_DRL_ON" 27 "CFG_AHB" 28 "REST_FACT_DEF" 29 "CFG_CMP_CAL" 30 "CFG_CMP_VAR" 31 "CFG_VOICE_COMF" 32 "CFG_NAV_TBYT" 33 "CFG_HILL_ST" 34 "CFG_AFS" 35 "CFG_BSD" 36 "CFG_PE" 37 "CFG_WAL" 38 "CFG_DSS" 39 "CFG_SOUND_RS" 40 "CFG_DCS" 41 "CFG_AUTO_RELK" 42 "CFG_CMS" 43 "CFG_FCW" 44 "CFG_PRE_SAFE" 45 "CFG_BELT_SLAK" 46 "CFG_FUEL_SAV" 47 "CFG_FCW_SENS" 48 "CFG_HDLP_DROP" 49 "CFG_ECMM" 50 "PASS_WIN_LKOUT" 51 "AERO" 52 "JACK" 53 "CFG_TRLR" 54 "CFG_ALIGNMENT" 55 "CFG_ASCM_WMO" 57 "CFG_LDW" 58 "OIL" 59 "CFG_NORMAL_DCS" 61 "CFG_TRANSPORT" 62 "CFG_PTO_MODE" 63 "CFG_PTO_SINGLE_RPM" 64 "CFG_PTO_RPM1" 65 "CFG_PTO_RPM2" 66 "CFG_PTO_RPM3" 67 "CFG_PTO_Type" 68 "CFG_PTO_Auto_Resume" 69 "CFG_MAX_PTO_VEH_SPEED" 70 "RVC_GRID" 71 "DIMMER" 72 "RLE_LIGHT" 73 "RLE_HORN" 76 "CFG_TRLR_TYP" 77 "CFG_TRLR_NAME" 81 "CFG_PTS_FT" 82 "CFG_PTS_RR" 83 "CFG_PTS_FT_VOL" 84 "CFG_PTS_RR_VOL" 86 "CFG_PLG" 87 "CFG_AUX1" 88 "CFG_AUX2" 89 "CFG_AUX3" 90 "CFG_AUX4" 91 "CFG_AUX5" 93 "CFG_LDWTRQ" 94 "CFG_PTO_REM_Throttle" 95 "CFG_UNIT_DEFAULT" 96 "CFG_PressureUnit" 97 "CFG_SpeedUnit" 98 "CFG_DistanceUnit" 99 "CFG_ConsumptionUnit" 100 "CFG_CapacityUnit" 101 "CFG_TemperatureUnit" 102 "CFG_PowerUnit" 103 "CFG_TorqueUnit" 104 "CFG_EPS" 105 "CFG_CHMSL_LINES" 106 "CFG_POLICE_PE" 107 "EPB_AUTO_PRK" 108 "EPB_SERVICE" 109 "HOLD_N_GO" 110 "PWR_FLD_MRR" 111 "HANDS_FREE_LFT" 112 "HANDS_FREE_SLDR" 113 "SVC_GRIDLINES" 114 "SVC_DELAY" 115 "SLD_DR_ALRT" 116 "TEEN_FCW_SENS" 117 "TEEN_FCW_BRK" 118 "TEEN_PRK_ASST" 119 "TEEN_PRK_ASST_BRK" 120 "TEEN_FT_PRK_VOL" 121 "TEEN_RR_PRK_VOL" 122 "TEEN_MAX_SPEED" 123 "TEEN_FUEL_WRN" 124 "TEEN_FUEL_POPUP" 125 "TEEN_BLIND_SPOT" 126 "TEEN_RAIN_WPR" 127 "TEEN_AUTO_HB" 128 "TEEN_LGHT_WPR" 129 "TEEN_SLD_DR_ALRT" 130 "TEEN_PLG_CHIME" 131 "SLD_DR_CHM" 132 "TEEN_SLD_DR_CHM" 133 "CFG_ABSM" 134 "CFG_PADDLE_SHIFT" 137 "CFG_PRK_ASST_BRK" 138 "CFG_LDW_ON" 139 "CFG_PRK_ASST_TYPE" 140 "CFG_DR_ALR" 141 "CFG_RDY_DRV" 142 "CFG_PANEL_INTS" 143 "CFG_MOOD_LGT_INTS" 144 "CFG_ML_HDLP_LVL" 145 "CFG_BSM_TRLR" 146 "CFG_AUTO_SS" 147 "CFG_PCS" 148 "CFG_UNIT_SET" 149 "CFG_DOORS_OFF_ACC_DLY" 150 "CFG_MOTORIZED_SEATBELT" 151 "CFG_MOTORIZED_SEATBELT_STRN" 152 "CFG_TSI" 153 "CFG_LKA" 154 "CFG_LKA_SENS" 155 "CFG_LKA_STRN" 156 "CFG_ABSD" 157 "CFG_ABSD_SENS" 158 "CFG_ABSD_STRN" 162 "CFG_TIRE_FILL_ALERT" 163 "CFG_POWER_SIDE_STEP" 164 "CFG_AUTO_STOP_START" ;
VAL_ 788 CFG_STAT_RQ 0 "CFG_DEF" 1 "CFG_DSBL" 2 "CFG_ENBL" 3 "CFG_SPEC" ;
VAL_ 856 CMP_DIR 0 "CMP_N" 1 "CMP_N_E" 2 "CMP_E" 3 "CMP_S_E" 4 "CMP_S" 5 "CMP_S_W" 6 "CMP_W" 7 "CMP_N_W" 8 "NONE" 15 "SNA" ;
VAL_ 848 DateTmDay 255 "SNA" ;
VAL_ 848 DateTmFormat 0 "NDEF0" 1 "FORMAT_12H" 2 "FORMAT_24H" 3 "FORMAT_0" 4 "FORMAT_1" 5 "FORMAT_2" 6 "FORMAT_3" 7 "SNA" ;
VAL_ 848 DateTmHour 255 "SNA" ;
VAL_ 848 DateTmMinute 255 "SNA" ;
VAL_ 848 DateTmMonth 255 "SNA" ;
VAL_ 848 DateTmSec 255 "SNA" ;
VAL_ 848 DateTmYear 65535 "SNA" ;
VAL_ 500 As_DispRq 0 "No_RQ" 1 "ACC" 2 "FCW" 3 "SNA" ;
VAL_ 500 DAS_ACCEL_Rq 4095 "SNA" ;
VAL_ 500 DAS_Rq_ID 0 "IDLE" 1 "ACC" 2 "CMS" 3 "ABA" 4 "LSCM" 5 "CMS_XTD" 6 "PEB" 7 "SNA" ;
VAL_ 500 DAS_Sts 0 "OK" 1 "INTERNAL" 2 "EXTERNAL" 3 "SNA" ;
VAL_ 499 LFC_Request_Type 0 "No Request" 1 "Brake Torque Request" 2 "Standstill Hold Request" 3 "RHSC_Override" ;
VAL_ 499 RHSC_OpenLoopBraking_Rq 0 "False" 1 "True" ;
VAL_ 499 SDS_Engaged_State 0 "Disengaged" 1 "Engaged_with_Driver" 2 "Engaged_Driverless" 3 "SNA" ;
VAL_ 501 ACCOnOff 0 "OFF" 1 "NCC" 2 "NCC_SET" 3 "ACC_ON" 4 "ACC_SET" 7 "SNA" ;
VAL_ 501 FCW_Error 0 "No_Error" 1 "FCW_Error" 2 "Limited_FCW" 3 "SNA" ;
VAL_ 501 HMI_Screens 255 "SNA" ;
VAL_ 501 ObjIntrstDist 255 "SNA" ;
VAL_ 501 SetSpeed_KPH 255 "SNA" ;
VAL_ 501 SetSpeed_MPH 255 "SNA" ;
VAL_ 501 Sm_ICON_Dspl 0 "NONE" 1 "OFF" 2 "READY_TG1" 3 "READY_TG2" 4 "READY_TG3" 5 "READY_TG4" 8 "ACC_E_NT_TG1" 9 "ACC_E_NT_TG2" 10 "ACC_E_NT_TG3" 11 "ACC_E_NT_TG4" 12 "ACC_E_WT_TG1" 13 "ACC_E_WT_TG2" 14 "ACC_E_WT_TG3" 15 "ACC_E_WT_TG4" 33 "NCC_OFF" 34 "NCC_READY" 40 "NCC_ENGAGED" 63 "SNA" ;
VAL_ 625 FCWSetting 0 "OFF" 1 "NEAR" 2 "MEDIUM" 3 "FAR" ;
VAL_ 625 FCWSettingTeen 0 "OFF" 1 "NEAR" 2 "MEDIUM" 3 "FAR" ;
VAL_ 625 SDS_Engaged_State 0 "Disengaged" 1 "Engaged_with_Driver" 2 "Engaged_Driverless" 3 "SNA" ;
VAL_ 625 WhlTrqRq_DAS 32767 "SNA" ;
VAL_ 860 DIST_TO_TURN 65535 "SNA" ;
VAL_ 860 NAV_ARROW 0 "NAV_NOT_ACT" ;
VAL_ 860 UNITS 0 "NO_UNITS" 1 "MILE" 2 "FEET" 3 "KM" 4 "METER" 5 "YARD" 7 "SNA" ;
VAL_ 653 BrakePedalTravelSensor 255 "SNA" ;
VAL_ 653 BrakeSysStateSec 0 "BrkSysSec_Off" 1 "BrkSysSec_Unavailable" 2 "BrkSysSec_FailedDegraded" 3 "BrkSysSec_FailedOperational" 4 "BrkSysSec_FullSystem" 5 "BrkSysSec_EmergencyMode" 7 "SNA" ;
VAL_ 653 BrkPdl_Stat_2 0 "UPSTOP" 1 "PSD" 2 "NDEF2" 3 "SNA" ;
VAL_ 653 Brk_Stat_2 0 "IDLE" 1 "BRAKING" 2 "NDEF2" 3 "SNA" ;
VAL_ 653 DAS_RqActv 0 "IDLE" 1 "LFC" 2 "CMS" 3 "ABA" 4 "LSCM" 5 "VJC_Open_Loop" 6 "RHSC_Override" 7 "SNA" ;
VAL_ 653 EBCM_BrakeState 0 "EBCM_Off" 1 "EBCM_Unavailable" 2 "EBCM_FailedDegraded" 3 "EBCM_FailedOperational" 4 "EBCM_FullSystem" 5 "EBCM_EmergencyMode" 7 "SNA" ;
VAL_ 653 SDS_Engaged_State_EBCM 0 "Disengaged" 1 "Engaged_with_Driver" 2 "Engaged_Driverless" 3 "SNA" ;
VAL_ 264 ECM_IMMO_STAT_CANC 0 "IS" 1 "KILL" 2 "RUN" 3 "SNA" ;
VAL_ 264 EngRPM 65535 "SNA" ;
VAL_ 288 AccelPdlPosn 255 "SNA" ;
VAL_ 760 ESS_ENG_ST 1 "ENS_STOPPED" 2 "ENS_RQ_ST" 3 "ENS_RUN" 4 "ENS_STOP_PEND" 5 "ENS_ST_PRTCT" 6 "ENS_ST_INH" 7 "ENS_DSBL" 8 "ENS_IHB_LATCH" 9 "ENS_STARTING" 10 "KEY_START" 15 "SNA" ;
VAL_ 559 ActlAccelPdlPosn 255 "SNA" ;
VAL_ 632 CC_SetSpdDspl 255 "SNA" ;
VAL_ 632 CC_SetSpdDsplMPH 255 "SNA" ;
VAL_ 632 SpStDispstat 0 "NONE" 1 "STARTING" 2 "START" 3 "ACTIVE" 4 "D_OR_SB" 5 "NR_DRV_NOT_DET" 6 "DR_INHIB" 7 "TX_INHIB" 8 "KEY" 9 "BATT" 10 "SYSFLT" 11 "NR" 12 "READY" 13 "OFF" 14 "HOOD" 15 "PEDAL" 16 "BATT_CHG" 17 "TM" 18 "T4WD_L" 19 "LF" 20 "INCLINE" 21 "AMB_TEMP" 22 "ENG_TEMP" 23 "SB" 24 "DR_AJAR" 25 "CABIN" 26 "MAX_HVAC" 27 "FT_DEFROST" 28 "EBL" 29 "ST_WHEEL" 30 "Eng_Temp_Hi" 31 "Eng_Temp_Lo" 32 "Prk_Brk_Inhib" 33 "Park_Inhib" 34 "Hood_Inhib" 35 "DPF_Regen" 36 "PSG_DR_INHIB" 37 "ACC_SET" 38 "BATT_HIGH" 39 "OFF_ROAD1" 40 "OFF_ROAD2" 63 "SNA" ;
VAL_ 632 SpStSwStat 0 "OFF" 1 "CONT" 2 "BLINK" 3 "SNA" ;
VAL_ 632 SpStWarnStat 0 "NONE" 1 "PCR_Opens" 2 "START" 3 "ACTIVE" 4 "D_OR_SB" 5 "NR_DRV_NOT_DET" 6 "DR_INHIB" 7 "TX_INHIB" 8 "KEY" 9 "BATT" 10 "SYSFLT" 11 "Prk_Brk_Inhib" 12 "Hood_Inhib" 13 "PSG_DR_INHIB" 14 "Park_Inhib" 15 "SNA" ;
VAL_ 384 AM_ECM_Prsnt 0 "DEFAULT" 2 "AM_ECM_PRSNT" 3 "SNA" ;
VAL_ 384 AirPress_Outsd 255 "SNA" ;
VAL_ 384 CHRG_FAIL 1 "SNA" ;
VAL_ 384 EngCoolTemp 255 "SNA" ;
VAL_ 384 IntkAirTemp 255 "SNA" ;
VAL_ 384 SysVolt 255 "SNA" ;
VAL_ 779 DisOilLifeRst 65535 "SNA" ;
VAL_ 779 FuelMM_Sts 0 "INACTIVE" 1 "ACTIVE" 2 "DISABLED" ;
VAL_ 779 HoursOilLifeRst 4095 "SNA" ;
VAL_ 779 MntncSts 0 "NONE" 1 "SOON" 2 "NOW" 3 "SNA" ;
VAL_ 779 OilLifeLeft 255 "SNA" ;
VAL_ 863 RevOilLifeRst 65535 "SNA" ;
VAL_ 800 KeySense_DispReq 0 "NONE" 1 "WARN" 2 "SPD_LMT" ;
VAL_ 800 KeySense_SetSpdOpt 0 "NOT_PROG" 1 "OPT_1" 2 "OPT_2" 3 "OPT_3" 4 "OPT_4" 5 "OPT_5" 7 "SNA" ;
VAL_ 800 LeakCheckTimerValue 511 "SNA" ;
VAL_ 800 LeakTestSts 0 "NONE" 1 "PEND" 2 "COMPLETE" 3 "DELAY" ;
VAL_ 800 RefuelEvent 0 "NONE" 1 "PEND" 2 "TRUE" 3 "COMP" 4 "FAULT" ;
VAL_ 800 RefuelIndication 0 "NONE" 1 "WAIT" 2 "PARK" 3 "OK" 4 "DOOR" ;
VAL_ 308 BARO_ENG 255 "SNA" ;
VAL_ 308 CRUISE_EGD 0 "SNA" ;
VAL_ 308 CRUISE_ON 0 "SNA" ;
VAL_ 308 MAP_ENG 255 "SNA" ;
VAL_ 308 Rel_Pdl_ENG 255 "SNA" ;
VAL_ 308 Rel_Thrt_ENG 255 "SNA" ;
VAL_ 308 V_MAX_TM 255 "SNA" ;
VAL_ 280 StartRelayBCMCmd 0 "SNA" ;
VAL_ 290 GrMax_Rq_ECM 0 "PASSIVE" 1 "G1" 2 "G2" 3 "G3" 4 "G4" 5 "G5" 6 "G6" 7 "G7" ;
VAL_ 290 NMOTS 65535 "SNA" ;
VAL_ 672 DefFuelEcon 255 "SNA" ;
VAL_ 672 ETC_IND_LMP 0 "OFF" 1 "ON" 2 "ON_Flashing" 3 "SNA" ;
VAL_ 672 EngOilIndLmp_On_Rq 1 "SNA" ;
VAL_ 672 EngOilTemp 255 "SNA" ;
VAL_ 672 EngRun_Stat 0 "STOP" 1 "START" 2 "IDLE_UNSTBL" 3 "IDLE_STBL" 4 "UNLIMITED" 5 "LIMITED" 6 "NDEF6" 7 "SNA" ;
VAL_ 672 FuelCons 65535 "SNA" ;
VAL_ 672 OIL_PRESS 255 "SNA" ;
VAL_ 672 OIL_TEMP_CHM_RQ 0 "NO_CHM" 1 "1_CHM" 2 "SLOW_CHM" 3 "FAST_CHM" ;
VAL_ 672 OIL_TEMP_IND_RQ 0 "IND_LMP_OFF" 1 "IND_LMP_ON" 2 "IND_LMP_FLASH" 3 "SNA" ;
VAL_ 257 ECM_SKIM_STAT 0 "OK" 1 "KILL" 2 "RUN" 3 "SNA" ;
VAL_ 257 RAD_FAN1_STAT 255 "SNA" ;
